VERSION ""

NS_ :

BS_:

BU_: WCM4 WCM3 WCM2 WCM VPM VLM VKM VICM VECM VDM VCU_RTOS_ETH VCU_ENTRY_ETH VCU_AGVM_ETH VCU UVM UPM TIM TEST_TOOL_1 TCP_ETH TCP TCM TCCM SRR_SRR_ETH SRR_SRR SRR_SLR_ETH SRR_SLR SRR_RR SRR_RF_ETH SRR_RF SRR_LR_CR SRR_LF_ETH SRR_LF SIB SDM SCL SBZA_R SBZA_L SBM SAM_RR SAM_RF SAM_LR SAM_LF SAM_BH SADS RadioLow_ETH RadioLow RSI_RTOS_ETH RSI RDCM PTM PLCM PFCM PDR_ETH PDR PCM PA ODS2 ODS NVM MTCM_R MTCM_L MSM_RR MSM_P MSM_LR MSM_D MSB2 MSB1 MRCM_R MRCM_L MFC LRR_RR_ETH LRR_LR_ETH LRR_CF_ETH LRR LRL_CF_ETH LIB_48V LIB1 IPC_INT IPC_GP IPC ICS_Info ICCM HVAC_FP_R HVAC_FP_F HUD_CAN HDLM FPI_RTOS_ETH FPI FOPM FCM_LC FCM EPSb EPS_1 EPSRAb EPSRAa EPS EOCM_HC_Superset EOCM_HCP2 EOCM ELM ECP_X1 ECP_S2 ECP_S ECP_MC ECP_H3 ECP_H2 ECP_H1 ECP_E ECM EBCM DMS DEFC DCM CSM_ETH CSM_AV CSM CGM_OTA_ETH CGM BSM_MH BSM_HEV BSM BCM ARS ARB APA AOS AMP ALC AHS AHL_AFL ADIMb ADIMa ACP2_MCU

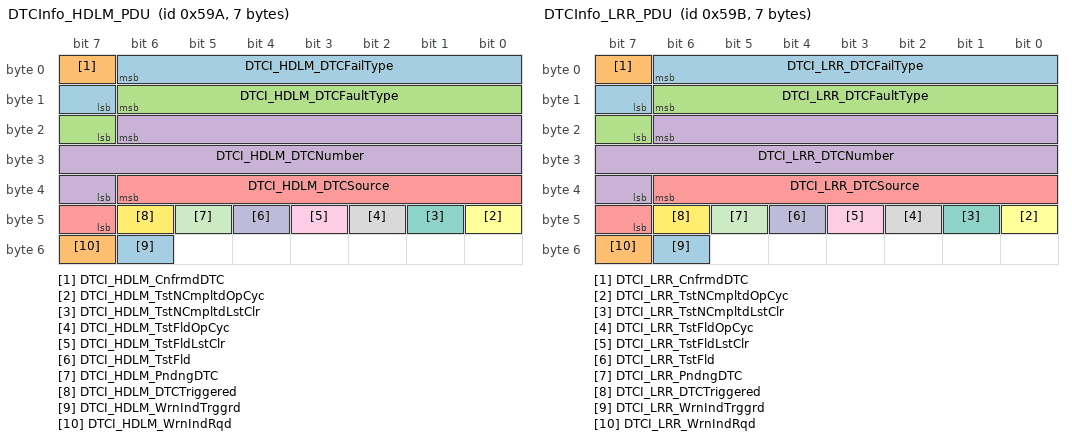
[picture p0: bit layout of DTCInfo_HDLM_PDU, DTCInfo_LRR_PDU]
BO_ 1434 DTCInfo_HDLM_PDU: 7 HDLM
 SG_ DTCI_HDLM_DTCFailType : 6|8@0+ (1,0) [0|255] "" CGM
 SG_ DTCI_HDLM_CnfrmdDTC : 7|1@0+ (1,0) [0|1] "" CGM
 SG_ DTCI_HDLM_DTCFaultType : 14|8@0+ (1,0) [0|3] "" CGM
 SG_ DTCI_HDLM_DTCNumber : 22|16@0+ (1,0) [0|65535] "" CGM
 SG_ DTCI_HDLM_DTCSource : 38|8@0+ (1,0) [0|255] "" CGM
 SG_ DTCI_HDLM_TstNCmpltdOpCyc : 40|1@0+ (1,0) [0|1] "" CGM
 SG_ DTCI_HDLM_TstNCmpltdLstClr : 41|1@0+ (1,0) [0|1] "" CGM
 SG_ DTCI_HDLM_TstFldOpCyc : 42|1@0+ (1,0) [0|1] "" CGM
 SG_ DTCI_HDLM_TstFldLstClr : 43|1@0+ (1,0) [0|1] "" CGM
 SG_ DTCI_HDLM_TstFld : 44|1@0+ (1,0) [0|1] "" CGM
 SG_ DTCI_HDLM_PndngDTC : 45|1@0+ (1,0) [0|1] "" CGM
 SG_ DTCI_HDLM_DTCTriggered : 46|1@0+ (1,0) [0|1] "" CGM
 SG_ DTCI_HDLM_WrnIndTrggrd : 54|1@0+ (1,0) [0|1] "" CGM
 SG_ DTCI_HDLM_WrnIndRqd : 55|1@0+ (1,0) [0|1] "" CGM

BO_ 1435 DTCInfo_LRR_PDU: 7 LRR
 SG_ DTCI_LRR_DTCFailType : 6|8@0+ (1,0) [0|255] "" CGM
 SG_ DTCI_LRR_CnfrmdDTC : 7|1@0+ (1,0) [0|1] "" CGM
 SG_ DTCI_LRR_DTCFaultType : 14|8@0+ (1,0) [0|3] "" CGM
 SG_ DTCI_LRR_DTCNumber : 22|16@0+ (1,0) [0|65535] "" CGM
 SG_ DTCI_LRR_DTCSource : 38|8@0+ (1,0) [0|255] "" CGM
 SG_ DTCI_LRR_TstNCmpltdOpCyc : 40|1@0+ (1,0) [0|1] "" CGM
 SG_ DTCI_LRR_TstNCmpltdLstClr : 41|1@0+ (1,0) [0|1] "" CGM
 SG_ DTCI_LRR_TstFldOpCyc : 42|1@0+ (1,0) [0|1] "" CGM
 SG_ DTCI_LRR_TstFldLstClr : 43|1@0+ (1,0) [0|1] "" CGM
 SG_ DTCI_LRR_TstFld : 44|1@0+ (1,0) [0|1] "" CGM
 SG_ DTCI_LRR_PndngDTC : 45|1@0+ (1,0) [0|1] "" CGM
 SG_ DTCI_LRR_DTCTriggered : 46|1@0+ (1,0) [0|1] "" CGM
 SG_ DTCI_LRR_WrnIndTrggrd : 54|1@0+ (1,0) [0|1] "" CGM
 SG_ DTCI_LRR_WrnIndRqd : 55|1@0+ (1,0) [0|1] "" CGM

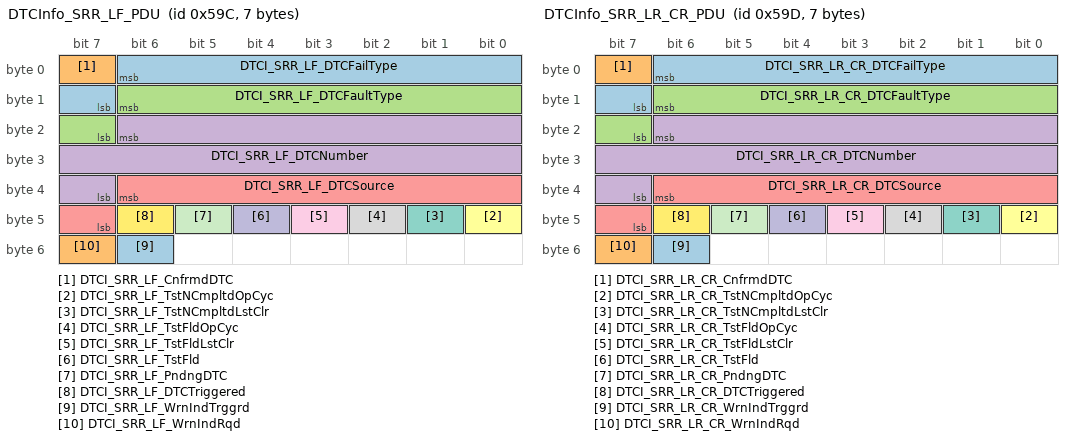
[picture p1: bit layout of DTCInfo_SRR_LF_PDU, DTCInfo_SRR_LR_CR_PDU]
BO_ 1436 DTCInfo_SRR_LF_PDU: 7 SRR_LF
 SG_ DTCI_SRR_LF_DTCFailType : 6|8@0+ (1,0) [0|255] "" CGM
 SG_ DTCI_SRR_LF_CnfrmdDTC : 7|1@0+ (1,0) [0|1] "" CGM
 SG_ DTCI_SRR_LF_DTCFaultType : 14|8@0+ (1,0) [0|3] "" CGM
 SG_ DTCI_SRR_LF_DTCNumber : 22|16@0+ (1,0) [0|65535] "" CGM
 SG_ DTCI_SRR_LF_DTCSource : 38|8@0+ (1,0) [0|255] "" CGM
 SG_ DTCI_SRR_LF_TstNCmpltdOpCyc : 40|1@0+ (1,0) [0|1] "" CGM
 SG_ DTCI_SRR_LF_TstNCmpltdLstClr : 41|1@0+ (1,0) [0|1] "" CGM
 SG_ DTCI_SRR_LF_TstFldOpCyc : 42|1@0+ (1,0) [0|1] "" CGM
 SG_ DTCI_SRR_LF_TstFldLstClr : 43|1@0+ (1,0) [0|1] "" CGM
 SG_ DTCI_SRR_LF_TstFld : 44|1@0+ (1,0) [0|1] "" CGM
 SG_ DTCI_SRR_LF_PndngDTC : 45|1@0+ (1,0) [0|1] "" CGM
 SG_ DTCI_SRR_LF_DTCTriggered : 46|1@0+ (1,0) [0|1] "" CGM
 SG_ DTCI_SRR_LF_WrnIndTrggrd : 54|1@0+ (1,0) [0|1] "" CGM
 SG_ DTCI_SRR_LF_WrnIndRqd : 55|1@0+ (1,0) [0|1] "" CGM

BO_ 1437 DTCInfo_SRR_LR_CR_PDU: 7 SRR_LR_CR
 SG_ DTCI_SRR_LR_CR_DTCFailType : 6|8@0+ (1,0) [0|255] "" CGM
 SG_ DTCI_SRR_LR_CR_CnfrmdDTC : 7|1@0+ (1,0) [0|1] "" CGM
 SG_ DTCI_SRR_LR_CR_DTCFaultType : 14|8@0+ (1,0) [0|3] "" CGM
 SG_ DTCI_SRR_LR_CR_DTCNumber : 22|16@0+ (1,0) [0|65535] "" CGM
 SG_ DTCI_SRR_LR_CR_DTCSource : 38|8@0+ (1,0) [0|255] "" CGM
 SG_ DTCI_SRR_LR_CR_TstNCmpltdOpCyc : 40|1@0+ (1,0) [0|1] "" CGM
 SG_ DTCI_SRR_LR_CR_TstNCmpltdLstClr : 41|1@0+ (1,0) [0|1] "" CGM
 SG_ DTCI_SRR_LR_CR_TstFldOpCyc : 42|1@0+ (1,0) [0|1] "" CGM
 SG_ DTCI_SRR_LR_CR_TstFldLstClr : 43|1@0+ (1,0) [0|1] "" CGM
 SG_ DTCI_SRR_LR_CR_TstFld : 44|1@0+ (1,0) [0|1] "" CGM
 SG_ DTCI_SRR_LR_CR_PndngDTC : 45|1@0+ (1,0) [0|1] "" CGM
 SG_ DTCI_SRR_LR_CR_DTCTriggered : 46|1@0+ (1,0) [0|1] "" CGM
 SG_ DTCI_SRR_LR_CR_WrnIndTrggrd : 54|1@0+ (1,0) [0|1] "" CGM
 SG_ DTCI_SRR_LR_CR_WrnIndRqd : 55|1@0+ (1,0) [0|1] "" CGM

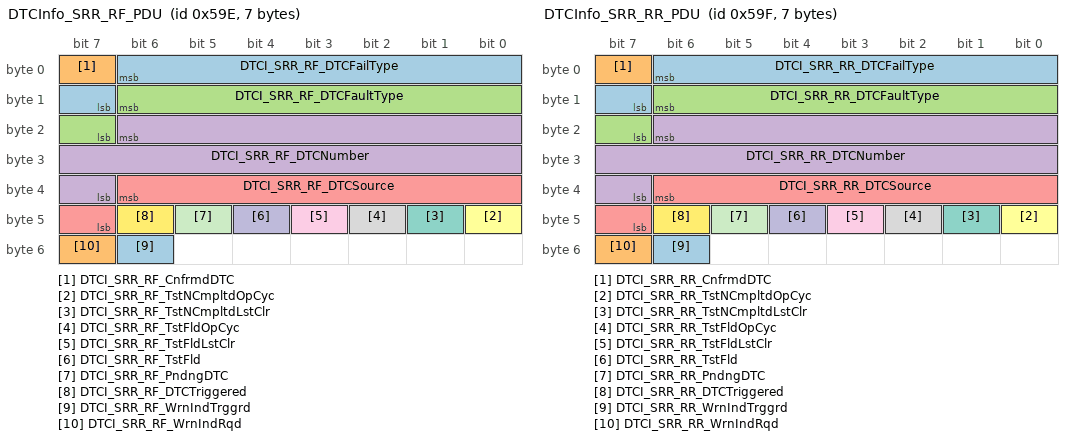
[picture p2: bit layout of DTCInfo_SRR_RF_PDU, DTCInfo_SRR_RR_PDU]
BO_ 1438 DTCInfo_SRR_RF_PDU: 7 SRR_RF
 SG_ DTCI_SRR_RF_DTCFailType : 6|8@0+ (1,0) [0|255] "" CGM
 SG_ DTCI_SRR_RF_CnfrmdDTC : 7|1@0+ (1,0) [0|1] "" CGM
 SG_ DTCI_SRR_RF_DTCFaultType : 14|8@0+ (1,0) [0|3] "" CGM
 SG_ DTCI_SRR_RF_DTCNumber : 22|16@0+ (1,0) [0|65535] "" CGM
 SG_ DTCI_SRR_RF_DTCSource : 38|8@0+ (1,0) [0|255] "" CGM
 SG_ DTCI_SRR_RF_TstNCmpltdOpCyc : 40|1@0+ (1,0) [0|1] "" CGM
 SG_ DTCI_SRR_RF_TstNCmpltdLstClr : 41|1@0+ (1,0) [0|1] "" CGM
 SG_ DTCI_SRR_RF_TstFldOpCyc : 42|1@0+ (1,0) [0|1] "" CGM
 SG_ DTCI_SRR_RF_TstFldLstClr : 43|1@0+ (1,0) [0|1] "" CGM
 SG_ DTCI_SRR_RF_TstFld : 44|1@0+ (1,0) [0|1] "" CGM
 SG_ DTCI_SRR_RF_PndngDTC : 45|1@0+ (1,0) [0|1] "" CGM
 SG_ DTCI_SRR_RF_DTCTriggered : 46|1@0+ (1,0) [0|1] "" CGM
 SG_ DTCI_SRR_RF_WrnIndTrggrd : 54|1@0+ (1,0) [0|1] "" CGM
 SG_ DTCI_SRR_RF_WrnIndRqd : 55|1@0+ (1,0) [0|1] "" CGM

BO_ 1439 DTCInfo_SRR_RR_PDU: 7 SRR_RR
 SG_ DTCI_SRR_RR_DTCFailType : 6|8@0+ (1,0) [0|255] "" CGM
 SG_ DTCI_SRR_RR_CnfrmdDTC : 7|1@0+ (1,0) [0|1] "" CGM
 SG_ DTCI_SRR_RR_DTCFaultType : 14|8@0+ (1,0) [0|3] "" CGM
 SG_ DTCI_SRR_RR_DTCNumber : 22|16@0+ (1,0) [0|65535] "" CGM
 SG_ DTCI_SRR_RR_DTCSource : 38|8@0+ (1,0) [0|255] "" CGM
 SG_ DTCI_SRR_RR_TstNCmpltdOpCyc : 40|1@0+ (1,0) [0|1] "" CGM
 SG_ DTCI_SRR_RR_TstNCmpltdLstClr : 41|1@0+ (1,0) [0|1] "" CGM
 SG_ DTCI_SRR_RR_TstFldOpCyc : 42|1@0+ (1,0) [0|1] "" CGM
 SG_ DTCI_SRR_RR_TstFldLstClr : 43|1@0+ (1,0) [0|1] "" CGM
 SG_ DTCI_SRR_RR_TstFld : 44|1@0+ (1,0) [0|1] "" CGM
 SG_ DTCI_SRR_RR_PndngDTC : 45|1@0+ (1,0) [0|1] "" CGM
 SG_ DTCI_SRR_RR_DTCTriggered : 46|1@0+ (1,0) [0|1] "" CGM
 SG_ DTCI_SRR_RR_WrnIndTrggrd : 54|1@0+ (1,0) [0|1] "" CGM
 SG_ DTCI_SRR_RR_WrnIndRqd : 55|1@0+ (1,0) [0|1] "" CGM

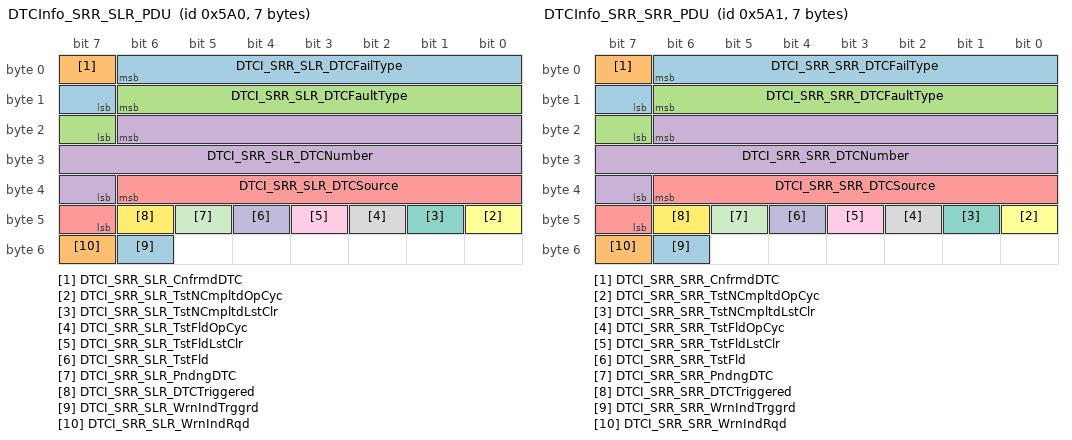
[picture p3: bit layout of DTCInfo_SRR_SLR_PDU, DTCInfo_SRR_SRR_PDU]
BO_ 1440 DTCInfo_SRR_SLR_PDU: 7 SRR_SLR
 SG_ DTCI_SRR_SLR_DTCFailType : 6|8@0+ (1,0) [0|255] "" CGM
 SG_ DTCI_SRR_SLR_CnfrmdDTC : 7|1@0+ (1,0) [0|1] "" CGM
 SG_ DTCI_SRR_SLR_DTCFaultType : 14|8@0+ (1,0) [0|3] "" CGM
 SG_ DTCI_SRR_SLR_DTCNumber : 22|16@0+ (1,0) [0|65535] "" CGM
 SG_ DTCI_SRR_SLR_DTCSource : 38|8@0+ (1,0) [0|255] "" CGM
 SG_ DTCI_SRR_SLR_TstNCmpltdOpCyc : 40|1@0+ (1,0) [0|1] "" CGM
 SG_ DTCI_SRR_SLR_TstNCmpltdLstClr : 41|1@0+ (1,0) [0|1] "" CGM
 SG_ DTCI_SRR_SLR_TstFldOpCyc : 42|1@0+ (1,0) [0|1] "" CGM
 SG_ DTCI_SRR_SLR_TstFldLstClr : 43|1@0+ (1,0) [0|1] "" CGM
 SG_ DTCI_SRR_SLR_TstFld : 44|1@0+ (1,0) [0|1] "" CGM
 SG_ DTCI_SRR_SLR_PndngDTC : 45|1@0+ (1,0) [0|1] "" CGM
 SG_ DTCI_SRR_SLR_DTCTriggered : 46|1@0+ (1,0) [0|1] "" CGM
 SG_ DTCI_SRR_SLR_WrnIndTrggrd : 54|1@0+ (1,0) [0|1] "" CGM
 SG_ DTCI_SRR_SLR_WrnIndRqd : 55|1@0+ (1,0) [0|1] "" CGM

BO_ 1441 DTCInfo_SRR_SRR_PDU: 7 SRR_SRR
 SG_ DTCI_SRR_SRR_DTCFailType : 6|8@0+ (1,0) [0|255] "" CGM
 SG_ DTCI_SRR_SRR_CnfrmdDTC : 7|1@0+ (1,0) [0|1] "" CGM
 SG_ DTCI_SRR_SRR_DTCFaultType : 14|8@0+ (1,0) [0|3] "" CGM
 SG_ DTCI_SRR_SRR_DTCNumber : 22|16@0+ (1,0) [0|65535] "" CGM
 SG_ DTCI_SRR_SRR_DTCSource : 38|8@0+ (1,0) [0|255] "" CGM
 SG_ DTCI_SRR_SRR_TstNCmpltdOpCyc : 40|1@0+ (1,0) [0|1] "" CGM
 SG_ DTCI_SRR_SRR_TstNCmpltdLstClr : 41|1@0+ (1,0) [0|1] "" CGM
 SG_ DTCI_SRR_SRR_TstFldOpCyc : 42|1@0+ (1,0) [0|1] "" CGM
 SG_ DTCI_SRR_SRR_TstFldLstClr : 43|1@0+ (1,0) [0|1] "" CGM
 SG_ DTCI_SRR_SRR_TstFld : 44|1@0+ (1,0) [0|1] "" CGM
 SG_ DTCI_SRR_SRR_PndngDTC : 45|1@0+ (1,0) [0|1] "" CGM
 SG_ DTCI_SRR_SRR_DTCTriggered : 46|1@0+ (1,0) [0|1] "" CGM
 SG_ DTCI_SRR_SRR_WrnIndTrggrd : 54|1@0+ (1,0) [0|1] "" CGM
 SG_ DTCI_SRR_SRR_WrnIndRqd : 55|1@0+ (1,0) [0|1] "" CGM

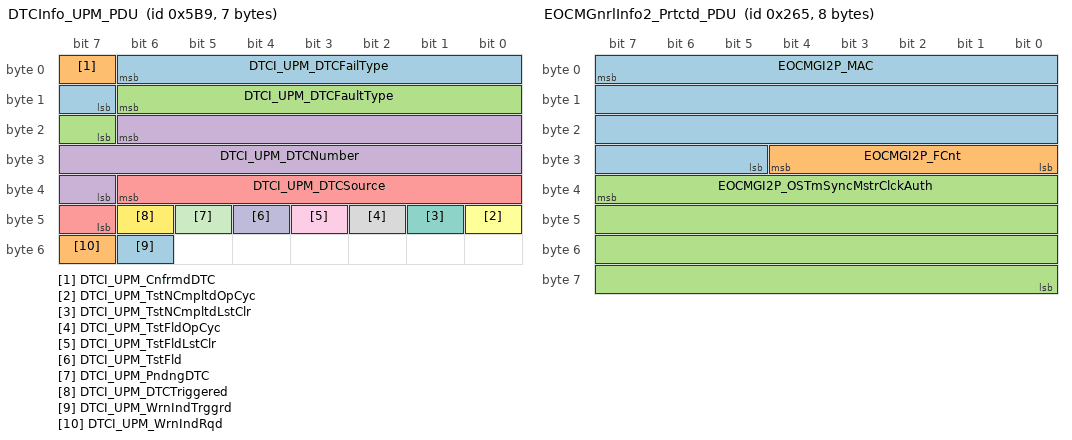
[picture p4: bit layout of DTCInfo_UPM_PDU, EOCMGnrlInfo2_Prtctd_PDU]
BO_ 1465 DTCInfo_UPM_PDU: 7 UPM
 SG_ DTCI_UPM_DTCFailType : 6|8@0+ (1,0) [0|255] "" CGM
 SG_ DTCI_UPM_CnfrmdDTC : 7|1@0+ (1,0) [0|1] "" CGM
 SG_ DTCI_UPM_DTCFaultType : 14|8@0+ (1,0) [0|3] "" CGM
 SG_ DTCI_UPM_DTCNumber : 22|16@0+ (1,0) [0|65535] "" CGM
 SG_ DTCI_UPM_DTCSource : 38|8@0+ (1,0) [0|255] "" CGM
 SG_ DTCI_UPM_TstNCmpltdOpCyc : 40|1@0+ (1,0) [0|1] "" CGM
 SG_ DTCI_UPM_TstNCmpltdLstClr : 41|1@0+ (1,0) [0|1] "" CGM
 SG_ DTCI_UPM_TstFldOpCyc : 42|1@0+ (1,0) [0|1] "" CGM
 SG_ DTCI_UPM_TstFldLstClr : 43|1@0+ (1,0) [0|1] "" CGM
 SG_ DTCI_UPM_TstFld : 44|1@0+ (1,0) [0|1] "" CGM
 SG_ DTCI_UPM_PndngDTC : 45|1@0+ (1,0) [0|1] "" CGM
 SG_ DTCI_UPM_DTCTriggered : 46|1@0+ (1,0) [0|1] "" CGM
 SG_ DTCI_UPM_WrnIndTrggrd : 54|1@0+ (1,0) [0|1] "" CGM
 SG_ DTCI_UPM_WrnIndRqd : 55|1@0+ (1,0) [0|1] "" CGM

BO_ 928 EB_PDU_8000: 1 CGM
 SG_ EASSI_StrtStpSt : 7|2@0+ (1,0) [0|3] "" HDLM

BO_ 1407 EB_PDU_8001: 1 CGM
 SG_ ACCAutoStSpStat : 7|2@0+ (1,0) [0|3] "" FCM_LC

BO_ 705 EB_PDU_8002: 1 CGM
 SG_ EPBSP_ElecPrkBrkApplStsAuth : 7|3@0+ (1,0) [0|4] "" SRR_SLR,SRR_SRR

BO_ 671 EOCMGnrlInfo1_PCSM_PDU: 8 ACP2_MCU
 SG_ EOCMGnrlInfo1_PCSM : 0|64@1+ (1,0) [0|1.84467e+019] "" Vector__XXX

BO_ 528 EOCMGnrlInfo1_Prtctd_PDU: 12 ACP2_MCU
 SG_ FIMRIMABP_MAC : 7|32@0+ (1,0) [0|4.29497e+009] "" CGM
 SG_ FIMRIMABP_FCnt : 39|5@0+ (1,0) [0|31] "" CGM
 SG_ FIMRIMABP_BrkgCtlAccelAuth : 47|12@0+ (0.01,-20.48) [-20.48|20.47] "" CGM
 SG_ FIMRIMABP_BrkgLongAccelReqAuth : 51|9@0- (0.1,0) [-25.6|25.5] "" CGM
 SG_ FIMRIMABP_FIMCISAutBrkRqTypAuth : 57|2@0+ (1,0) [0|2] "" CGM
 SG_ FIMRIMABP_BrkgReqAuth : 58|1@0+ (1,0) [0|1] "" CGM
 SG_ RIMATRP_TrqRqstAuth : 68|16@0- (2,0) [-65536|65534] "" CGM
 SG_ RIMATRP_TrqRqstActAuth : 69|1@0+ (1,0) [0|1] "" CGM
 SG_ FIMRIMABP_ReqActvAuth : 70|1@0+ (1,0) [0|1] "" CGM
 SG_ FIMRIMABP_RIMAutoBrkgReqTypAuth : 71|1@0+ (1,0) [0|1] "" CGM
 SG_ EOCMGI1P_Filler : 82|11@0+ (1,0) [0|2047] "" CGM
 SG_ FIMRIMABP_ARC : 84|2@0+ (1,0) [0|3] "" CGM

BO_ 1401 EOCMGnrlInfo2_PCSM_PDU: 8 ACP2_MCU
 SG_ EOCMGnrlInfo2_PCSM : 0|64@1+ (1,0) [0|1.84467e+019] "" Vector__XXX

BO_ 613 EOCMGnrlInfo2_Prtctd_PDU: 8 ACP2_MCU
 SG_ EOCMGI2P_MAC : 7|27@0+ (1,0) [0|1.34218e+008] "" Vector__XXX
 SG_ EOCMGI2P_FCnt : 28|5@0+ (1,0) [0|31] "" Vector__XXX
 SG_ EOCMGI2P_OSTmSyncMstrClckAuth : 39|32@0+ (1,0) [0|4.29497e+009] "ms" Vector__XXX

BO_ 2147745797 EOCM_CAN8_ClscCANHrtBtActv_PDU: 1 EOCM
 SG_ EOCM_CAN8_ClscCANHrtBtActv : 7|1@0+ (1,0) [0|1] "" CGM

BO_ 2147745798 EOCM_HCP1_CAN8_ClscCANHrtBtActv_: 1 EOCM_HC_Superset
 SG_ EOCM_HCP1_CAN8_ClscCANHrtBtActv : 7|1@0+ (1,0) [0|1] "" CGM

BO_ 2147745808 EOCM_HCP2_CAN8_ClscCANHrtBtActv_: 1 EOCM_HCP2
 SG_ EOCM_HCP2_CAN8_ClscCANHrtBtActv : 7|1@0+ (1,0) [0|1] "" CGM

BO_ 2147745809 FCM_LC_CAN8_ClscCANHrtBtActv_PDU: 1 FCM_LC
 SG_ FCM_LC_CAN8_ClscCANHrtBtActv : 7|1@0+ (1,0) [0|1] "" CGM

BO_ 658 FCODP_BrstGrp_PCSM_PDU: 8 ACP2_MCU
 SG_ FCODP_BrstGrp1_PCSM : 0|64@1+ (1,0) [0|1.84467e+019] "" EOCM,EOCM_HCP2,EOCM_HC_Superset,HDLM

BO_ 238 FCODP_BrstGrp_Prtctd_Consecutive: 64 ACP2_MCU
 SG_ FCODPB11P_FVVOTk10PoI4LgPsAuth : 5|11@0+ (0.125,0) [0|255.875] "m" EOCM,EOCM_HCP2,EOCM_HC_Superset,HDLM
 SG_ FCODPB11P_BrstID : 7|2@0+ (1,0) [0|3] "" EOCM,EOCM_HCP2,EOCM_HC_Superset,HDLM
 SG_ FCODPB11P_FVVOTk10PoI4LPsAuth : 10|10@0+ (0.125,-64) [-64|63.875] "m" EOCM,EOCM_HCP2,EOCM_HC_Superset,HDLM
 SG_ FCODPB11P_FVVOTk10PoI4PsVisAuth : 16|2@0+ (1,0) [0|2] "" EOCM,EOCM_HCP2,EOCM_HC_Superset,HDLM
 SG_ FCODPB11P_FVVOTk1PoI4LgPsAuth : 30|11@0+ (0.125,0) [0|255.875] "m" EOCM,EOCM_HCP2,EOCM_HC_Superset,HDLM
 SG_ FCODPB11P_FVVOTk1PoI4LPsAuth : 35|10@0+ (0.125,-64) [-64|63.875] "m" EOCM,EOCM_HCP2,EOCM_HC_Superset,HDLM
 SG_ FCODPB11P_FVVOTk1PoI4PsVisAuth : 41|2@0+ (1,0) [0|2] "" EOCM,EOCM_HCP2,EOCM_HC_Superset,HDLM
 SG_ FCODPB11P_FVVOTk2PoI4LgPsAuth : 55|11@0+ (0.125,0) [0|255.875] "m" EOCM,EOCM_HCP2,EOCM_HC_Superset,HDLM
 SG_ FCODPB11P_FVVOTk2PoI4LPsAuth : 60|10@0+ (0.125,-64) [-64|63.875] "m" EOCM,EOCM_HCP2,EOCM_HC_Superset,HDLM
 SG_ FCODPB11P_FVVOTk3PoI4LgPsAuth : 64|11@0+ (0.125,0) [0|255.875] "m" EOCM,EOCM_HCP2,EOCM_HC_Superset,HDLM
 SG_ FCODPB11P_FVVOTk2PoI4PsVisAuth : 66|2@0+ (1,0) [0|2] "" EOCM,EOCM_HCP2,EOCM_HC_Superset,HDLM
 SG_ FCODPB11P_FVVOTk3PoI4LPsAuth : 85|10@0+ (0.125,-64) [-64|63.875] "m" EOCM,EOCM_HCP2,EOCM_HC_Superset,HDLM
 SG_ FCODPB11P_FVVOTk4PoI4LgPsAuth : 89|11@0+ (0.125,0) [0|255.875] "m" EOCM,EOCM_HCP2,EOCM_HC_Superset,HDLM
 SG_ FCODPB11P_FVVOTk3PoI4PsVisAuth : 91|2@0+ (1,0) [0|2] "" EOCM,EOCM_HCP2,EOCM_HC_Superset,HDLM
 SG_ FCODPB11P_FVVOTk4PoI4LPsAuth : 110|10@0+ (0.125,-64) [-64|63.875] "m" EOCM,EOCM_HCP2,EOCM_HC_Superset,HDLM
 SG_ FCODPB11P_FVVOTk5PoI4LgPsAuth : 114|11@0+ (0.125,0) [0|255.875] "m" EOCM,EOCM_HCP2,EOCM_HC_Superset,HDLM
 SG_ FCODPB11P_FVVOTk4PoI4PsVisAuth : 116|2@0+ (1,0) [0|2] "" EOCM,EOCM_HCP2,EOCM_HC_Superset,HDLM
 SG_ FCODPB11P_FVVOTk5PoI4LPsAuth : 135|10@0+ (0.125,-64) [-64|63.875] "m" EOCM,EOCM_HCP2,EOCM_HC_Superset,HDLM
 SG_ FCODPB11P_FVVOTk6PoI4LgPsAuth : 139|11@0+ (0.125,0) [0|255.875] "m" EOCM,EOCM_HCP2,EOCM_HC_Superset,HDLM
 SG_ FCODPB11P_FVVOTk5PoI4PsVisAuth : 141|2@0+ (1,0) [0|2] "" EOCM,EOCM_HCP2,EOCM_HC_Superset,HDLM
 SG_ FCODPB11P_FVVOTk6PoI4LPsAuth : 144|10@0+ (0.125,-64) [-64|63.875] "m" EOCM,EOCM_HCP2,EOCM_HC_Superset,HDLM
 SG_ FCODPB11P_FVVOTk7PoI4LgPsAuth : 164|11@0+ (0.125,0) [0|255.875] "m" EOCM,EOCM_HCP2,EOCM_HC_Superset,HDLM
 SG_ FCODPB11P_FVVOTk6PoI4PsVisAuth : 166|2@0+ (1,0) [0|2] "" EOCM,EOCM_HCP2,EOCM_HC_Superset,HDLM
 SG_ FCODPB11P_FVVOTk7PoI4LPsAuth : 169|10@0+ (0.125,-64) [-64|63.875] "m" EOCM,EOCM_HCP2,EOCM_HC_Superset,HDLM
 SG_ FCODPB11P_FVVOTk8PoI4LgPsAuth : 189|11@0+ (0.125,0) [0|255.875] "m" EOCM,EOCM_HCP2,EOCM_HC_Superset,HDLM
 SG_ FCODPB11P_FVVOTk7PoI4PsVisAuth : 191|2@0+ (1,0) [0|2] "" EOCM,EOCM_HCP2,EOCM_HC_Superset,HDLM
 SG_ FCODPB11P_FVVOTk8PoI4LPsAuth : 194|10@0+ (0.125,-64) [-64|63.875] "m" EOCM,EOCM_HCP2,EOCM_HC_Superset,HDLM
 SG_ FCODPB11P_FVVOTk8PoI4PsVisAuth : 200|2@0+ (1,0) [0|2] "" EOCM,EOCM_HCP2,EOCM_HC_Superset,HDLM
 SG_ FCODPB11P_FVVOTk9PoI4LgPsAuth : 214|11@0+ (0.125,0) [0|255.875] "m" EOCM,EOCM_HCP2,EOCM_HC_Superset,HDLM
 SG_ FCODPB11P_FVVOTk9PoI4LPsAuth : 219|10@0+ (0.125,-64) [-64|63.875] "m" EOCM,EOCM_HCP2,EOCM_HC_Superset,HDLM
 SG_ FCODPB11P_FVVOTk9PoI4PsVisAuth : 225|2@0+ (1,0) [0|2] "" EOCM,EOCM_HCP2,EOCM_HC_Superset,HDLM
 SG_ FCODPB11P_LnTrPtEndLatDistAuth : 239|12@0- (0.01,0) [-20.48|20.47] "m" EOCM,EOCM_HCP2,EOCM_HC_Superset,HDLM
 SG_ FCODPB11P_LnTrPtEndLngDistAuth : 243|14@0+ (0.01,0) [0|163.83] "m" EOCM,EOCM_HCP2,EOCM_HC_Superset,HDLM
 SG_ FCODPB11P_LnTrPtStrtLatDistAuth : 259|12@0- (0.01,0) [-20.48|20.47] "m" EOCM,EOCM_HCP2,EOCM_HC_Superset,HDLM
 SG_ FCODPB11P_LnTrPtEndTypAuth : 261|2@0+ (1,0) [0|2] "" EOCM,EOCM_HCP2,EOCM_HC_Superset,HDLM
 SG_ FCODPB11P_LnTrPtStrtLngDistAuth : 279|14@0+ (0.01,0) [0|163.83] "m" EOCM,EOCM_HCP2,EOCM_HC_Superset,HDLM
 SG_ FCODPB11P_LnTrPtStrtTypAuth : 281|2@0+ (1,0) [0|2] "" EOCM,EOCM_HCP2,EOCM_HC_Superset,HDLM
 SG_ FCODPB11P_RdVertPP10LngDistAuth : 292|10@0+ (0.125,0) [0|127.875] "m" EOCM,EOCM_HCP2,EOCM_HC_Superset,HDLM
 SG_ FCODPB11P_FrwdVsnModeCmdStsAuth : 293|1@0+ (1,0) [0|1] "" EOCM,EOCM_HCP2,EOCM_HC_Superset,HDLM
 SG_ FCODPB11P_LnTrPtSyncIdxAuth : 295|2@0+ (1,0) [0|3] "" EOCM,EOCM_HCP2,EOCM_HC_Superset,HDLM
 SG_ FCODPB11P_RdVertPP11LngDistAuth : 298|10@0+ (0.125,0) [0|127.875] "m" EOCM,EOCM_HCP2,EOCM_HC_Superset,HDLM
 SG_ FCODPB11P_RdVertPP12LngDistAuth : 304|10@0+ (0.125,0) [0|127.875] "m" EOCM,EOCM_HCP2,EOCM_HC_Superset,HDLM
 SG_ FCODPB11P_RdVertPP13LngDistAuth : 326|10@0+ (0.125,0) [0|127.875] "m" EOCM,EOCM_HCP2,EOCM_HC_Superset,HDLM
 SG_ FCODPB11P_RdVertPP14LngDistAuth : 332|10@0+ (0.125,0) [0|127.875] "m" EOCM,EOCM_HCP2,EOCM_HC_Superset,HDLM
 SG_ FCODPB11P_RdVertPP15LngDistAuth : 338|10@0+ (0.125,0) [0|127.875] "m" EOCM,EOCM_HCP2,EOCM_HC_Superset,HDLM
 SG_ FCODPB11P_RdVertPP1LngDistAuth : 344|10@0+ (0.125,0) [0|127.875] "m" EOCM,EOCM_HCP2,EOCM_HC_Superset,HDLM
 SG_ FCODPB11P_RdVertPP2LngDistAuth : 366|10@0+ (0.125,0) [0|127.875] "m" EOCM,EOCM_HCP2,EOCM_HC_Superset,HDLM
 SG_ FCODPB11P_RdVertPP3LngDistAuth : 372|10@0+ (0.125,0) [0|127.875] "m" EOCM,EOCM_HCP2,EOCM_HC_Superset,HDLM
 SG_ FCODPB11P_RdVertPP4LngDistAuth : 378|10@0+ (0.125,0) [0|127.875] "m" EOCM,EOCM_HCP2,EOCM_HC_Superset,HDLM
 SG_ FCODPB11P_RdVertPP5LngDistAuth : 384|10@0+ (0.125,0) [0|127.875] "m" EOCM,EOCM_HCP2,EOCM_HC_Superset,HDLM
 SG_ FCODPB11P_RdVertPP6LngDistAuth : 406|10@0+ (0.125,0) [0|127.875] "m" EOCM,EOCM_HCP2,EOCM_HC_Superset,HDLM
 SG_ FCODPB11P_RdVertPP7LngDistAuth : 412|10@0+ (0.125,0) [0|127.875] "m" EOCM,EOCM_HCP2,EOCM_HC_Superset,HDLM
 SG_ FCODPB11P_RdVertPP8LngDistAuth : 418|10@0+ (0.125,0) [0|127.875] "m" EOCM,EOCM_HCP2,EOCM_HC_Superset,HDLM
 SG_ FCODPB11P_RdVertPP9LngDistAuth : 424|10@0+ (0.125,0) [0|127.875] "m" EOCM,EOCM_HCP2,EOCM_HC_Superset,HDLM
 SG_ FCODPB11P_Filler : 440|30@0+ (1,0) [0|1.07374e+009] "" EOCM,EOCM_HCP2,EOCM_HC_Superset,HDLM
 SG_ FrwdVsnLnBdryTk11DatIntegCkd : 442|2@0+ (1,0) [0|2] "" EOCM,EOCM_HCP2,EOCM_HC_Superset,HDLM
 SG_ FCODPB11P_ShldrDtnRtofVehAuth : 444|2@0+ (1,0) [0|3] "" EOCM,EOCM_HCP2,EOCM_HC_Superset,HDLM
 SG_ FCODPB11P_ShldrDtnLtofVehAuth : 446|2@0+ (1,0) [0|3] "" EOCM,EOCM_HCP2,EOCM_HC_Superset,HDLM
 SG_ FCODPB11P_FillerExtnd : 474|32@0+ (1,0) [0|4.29497e+009] "" EOCM,EOCM_HCP2,EOCM_HC_Superset,HDLM
 SG_ FCODPB11P_FillerExtnd1 : 506|3@0+ (1,0) [0|7] "0" EOCM,EOCM_HCP2,EOCM_HC_Superset,HDLM

BO_ 217 FCODP_BrstGrp_Prtctd_Consecuti01: 64 ACP2_MCU
 SG_ FCODPB12P_FVTS1AgeAuth : 5|8@0+ (1,0) [0|255] "Frames" EOCM,EOCM_HCP2,EOCM_HC_Superset,HDLM
 SG_ FCODPB12P_BrstID : 7|2@0+ (1,0) [0|3] "" EOCM,EOCM_HCP2,EOCM_HC_Superset,HDLM
 SG_ FCODPB12P_FVTS1PsdbyHstVehAuth : 8|1@0+ (1,0) [0|1] "" EOCM,EOCM_HCP2,EOCM_HC_Superset,HDLM
 SG_ FCODPB12P_FVTS1PhysTypAuth : 10|2@0+ (1,0) [0|2] "" EOCM,EOCM_HCP2,EOCM_HC_Superset,HDLM
 SG_ FCODPB12P_FVTS1MeasVldAuth : 11|1@0+ (1,0) [0|1] "" EOCM,EOCM_HCP2,EOCM_HC_Superset,HDLM
 SG_ FCODPB12P_FVTS1FiltTypAuth : 13|2@0+ (1,0) [0|3] "" EOCM,EOCM_HCP2,EOCM_HC_Superset,HDLM
 SG_ FCODPB12P_FVTS2AgeAuth : 22|8@0+ (1,0) [0|255] "Frames" EOCM,EOCM_HCP2,EOCM_HC_Superset,HDLM
 SG_ FCODPB12P_FVTS1ZnDtdAuth : 23|1@0+ (1,0) [0|1] "" EOCM,EOCM_HCP2,EOCM_HC_Superset,HDLM
 SG_ FCODPB12P_FVTS2ZnDtdAuth : 24|1@0+ (1,0) [0|1] "" EOCM,EOCM_HCP2,EOCM_HC_Superset,HDLM
 SG_ FCODPB12P_FVTS2PsdbyHstVehAuth : 25|1@0+ (1,0) [0|1] "" EOCM,EOCM_HCP2,EOCM_HC_Superset,HDLM
 SG_ FCODPB12P_FVTS2PhysTypAuth : 27|2@0+ (1,0) [0|2] "" EOCM,EOCM_HCP2,EOCM_HC_Superset,HDLM
 SG_ FCODPB12P_FVTS2MeasVldAuth : 28|1@0+ (1,0) [0|1] "" EOCM,EOCM_HCP2,EOCM_HC_Superset,HDLM
 SG_ FCODPB12P_FVTS2FiltTypAuth : 30|2@0+ (1,0) [0|3] "" EOCM,EOCM_HCP2,EOCM_HC_Superset,HDLM
 SG_ FCODPB12P_FVTS3AgeAuth : 39|8@0+ (1,0) [0|255] "Frames" EOCM,EOCM_HCP2,EOCM_HC_Superset,HDLM
 SG_ FCODPB12P_FVTS4AgeAuth : 40|8@0+ (1,0) [0|255] "Frames" EOCM,EOCM_HCP2,EOCM_HC_Superset,HDLM
 SG_ FCODPB12P_FVTS3ZnDtdAuth : 41|1@0+ (1,0) [0|1] "" EOCM,EOCM_HCP2,EOCM_HC_Superset,HDLM
 SG_ FCODPB12P_FVTS3PsdbyHstVehAuth : 42|1@0+ (1,0) [0|1] "" EOCM,EOCM_HCP2,EOCM_HC_Superset,HDLM
 SG_ FCODPB12P_FVTS3PhysTypAuth : 44|2@0+ (1,0) [0|2] "" EOCM,EOCM_HCP2,EOCM_HC_Superset,HDLM
 SG_ FCODPB12P_FVTS3MeasVldAuth : 45|1@0+ (1,0) [0|1] "" EOCM,EOCM_HCP2,EOCM_HC_Superset,HDLM
 SG_ FCODPB12P_FVTS3FiltTypAuth : 47|2@0+ (1,0) [0|3] "" EOCM,EOCM_HCP2,EOCM_HC_Superset,HDLM
 SG_ FCODPB12P_FVTS4FiltTypAuth : 48|2@0+ (1,0) [0|3] "" EOCM,EOCM_HCP2,EOCM_HC_Superset,HDLM
 SG_ FCODPB12P_FVTS5AgeAuth : 57|8@0+ (1,0) [0|255] "Frames" EOCM,EOCM_HCP2,EOCM_HC_Superset,HDLM
 SG_ FCODPB12P_FVTS4ZnDtdAuth : 58|1@0+ (1,0) [0|1] "" EOCM,EOCM_HCP2,EOCM_HC_Superset,HDLM
 SG_ FCODPB12P_FVTS4PsdbyHstVehAuth : 59|1@0+ (1,0) [0|1] "" EOCM,EOCM_HCP2,EOCM_HC_Superset,HDLM
 SG_ FCODPB12P_FVTS4PhysTypAuth : 61|2@0+ (1,0) [0|2] "" EOCM,EOCM_HCP2,EOCM_HC_Superset,HDLM
 SG_ FCODPB12P_FVTS4MeasVldAuth : 62|1@0+ (1,0) [0|1] "" EOCM,EOCM_HCP2,EOCM_HC_Superset,HDLM
 SG_ FCODPB12P_FVTS5FiltTypAuth : 65|2@0+ (1,0) [0|3] "" EOCM,EOCM_HCP2,EOCM_HC_Superset,HDLM
 SG_ FCODPB12P_FVTS6AgeAuth : 74|8@0+ (1,0) [0|255] "Frames" EOCM,EOCM_HCP2,EOCM_HC_Superset,HDLM
 SG_ FCODPB12P_FVTS5ZnDtdAuth : 75|1@0+ (1,0) [0|1] "" EOCM,EOCM_HCP2,EOCM_HC_Superset,HDLM
 SG_ FCODPB12P_FVTS5PsdbyHstVehAuth : 76|1@0+ (1,0) [0|1] "" EOCM,EOCM_HCP2,EOCM_HC_Superset,HDLM
 SG_ FCODPB12P_FVTS5PhysTypAuth : 78|2@0+ (1,0) [0|2] "" EOCM,EOCM_HCP2,EOCM_HC_Superset,HDLM
 SG_ FCODPB12P_FVTS5MeasVldAuth : 79|1@0+ (1,0) [0|1] "" EOCM,EOCM_HCP2,EOCM_HC_Superset,HDLM
 SG_ FCODPB12P_FVTS6MeasVldAuth : 80|1@0+ (1,0) [0|1] "" EOCM,EOCM_HCP2,EOCM_HC_Superset,HDLM
 SG_ FCODPB12P_FVTS6FiltTypAuth : 82|2@0+ (1,0) [0|3] "" EOCM,EOCM_HCP2,EOCM_HC_Superset,HDLM
 SG_ FCODPB12P_RdBnkCrv1CrvAuth : 89|16@0- (9.77e-07,0) [-0.0320143|0.0320134] "1/m" EOCM,EOCM_HCP2,EOCM_HC_Superset,HDLM
 SG_ FCODPB12P_RdBnkCrv1CnfdStsAuth : 91|2@0+ (1,0) [0|3] "" EOCM,EOCM_HCP2,EOCM_HC_Superset,HDLM
 SG_ FCODPB12P_FVTS6ZnDtdAuth : 92|1@0+ (1,0) [0|1] "" EOCM,EOCM_HCP2,EOCM_HC_Superset,HDLM
 SG_ FCODPB12P_FVTS6PsdbyHstVehAuth : 93|1@0+ (1,0) [0|1] "" EOCM,EOCM_HCP2,EOCM_HC_Superset,HDLM
 SG_ FCODPB12P_FVTS6PhysTypAuth : 95|2@0+ (1,0) [0|2] "" EOCM,EOCM_HCP2,EOCM_HC_Superset,HDLM
 SG_ FCODPB12P_RdBnkCrv1CrvDrvtAuth : 105|16@0- (3.73e-09,0) [-0.000122225|0.000122221] "1/m2" EOCM,EOCM_HCP2,EOCM_HC_Superset,HDLM
 SG_ FCODPB12P_RdBnkCrv1HdgAuth : 121|10@0- (0.000977,0) [-0.500224|0.499247] "rad" EOCM,EOCM_HCP2,EOCM_HC_Superset,HDLM
 SG_ FCODPB12P_RdBnkCrv1LatOfstAuth : 143|8@0- (0.125,0) [-16|15.875] "m" EOCM,EOCM_HCP2,EOCM_HC_Superset,HDLM
 SG_ FCODPB12P_RdBnkCrv1LngOfstAuth : 151|10@0+ (0.125,0) [0|127.875] "m" EOCM,EOCM_HCP2,EOCM_HC_Superset,HDLM
 SG_ FCODPB12P_RdBnkCrv1PsEndAuth : 157|8@0- (0.125,0) [-16|15.875] "m" EOCM,EOCM_HCP2,EOCM_HC_Superset,HDLM
 SG_ FCODPB12P_RdBnkCrv1PsStrtAuth : 165|8@0- (0.125,0) [-16|15.875] "m" EOCM,EOCM_HCP2,EOCM_HC_Superset,HDLM
 SG_ FCODPB12P_RdBnkCrv2CrvAuth : 171|16@0- (9.77e-07,0) [-0.0320143|0.0320134] "1/m" EOCM,EOCM_HCP2,EOCM_HC_Superset,HDLM
 SG_ FCODPB12P_RdBnkCrv2CnfdStsAuth : 173|2@0+ (1,0) [0|3] "" EOCM,EOCM_HCP2,EOCM_HC_Superset,HDLM
 SG_ FCODPB12P_RdBnkCrv2CrvDrvtAuth : 187|16@0- (3.73e-09,0) [-0.000122225|0.000122221] "1/m2" EOCM,EOCM_HCP2,EOCM_HC_Superset,HDLM
 SG_ FCODPB12P_RdBnkCrv2HdgAuth : 203|10@0- (0.000977,0) [-0.500224|0.499247] "rad" EOCM,EOCM_HCP2,EOCM_HC_Superset,HDLM
 SG_ FCODPB12P_RdBnkCrv2LatOfstAuth : 209|8@0- (0.125,0) [-16|15.875] "m" EOCM,EOCM_HCP2,EOCM_HC_Superset,HDLM
 SG_ FCODPB12P_RdBnkCrv2LngOfstAuth : 217|10@0+ (0.125,0) [0|127.875] "m" EOCM,EOCM_HCP2,EOCM_HC_Superset,HDLM
 SG_ FCODPB12P_RdBnkCrv2PsEndAuth : 239|8@0- (0.125,0) [-16|15.875] "m" EOCM,EOCM_HCP2,EOCM_HC_Superset,HDLM
 SG_ FCODPB12P_RdBnkCrv2PsStrtAuth : 247|8@0- (0.125,0) [-16|15.875] "m" EOCM,EOCM_HCP2,EOCM_HC_Superset,HDLM
 SG_ FCODPB12P_RdBnkCrv3CrvAuth : 253|16@0- (9.77e-07,0) [-0.0320143|0.0320134] "1/m" EOCM,EOCM_HCP2,EOCM_HC_Superset,HDLM
 SG_ FCODPB12P_RdBnkCrv3CnfdStsAuth : 255|2@0+ (1,0) [0|3] "" EOCM,EOCM_HCP2,EOCM_HC_Superset,HDLM
 SG_ FCODPB12P_RdBnkCrv3CrvDrvtAuth : 269|16@0- (3.73e-09,0) [-0.000122225|0.000122221] "1/m2" EOCM,EOCM_HCP2,EOCM_HC_Superset,HDLM
 SG_ FCODPB12P_RdBnkCrv3HdgAuth : 285|10@0- (0.000977,0) [-0.500224|0.499247] "rad" EOCM,EOCM_HCP2,EOCM_HC_Superset,HDLM
 SG_ FCODPB12P_RdBnkCrv3LatOfstAuth : 291|8@0- (0.125,0) [-16|15.875] "m" EOCM,EOCM_HCP2,EOCM_HC_Superset,HDLM
 SG_ FCODPB12P_RdBnkCrv3LngOfstAuth : 299|10@0+ (0.125,0) [0|127.875] "m" EOCM,EOCM_HCP2,EOCM_HC_Superset,HDLM
 SG_ FCODPB12P_RdBnkCrv3PsEndAuth : 305|8@0- (0.125,0) [-16|15.875] "m" EOCM,EOCM_HCP2,EOCM_HC_Superset,HDLM
 SG_ FCODPB12P_RdBnkCrv3PsStrtAuth : 313|8@0- (0.125,0) [-16|15.875] "m" EOCM,EOCM_HCP2,EOCM_HC_Superset,HDLM
 SG_ FCODPB12P_RdVertPP10ElvtnAuth : 321|10@0- (0.125,0) [-64|63.875] "m" EOCM,EOCM_HCP2,EOCM_HC_Superset,HDLM
 SG_ FCODPB12P_RdVertPP11ElvtnAuth : 343|10@0- (0.125,0) [-64|63.875] "m" EOCM,EOCM_HCP2,EOCM_HC_Superset,HDLM
 SG_ FCODPB12P_RdVertPP12ElvtnAuth : 349|10@0- (0.125,0) [-64|63.875] "m" EOCM,EOCM_HCP2,EOCM_HC_Superset,HDLM
 SG_ FCODPB12P_RdVertPP13ElvtnAuth : 355|10@0- (0.125,0) [-64|63.875] "m" EOCM,EOCM_HCP2,EOCM_HC_Superset,HDLM
 SG_ FCODPB12P_RdVertPP14ElvtnAuth : 361|10@0- (0.125,0) [-64|63.875] "m" EOCM,EOCM_HCP2,EOCM_HC_Superset,HDLM
 SG_ FCODPB12P_RdVertPP15ElvtnAuth : 383|10@0- (0.125,0) [-64|63.875] "m" EOCM,EOCM_HCP2,EOCM_HC_Superset,HDLM
 SG_ FCODPB12P_RdVertPP1ElvtnAuth : 389|10@0- (0.125,0) [-64|63.875] "m" EOCM,EOCM_HCP2,EOCM_HC_Superset,HDLM
 SG_ FCODPB12P_RdVertPP2ElvtnAuth : 395|10@0- (0.125,0) [-64|63.875] "m" EOCM,EOCM_HCP2,EOCM_HC_Superset,HDLM
 SG_ FCODPB12P_RdVertPP3ElvtnAuth : 401|10@0- (0.125,0) [-64|63.875] "m" EOCM,EOCM_HCP2,EOCM_HC_Superset,HDLM
 SG_ FCODPB12P_RdVertPP4ElvtnAuth : 423|10@0- (0.125,0) [-64|63.875] "m" EOCM,EOCM_HCP2,EOCM_HC_Superset,HDLM
 SG_ FCODPB12P_RdVertPP5ElvtnAuth : 429|10@0- (0.125,0) [-64|63.875] "m" EOCM,EOCM_HCP2,EOCM_HC_Superset,HDLM
 SG_ FCODPB12P_RdVertPP6ElvtnAuth : 435|10@0- (0.125,0) [-64|63.875] "m" EOCM,EOCM_HCP2,EOCM_HC_Superset,HDLM
 SG_ FCODPB12P_RdVertPP7ElvtnAuth : 441|10@0- (0.125,0) [-64|63.875] "m" EOCM,EOCM_HCP2,EOCM_HC_Superset,HDLM
 SG_ FCODPB12P_RdVertPP8ElvtnAuth : 463|10@0- (0.125,0) [-64|63.875] "m" EOCM,EOCM_HCP2,EOCM_HC_Superset,HDLM
 SG_ FCODPB12P_RdVertPP9ElvtnAuth : 469|10@0- (0.125,0) [-64|63.875] "m" EOCM,EOCM_HCP2,EOCM_HC_Superset,HDLM
 SG_ FCODPB12P_Filler : 475|32@0+ (1,0) [0|4.29497e+009] "" EOCM,EOCM_HCP2,EOCM_HC_Superset,HDLM
 SG_ FCODPB12P_FillerExtnd : 507|4@0+ (1,0) [0|15] "" EOCM,EOCM_HCP2,EOCM_HC_Superset,HDLM

BO_ 239 FCODP_BrstGrp_Prtctd_Consecuti02: 64 ACP2_MCU
 SG_ FCODPB13P_FVTS10AgeAuth : 5|8@0+ (1,0) [0|255] "Frames" EOCM,EOCM_HCP2,EOCM_HC_Superset,HDLM
 SG_ FCODPB13P_BrstID : 7|2@0+ (1,0) [0|3] "" EOCM,EOCM_HCP2,EOCM_HC_Superset,HDLM
 SG_ FCODPB13P_FVTS10PsdbyHstVehAuth : 8|1@0+ (1,0) [0|1] "" EOCM,EOCM_HCP2,EOCM_HC_Superset,HDLM
 SG_ FCODPB13P_FVTS10PhysTypAuth : 10|2@0+ (1,0) [0|2] "" EOCM,EOCM_HCP2,EOCM_HC_Superset,HDLM
 SG_ FCODPB13P_FVTS10MeasVldAuth : 11|1@0+ (1,0) [0|1] "" EOCM,EOCM_HCP2,EOCM_HC_Superset,HDLM
 SG_ FCODPB13P_FVTS10FiltTypAuth : 13|2@0+ (1,0) [0|3] "" EOCM,EOCM_HCP2,EOCM_HC_Superset,HDLM
 SG_ FCODPB13P_FVTS7AgeAuth : 22|8@0+ (1,0) [0|255] "Frames" EOCM,EOCM_HCP2,EOCM_HC_Superset,HDLM
 SG_ FCODPB13P_FVTS10ZnDtdAuth : 23|1@0+ (1,0) [0|1] "" EOCM,EOCM_HCP2,EOCM_HC_Superset,HDLM
 SG_ FCODPB13P_FVTS7ZnDtdAuth : 24|1@0+ (1,0) [0|1] "" EOCM,EOCM_HCP2,EOCM_HC_Superset,HDLM
 SG_ FCODPB13P_FVTS7PsdbyHstVehAuth : 25|1@0+ (1,0) [0|1] "" EOCM,EOCM_HCP2,EOCM_HC_Superset,HDLM
 SG_ FCODPB13P_FVTS7PhysTypAuth : 27|2@0+ (1,0) [0|2] "" EOCM,EOCM_HCP2,EOCM_HC_Superset,HDLM
 SG_ FCODPB13P_FVTS7MeasVldAuth : 28|1@0+ (1,0) [0|1] "" EOCM,EOCM_HCP2,EOCM_HC_Superset,HDLM
 SG_ FCODPB13P_FVTS7FiltTypAuth : 30|2@0+ (1,0) [0|3] "" EOCM,EOCM_HCP2,EOCM_HC_Superset,HDLM
 SG_ FCODPB13P_FVTS8AgeAuth : 39|8@0+ (1,0) [0|255] "Frames" EOCM,EOCM_HCP2,EOCM_HC_Superset,HDLM
 SG_ FCODPB13P_FVTS9AgeAuth : 40|8@0+ (1,0) [0|255] "Frames" EOCM,EOCM_HCP2,EOCM_HC_Superset,HDLM
 SG_ FCODPB13P_FVTS8ZnDtdAuth : 41|1@0+ (1,0) [0|1] "" EOCM,EOCM_HCP2,EOCM_HC_Superset,HDLM
 SG_ FCODPB13P_FVTS8PsdbyHstVehAuth : 42|1@0+ (1,0) [0|1] "" EOCM,EOCM_HCP2,EOCM_HC_Superset,HDLM
 SG_ FCODPB13P_FVTS8PhysTypAuth : 44|2@0+ (1,0) [0|2] "" EOCM,EOCM_HCP2,EOCM_HC_Superset,HDLM
 SG_ FCODPB13P_FVTS8MeasVldAuth : 45|1@0+ (1,0) [0|1] "" EOCM,EOCM_HCP2,EOCM_HC_Superset,HDLM
 SG_ FCODPB13P_FVTS8FiltTypAuth : 47|2@0+ (1,0) [0|3] "" EOCM,EOCM_HCP2,EOCM_HC_Superset,HDLM
 SG_ FCODPB13P_FVTS9FiltTypAuth : 48|2@0+ (1,0) [0|3] "" EOCM,EOCM_HCP2,EOCM_HC_Superset,HDLM
 SG_ FCODPB13P_FVTSTk10CnfdStsAuth : 57|2@0+ (1,0) [0|3] "" EOCM,EOCM_HCP2,EOCM_HC_Superset,HDLM
 SG_ FCODPB13P_FVTS9ZnDtdAuth : 58|1@0+ (1,0) [0|1] "" EOCM,EOCM_HCP2,EOCM_HC_Superset,HDLM
 SG_ FCODPB13P_FVTS9PsdbyHstVehAuth : 59|1@0+ (1,0) [0|1] "" EOCM,EOCM_HCP2,EOCM_HC_Superset,HDLM
 SG_ FCODPB13P_FVTS9PhysTypAuth : 61|2@0+ (1,0) [0|2] "" EOCM,EOCM_HCP2,EOCM_HC_Superset,HDLM
 SG_ FCODPB13P_FVTS9MeasVldAuth : 62|1@0+ (1,0) [0|1] "" EOCM,EOCM_HCP2,EOCM_HC_Superset,HDLM
 SG_ FCODPB13P_FVTSTk10LatPsAuth : 65|9@0- (0.125,0) [-32|31.875] "m" EOCM,EOCM_HCP2,EOCM_HC_Superset,HDLM
 SG_ FCODPB13P_FVTSTk10IDAuth : 71|6@0+ (1,0) [0|63] "" EOCM,EOCM_HCP2,EOCM_HC_Superset,HDLM
 SG_ FCODPB13P_FVTSTk10LngPsAuth : 72|11@0- (0.125,0) [-128|127.875] "m" EOCM,EOCM_HCP2,EOCM_HC_Superset,HDLM
 SG_ FCODPB13P_FVTSTk10SupTypAuth : 91|6@0+ (1,0) [0|39] "" EOCM,EOCM_HCP2,EOCM_HC_Superset,HDLM
 SG_ FCODPB13P_FVTSTk10MeasStsAuth : 93|2@0+ (1,0) [0|3] "" EOCM,EOCM_HCP2,EOCM_HC_Superset,HDLM
 SG_ FCODPB13P_FVTSTk10TypAuth : 101|7@0+ (1,0) [0|75] "" EOCM,EOCM_HCP2,EOCM_HC_Superset,HDLM
 SG_ FCODPB13P_FVTSTk10VertPsAuth : 108|8@0+ (0.125,0) [0|31.875] "m" EOCM,EOCM_HCP2,EOCM_HC_Superset,HDLM
 SG_ FCODPB13P_FVTSTk10TypCnfdAuth : 110|2@0+ (1,0) [0|3] "" EOCM,EOCM_HCP2,EOCM_HC_Superset,HDLM
 SG_ FCODPB13P_FVTSTk1IDAuth : 114|6@0+ (1,0) [0|63] "" EOCM,EOCM_HCP2,EOCM_HC_Superset,HDLM
 SG_ FCODPB13P_FVTSTk1CnfdStsAuth : 116|2@0+ (1,0) [0|3] "" EOCM,EOCM_HCP2,EOCM_HC_Superset,HDLM
 SG_ FCODPB13P_FVTSTk1LatPsAuth : 124|9@0- (0.125,0) [-32|31.875] "m" EOCM,EOCM_HCP2,EOCM_HC_Superset,HDLM
 SG_ FCODPB13P_FVTSTk1LngPsAuth : 131|11@0- (0.125,0) [-128|127.875] "m" EOCM,EOCM_HCP2,EOCM_HC_Superset,HDLM
 SG_ FCODPB13P_FVTSTk1MeasStsAuth : 136|2@0+ (1,0) [0|3] "" EOCM,EOCM_HCP2,EOCM_HC_Superset,HDLM
 SG_ FCODPB13P_FVTSTk1TypAuth : 144|7@0+ (1,0) [0|75] "" EOCM,EOCM_HCP2,EOCM_HC_Superset,HDLM
 SG_ FCODPB13P_FVTSTk1SupTypAuth : 150|6@0+ (1,0) [0|39] "" EOCM,EOCM_HCP2,EOCM_HC_Superset,HDLM
 SG_ FCODPB13P_FVTSTk1TypCnfdAuth : 153|2@0+ (1,0) [0|3] "" EOCM,EOCM_HCP2,EOCM_HC_Superset,HDLM
 SG_ FCODPB13P_FVTSTk1VertPsAuth : 167|8@0+ (0.125,0) [0|31.875] "m" EOCM,EOCM_HCP2,EOCM_HC_Superset,HDLM
 SG_ FCODPB13P_FVTSTk2IDAuth : 173|6@0+ (1,0) [0|63] "" EOCM,EOCM_HCP2,EOCM_HC_Superset,HDLM
 SG_ FCODPB13P_FVTSTk2CnfdStsAuth : 175|2@0+ (1,0) [0|3] "" EOCM,EOCM_HCP2,EOCM_HC_Superset,HDLM
 SG_ FCODPB13P_FVTSTk2LatPsAuth : 183|9@0- (0.125,0) [-32|31.875] "m" EOCM,EOCM_HCP2,EOCM_HC_Superset,HDLM
 SG_ FCODPB13P_FVTSTk2LngPsAuth : 190|11@0- (0.125,0) [-128|127.875] "m" EOCM,EOCM_HCP2,EOCM_HC_Superset,HDLM
 SG_ FCODPB13P_FVTSTk2SupTypAuth : 193|6@0+ (1,0) [0|39] "" EOCM,EOCM_HCP2,EOCM_HC_Superset,HDLM
 SG_ FCODPB13P_FVTSTk2MeasStsAuth : 195|2@0+ (1,0) [0|3] "" EOCM,EOCM_HCP2,EOCM_HC_Superset,HDLM
 SG_ FCODPB13P_FVTSTk2TypAuth : 203|7@0+ (1,0) [0|75] "" EOCM,EOCM_HCP2,EOCM_HC_Superset,HDLM
 SG_ FCODPB13P_FVTSTk2VertPsAuth : 210|8@0+ (0.125,0) [0|31.875] "m" EOCM,EOCM_HCP2,EOCM_HC_Superset,HDLM
 SG_ FCODPB13P_FVTSTk2TypCnfdAuth : 212|2@0+ (1,0) [0|3] "" EOCM,EOCM_HCP2,EOCM_HC_Superset,HDLM
 SG_ FCODPB13P_FVTSTk3IDAuth : 216|6@0+ (1,0) [0|63] "" EOCM,EOCM_HCP2,EOCM_HC_Superset,HDLM
 SG_ FCODPB13P_FVTSTk3CnfdStsAuth : 218|2@0+ (1,0) [0|3] "" EOCM,EOCM_HCP2,EOCM_HC_Superset,HDLM
 SG_ FCODPB13P_FVTSTk3LatPsAuth : 226|9@0- (0.125,0) [-32|31.875] "m" EOCM,EOCM_HCP2,EOCM_HC_Superset,HDLM
 SG_ FCODPB13P_FVTSTk3LngPsAuth : 233|11@0- (0.125,0) [-128|127.875] "m" EOCM,EOCM_HCP2,EOCM_HC_Superset,HDLM
 SG_ FCODPB13P_FVTSTk3SupTypAuth : 252|6@0+ (1,0) [0|39] "" EOCM,EOCM_HCP2,EOCM_HC_Superset,HDLM
 SG_ FCODPB13P_FVTSTk3MeasStsAuth : 254|2@0+ (1,0) [0|3] "" EOCM,EOCM_HCP2,EOCM_HC_Superset,HDLM
 SG_ FCODPB13P_FVTSTk3TypAuth : 262|7@0+ (1,0) [0|75] "" EOCM,EOCM_HCP2,EOCM_HC_Superset,HDLM
 SG_ FCODPB13P_FVTSTk3VertPsAuth : 269|8@0+ (0.125,0) [0|31.875] "m" EOCM,EOCM_HCP2,EOCM_HC_Superset,HDLM
 SG_ FCODPB13P_FVTSTk3TypCnfdAuth : 271|2@0+ (1,0) [0|3] "" EOCM,EOCM_HCP2,EOCM_HC_Superset,HDLM
 SG_ FCODPB13P_FVTSTk4IDAuth : 275|6@0+ (1,0) [0|63] "" EOCM,EOCM_HCP2,EOCM_HC_Superset,HDLM
 SG_ FCODPB13P_FVTSTk4CnfdStsAuth : 277|2@0+ (1,0) [0|3] "" EOCM,EOCM_HCP2,EOCM_HC_Superset,HDLM
 SG_ FCODPB13P_FVTSTk4LatPsAuth : 285|9@0- (0.125,0) [-32|31.875] "m" EOCM,EOCM_HCP2,EOCM_HC_Superset,HDLM
 SG_ FCODPB13P_FVTSTk4LngPsAuth : 292|11@0- (0.125,0) [-128|127.875] "m" EOCM,EOCM_HCP2,EOCM_HC_Superset,HDLM
 SG_ FCODPB13P_FVTSTk4MeasStsAuth : 297|2@0+ (1,0) [0|3] "" EOCM,EOCM_HCP2,EOCM_HC_Superset,HDLM
 SG_ FCODPB13P_FVTSTk4TypAuth : 305|7@0+ (1,0) [0|75] "" EOCM,EOCM_HCP2,EOCM_HC_Superset,HDLM
 SG_ FCODPB13P_FVTSTk4SupTypAuth : 311|6@0+ (1,0) [0|39] "" EOCM,EOCM_HCP2,EOCM_HC_Superset,HDLM
 SG_ FCODPB13P_FVTSTk4VertPsAuth : 312|8@0+ (0.125,0) [0|31.875] "m" EOCM,EOCM_HCP2,EOCM_HC_Superset,HDLM
 SG_ FCODPB13P_FVTSTk4TypCnfdAuth : 314|2@0+ (1,0) [0|3] "" EOCM,EOCM_HCP2,EOCM_HC_Superset,HDLM
 SG_ FCODPB13P_FVTSTk5CnfdStsAuth : 320|2@0+ (1,0) [0|3] "" EOCM,EOCM_HCP2,EOCM_HC_Superset,HDLM
 SG_ FCODPB13P_FVTSTk5LatPsAuth : 328|9@0- (0.125,0) [-32|31.875] "m" EOCM,EOCM_HCP2,EOCM_HC_Superset,HDLM
 SG_ FCODPB13P_FVTSTk5IDAuth : 334|6@0+ (1,0) [0|63] "" EOCM,EOCM_HCP2,EOCM_HC_Superset,HDLM
 SG_ FCODPB13P_FVTSTk5LngPsAuth : 351|11@0- (0.125,0) [-128|127.875] "m" EOCM,EOCM_HCP2,EOCM_HC_Superset,HDLM
 SG_ FCODPB13P_FVTSTk5SupTypAuth : 354|6@0+ (1,0) [0|39] "" EOCM,EOCM_HCP2,EOCM_HC_Superset,HDLM
 SG_ FCODPB13P_FVTSTk5MeasStsAuth : 356|2@0+ (1,0) [0|3] "" EOCM,EOCM_HCP2,EOCM_HC_Superset,HDLM
 SG_ FCODPB13P_FVTSTk5TypAuth : 364|7@0+ (1,0) [0|75] "" EOCM,EOCM_HCP2,EOCM_HC_Superset,HDLM
 SG_ FCODPB13P_FVTSTk5VertPsAuth : 371|8@0+ (0.125,0) [0|31.875] "m" EOCM,EOCM_HCP2,EOCM_HC_Superset,HDLM
 SG_ FCODPB13P_FVTSTk5TypCnfdAuth : 373|2@0+ (1,0) [0|3] "" EOCM,EOCM_HCP2,EOCM_HC_Superset,HDLM
 SG_ FCODPB13P_FVTSTk6IDAuth : 377|6@0+ (1,0) [0|63] "" EOCM,EOCM_HCP2,EOCM_HC_Superset,HDLM
 SG_ FCODPB13P_FVTSTk6CnfdStsAuth : 379|2@0+ (1,0) [0|3] "" EOCM,EOCM_HCP2,EOCM_HC_Superset,HDLM
 SG_ FCODPB13P_FVTSTk6LatPsAuth : 387|9@0- (0.125,0) [-32|31.875] "m" EOCM,EOCM_HCP2,EOCM_HC_Superset,HDLM
 SG_ FCODPB13P_FVTSTk6LngPsAuth : 394|11@0- (0.125,0) [-128|127.875] "m" EOCM,EOCM_HCP2,EOCM_HC_Superset,HDLM
 SG_ FCODPB13P_FVTSTk6SupTypAuth : 413|6@0+ (1,0) [0|39] "" EOCM,EOCM_HCP2,EOCM_HC_Superset,HDLM
 SG_ FCODPB13P_FVTSTk6MeasStsAuth : 415|2@0+ (1,0) [0|3] "" EOCM,EOCM_HCP2,EOCM_HC_Superset,HDLM
 SG_ FCODPB13P_FVTSTk6TypCnfdAuth : 416|2@0+ (1,0) [0|3] "" EOCM,EOCM_HCP2,EOCM_HC_Superset,HDLM
 SG_ FCODPB13P_FVTSTk6TypAuth : 423|7@0+ (1,0) [0|75] "" EOCM,EOCM_HCP2,EOCM_HC_Superset,HDLM
 SG_ FCODPB13P_FVTSTk6VertPsAuth : 430|8@0+ (0.125,0) [0|31.875] "m" EOCM,EOCM_HCP2,EOCM_HC_Superset,HDLM
 SG_ FCODPB13P_FVTSTk7IDAuth : 436|6@0+ (1,0) [0|63] "" EOCM,EOCM_HCP2,EOCM_HC_Superset,HDLM
 SG_ FCODPB13P_FVTSTk7CnfdStsAuth : 438|2@0+ (1,0) [0|3] "" EOCM,EOCM_HCP2,EOCM_HC_Superset,HDLM
 SG_ FCODPB13P_FVTSTk7LatPsAuth : 446|9@0- (0.125,0) [-32|31.875] "m" EOCM,EOCM_HCP2,EOCM_HC_Superset,HDLM
 SG_ FCODPB13P_FVTSTk7LngPsAuth : 453|11@0- (0.125,0) [-128|127.875] "m" EOCM,EOCM_HCP2,EOCM_HC_Superset,HDLM
 SG_ FCODPB13P_FVTSTk7SupTypAuth : 456|6@0+ (1,0) [0|39] "" EOCM,EOCM_HCP2,EOCM_HC_Superset,HDLM
 SG_ FCODPB13P_FVTSTk7MeasStsAuth : 458|2@0+ (1,0) [0|3] "" EOCM,EOCM_HCP2,EOCM_HC_Superset,HDLM
 SG_ FCODPB13P_FVTSTk7TypAuth : 466|7@0+ (1,0) [0|75] "" EOCM,EOCM_HCP2,EOCM_HC_Superset,HDLM
 SG_ FCODPB13P_FVTSTk7VertPsAuth : 473|8@0+ (0.125,0) [0|31.875] "m" EOCM,EOCM_HCP2,EOCM_HC_Superset,HDLM
 SG_ FCODPB13P_FVTSTk7TypCnfdAuth : 475|2@0+ (1,0) [0|3] "" EOCM,EOCM_HCP2,EOCM_HC_Superset,HDLM
 SG_ FCODPB13P_Filler : 481|26@0+ (1,0) [0|6.71089e+007] "" EOCM,EOCM_HCP2,EOCM_HC_Superset,HDLM

BO_ 216 FCODP_BrstGrp_Prtctd_Consecuti03: 48 ACP2_MCU
 SG_ FCODPB14P_CnstrObj10IDAuth : 3|5@0+ (1,0) [0|31] "" EOCM,EOCM_HCP2,EOCM_HC_Superset,HDLM
 SG_ FCODPB14P_CnstrObj10CnfdStsAuth : 5|2@0+ (1,0) [0|3] "" EOCM,EOCM_HCP2,EOCM_HC_Superset,HDLM
 SG_ FCODPB14P_BrstID : 7|2@0+ (1,0) [0|3] "" EOCM,EOCM_HCP2,EOCM_HC_Superset,HDLM
 SG_ FCODPB14P_CnstrObj10LatDistAuth : 14|9@0- (0.125,0) [-32|31.875] "m" EOCM,EOCM_HCP2,EOCM_HC_Superset,HDLM
 SG_ FCODPB14P_CnstrObj11IDAuth : 17|5@0+ (1,0) [0|31] "" EOCM,EOCM_HCP2,EOCM_HC_Superset,HDLM
 SG_ FCODPB14P_CnstrObj11CnfdStsAuth : 19|2@0+ (1,0) [0|3] "" EOCM,EOCM_HCP2,EOCM_HC_Superset,HDLM
 SG_ FCODPB14P_CnstrObj10TypAuth : 21|2@0+ (1,0) [0|3] "" EOCM,EOCM_HCP2,EOCM_HC_Superset,HDLM
 SG_ FCODPB14P_CnstrObj11LatDistAuth : 28|9@0- (0.125,0) [-32|31.875] "m" EOCM,EOCM_HCP2,EOCM_HC_Superset,HDLM
 SG_ FCODPB14P_CnstrObj12CnfdStsAuth : 33|2@0+ (1,0) [0|3] "" EOCM,EOCM_HCP2,EOCM_HC_Superset,HDLM
 SG_ FCODPB14P_CnstrObj11TypAuth : 35|2@0+ (1,0) [0|3] "" EOCM,EOCM_HCP2,EOCM_HC_Superset,HDLM
 SG_ FCODPB14P_CnstrObj12LatDistAuth : 42|9@0- (0.125,0) [-32|31.875] "m" EOCM,EOCM_HCP2,EOCM_HC_Superset,HDLM
 SG_ FCODPB14P_CnstrObj12IDAuth : 47|5@0+ (1,0) [0|31] "" EOCM,EOCM_HCP2,EOCM_HC_Superset,HDLM
 SG_ FCODPB14P_CnstrObj12TypAuth : 49|2@0+ (1,0) [0|3] "" EOCM,EOCM_HCP2,EOCM_HC_Superset,HDLM
 SG_ FCODPB14P_CnstrObj13LatDistAuth : 56|9@0- (0.125,0) [-32|31.875] "m" EOCM,EOCM_HCP2,EOCM_HC_Superset,HDLM
 SG_ FCODPB14P_CnstrObj13IDAuth : 61|5@0+ (1,0) [0|31] "" EOCM,EOCM_HCP2,EOCM_HC_Superset,HDLM
 SG_ FCODPB14P_CnstrObj13CnfdStsAuth : 63|2@0+ (1,0) [0|3] "" EOCM,EOCM_HCP2,EOCM_HC_Superset,HDLM
 SG_ FCODPB14P_CnstrObj14IDAuth : 75|5@0+ (1,0) [0|31] "" EOCM,EOCM_HCP2,EOCM_HC_Superset,HDLM
 SG_ FCODPB14P_CnstrObj14CnfdStsAuth : 77|2@0+ (1,0) [0|3] "" EOCM,EOCM_HCP2,EOCM_HC_Superset,HDLM
 SG_ FCODPB14P_CnstrObj13TypAuth : 79|2@0+ (1,0) [0|3] "" EOCM,EOCM_HCP2,EOCM_HC_Superset,HDLM
 SG_ FCODPB14P_CnstrObj14LatDistAuth : 86|9@0- (0.125,0) [-32|31.875] "m" EOCM,EOCM_HCP2,EOCM_HC_Superset,HDLM
 SG_ FCODPB14P_CnstrObj15IDAuth : 89|5@0+ (1,0) [0|31] "" EOCM,EOCM_HCP2,EOCM_HC_Superset,HDLM
 SG_ FCODPB14P_CnstrObj15CnfdStsAuth : 91|2@0+ (1,0) [0|3] "" EOCM,EOCM_HCP2,EOCM_HC_Superset,HDLM
 SG_ FCODPB14P_CnstrObj14TypAuth : 93|2@0+ (1,0) [0|3] "" EOCM,EOCM_HCP2,EOCM_HC_Superset,HDLM
 SG_ FCODPB14P_CnstrObj15LatDistAuth : 100|9@0- (0.125,0) [-32|31.875] "m" EOCM,EOCM_HCP2,EOCM_HC_Superset,HDLM
 SG_ FCODPB14P_CnstrObj1CnfdStsAuth : 105|2@0+ (1,0) [0|3] "" EOCM,EOCM_HCP2,EOCM_HC_Superset,HDLM
 SG_ FCODPB14P_CnstrObj15TypAuth : 107|2@0+ (1,0) [0|3] "" EOCM,EOCM_HCP2,EOCM_HC_Superset,HDLM
 SG_ FCODPB14P_CnstrObj1LatDistAuth : 114|9@0- (0.125,0) [-32|31.875] "m" EOCM,EOCM_HCP2,EOCM_HC_Superset,HDLM
 SG_ FCODPB14P_CnstrObj1IDAuth : 119|5@0+ (1,0) [0|31] "" EOCM,EOCM_HCP2,EOCM_HC_Superset,HDLM
 SG_ FCODPB14P_CnstrObj1TypAuth : 121|2@0+ (1,0) [0|3] "" EOCM,EOCM_HCP2,EOCM_HC_Superset,HDLM
 SG_ FCODPB14P_CnstrObj2LatDistAuth : 128|9@0- (0.125,0) [-32|31.875] "m" EOCM,EOCM_HCP2,EOCM_HC_Superset,HDLM
 SG_ FCODPB14P_CnstrObj2IDAuth : 133|5@0+ (1,0) [0|31] "" EOCM,EOCM_HCP2,EOCM_HC_Superset,HDLM
 SG_ FCODPB14P_CnstrObj2CnfdStsAuth : 135|2@0+ (1,0) [0|3] "" EOCM,EOCM_HCP2,EOCM_HC_Superset,HDLM
 SG_ FCODPB14P_CnstrObj3IDAuth : 147|5@0+ (1,0) [0|31] "" EOCM,EOCM_HCP2,EOCM_HC_Superset,HDLM
 SG_ FCODPB14P_CnstrObj3CnfdStsAuth : 149|2@0+ (1,0) [0|3] "" EOCM,EOCM_HCP2,EOCM_HC_Superset,HDLM
 SG_ FCODPB14P_CnstrObj2TypAuth : 151|2@0+ (1,0) [0|3] "" EOCM,EOCM_HCP2,EOCM_HC_Superset,HDLM
 SG_ FCODPB14P_CnstrObj3LatDistAuth : 158|9@0- (0.125,0) [-32|31.875] "m" EOCM,EOCM_HCP2,EOCM_HC_Superset,HDLM
 SG_ FCODPB14P_CnstrObj4IDAuth : 161|5@0+ (1,0) [0|31] "" EOCM,EOCM_HCP2,EOCM_HC_Superset,HDLM
 SG_ FCODPB14P_CnstrObj4CnfdStsAuth : 163|2@0+ (1,0) [0|3] "" EOCM,EOCM_HCP2,EOCM_HC_Superset,HDLM
 SG_ FCODPB14P_CnstrObj3TypAuth : 165|2@0+ (1,0) [0|3] "" EOCM,EOCM_HCP2,EOCM_HC_Superset,HDLM
 SG_ FCODPB14P_CnstrObj4LatDistAuth : 172|9@0- (0.125,0) [-32|31.875] "m" EOCM,EOCM_HCP2,EOCM_HC_Superset,HDLM
 SG_ FCODPB14P_CnstrObj5CnfdStsAuth : 177|2@0+ (1,0) [0|3] "" EOCM,EOCM_HCP2,EOCM_HC_Superset,HDLM
 SG_ FCODPB14P_CnstrObj4TypAuth : 179|2@0+ (1,0) [0|3] "" EOCM,EOCM_HCP2,EOCM_HC_Superset,HDLM
 SG_ FCODPB14P_CnstrObj5LatDistAuth : 186|9@0- (0.125,0) [-32|31.875] "m" EOCM,EOCM_HCP2,EOCM_HC_Superset,HDLM
 SG_ FCODPB14P_CnstrObj5IDAuth : 191|5@0+ (1,0) [0|31] "" EOCM,EOCM_HCP2,EOCM_HC_Superset,HDLM
 SG_ FCODPB14P_CnstrObj5TypAuth : 193|2@0+ (1,0) [0|3] "" EOCM,EOCM_HCP2,EOCM_HC_Superset,HDLM
 SG_ FCODPB14P_CnstrObj6LatDistAuth : 200|9@0- (0.125,0) [-32|31.875] "m" EOCM,EOCM_HCP2,EOCM_HC_Superset,HDLM
 SG_ FCODPB14P_CnstrObj6IDAuth : 205|5@0+ (1,0) [0|31] "" EOCM,EOCM_HCP2,EOCM_HC_Superset,HDLM
 SG_ FCODPB14P_CnstrObj6CnfdStsAuth : 207|2@0+ (1,0) [0|3] "" EOCM,EOCM_HCP2,EOCM_HC_Superset,HDLM
 SG_ FCODPB14P_CnstrObj7IDAuth : 219|5@0+ (1,0) [0|31] "" EOCM,EOCM_HCP2,EOCM_HC_Superset,HDLM
 SG_ FCODPB14P_CnstrObj7CnfdStsAuth : 221|2@0+ (1,0) [0|3] "" EOCM,EOCM_HCP2,EOCM_HC_Superset,HDLM
 SG_ FCODPB14P_CnstrObj6TypAuth : 223|2@0+ (1,0) [0|3] "" EOCM,EOCM_HCP2,EOCM_HC_Superset,HDLM
 SG_ FCODPB14P_CnstrObj7LatDistAuth : 230|9@0- (0.125,0) [-32|31.875] "m" EOCM,EOCM_HCP2,EOCM_HC_Superset,HDLM
 SG_ FCODPB14P_CnstrObj8IDAuth : 233|5@0+ (1,0) [0|31] "" EOCM,EOCM_HCP2,EOCM_HC_Superset,HDLM
 SG_ FCODPB14P_CnstrObj8CnfdStsAuth : 235|2@0+ (1,0) [0|3] "" EOCM,EOCM_HCP2,EOCM_HC_Superset,HDLM
 SG_ FCODPB14P_CnstrObj7TypAuth : 237|2@0+ (1,0) [0|3] "" EOCM,EOCM_HCP2,EOCM_HC_Superset,HDLM
 SG_ FCODPB14P_CnstrObj8LatDistAuth : 244|9@0- (0.125,0) [-32|31.875] "m" EOCM,EOCM_HCP2,EOCM_HC_Superset,HDLM
 SG_ FCODPB14P_CnstrObj9CnfdStsAuth : 249|2@0+ (1,0) [0|3] "" EOCM,EOCM_HCP2,EOCM_HC_Superset,HDLM
 SG_ FCODPB14P_CnstrObj8TypAuth : 251|2@0+ (1,0) [0|3] "" EOCM,EOCM_HCP2,EOCM_HC_Superset,HDLM
 SG_ FCODPB14P_CnstrObj9LatDistAuth : 258|9@0- (0.125,0) [-32|31.875] "m" EOCM,EOCM_HCP2,EOCM_HC_Superset,HDLM
 SG_ FCODPB14P_CnstrObj9IDAuth : 263|5@0+ (1,0) [0|31] "" EOCM,EOCM_HCP2,EOCM_HC_Superset,HDLM
 SG_ FCODPB14P_CnstrObj9TypAuth : 265|2@0+ (1,0) [0|3] "" EOCM,EOCM_HCP2,EOCM_HC_Superset,HDLM
 SG_ FCODPB14P_FVTSTk8IDAuth : 277|6@0+ (1,0) [0|63] "" EOCM,EOCM_HCP2,EOCM_HC_Superset,HDLM
 SG_ FCODPB14P_FVTSTk8CnfdStsAuth : 279|2@0+ (1,0) [0|3] "" EOCM,EOCM_HCP2,EOCM_HC_Superset,HDLM
 SG_ FCODPB14P_FVTSTk8LatPsAuth : 287|9@0- (0.125,0) [-32|31.875] "m" EOCM,EOCM_HCP2,EOCM_HC_Superset,HDLM
 SG_ FCODPB14P_FVTSTk8LngPsAuth : 294|11@0- (0.125,0) [-128|127.875] "m" EOCM,EOCM_HCP2,EOCM_HC_Superset,HDLM
 SG_ FCODPB14P_FVTSTk8SupTypAuth : 297|6@0+ (1,0) [0|39] "" EOCM,EOCM_HCP2,EOCM_HC_Superset,HDLM
 SG_ FCODPB14P_FVTSTk8MeasStsAuth : 299|2@0+ (1,0) [0|3] "" EOCM,EOCM_HCP2,EOCM_HC_Superset,HDLM
 SG_ FCODPB14P_FVTSTk8TypAuth : 307|7@0+ (1,0) [0|75] "" EOCM,EOCM_HCP2,EOCM_HC_Superset,HDLM
 SG_ FCODPB14P_FVTSTk8VertPsAuth : 314|8@0+ (0.125,0) [0|31.875] "m" EOCM,EOCM_HCP2,EOCM_HC_Superset,HDLM
 SG_ FCODPB14P_FVTSTk8TypCnfdAuth : 316|2@0+ (1,0) [0|3] "" EOCM,EOCM_HCP2,EOCM_HC_Superset,HDLM
 SG_ FCODPB14P_FVTSTk9IDAuth : 320|6@0+ (1,0) [0|63] "" EOCM,EOCM_HCP2,EOCM_HC_Superset,HDLM
 SG_ FCODPB14P_FVTSTk9CnfdStsAuth : 322|2@0+ (1,0) [0|3] "" EOCM,EOCM_HCP2,EOCM_HC_Superset,HDLM
 SG_ FCODPB14P_FVTSTk9LatPsAuth : 330|9@0- (0.125,0) [-32|31.875] "m" EOCM,EOCM_HCP2,EOCM_HC_Superset,HDLM
 SG_ FCODPB14P_FVTSTk9LngPsAuth : 337|11@0- (0.125,0) [-128|127.875] "m" EOCM,EOCM_HCP2,EOCM_HC_Superset,HDLM
 SG_ FCODPB14P_FVTSTk9SupTypAuth : 356|6@0+ (1,0) [0|39] "" EOCM,EOCM_HCP2,EOCM_HC_Superset,HDLM
 SG_ FCODPB14P_FVTSTk9MeasStsAuth : 358|2@0+ (1,0) [0|3] "" EOCM,EOCM_HCP2,EOCM_HC_Superset,HDLM
 SG_ FCODPB14P_FVTSTk9TypAuth : 366|7@0+ (1,0) [0|75] "" EOCM,EOCM_HCP2,EOCM_HC_Superset,HDLM
 SG_ FCODPB14P_FVTSTk9VertPsAuth : 373|8@0+ (0.125,0) [0|31.875] "m" EOCM,EOCM_HCP2,EOCM_HC_Superset,HDLM
 SG_ FCODPB14P_FVTSTk9TypCnfdAuth : 375|2@0+ (1,0) [0|3] "" EOCM,EOCM_HCP2,EOCM_HC_Superset,HDLM
 SG_ FCODPB14P_Filler : 381|6@0+ (1,0) [0|63] "" EOCM,EOCM_HCP2,EOCM_HC_Superset,HDLM

BA_DEF_ SG_  "SignalType" STRING ;
BA_DEF_ SG_  "SignalLongName" STRING ;
BA_DEF_ BO_  "GenMsgCycleTime" INT 0 10000;
BA_DEF_ BO_  "GenMsgSendType" ENUM "cyclicX","spontanX","cyclicIfActiveX","spontanWithDelay","cyclicAndSpontanX","cyclicAndSpontanWithDelay","spontanWithRepetition","cyclicIfActiveAndSpontanWD";
BA_DEF_ BO_  "VFrameFormat" ENUM  "StandardCAN","ExtendedCAN","reserved","reserved","reserved","reserved","reserved","reserved","reserved","reserved","reserved","reserved","reserved","reserved","StandardCAN_FD","ExtendedCAN_FD";
BA_DEF_DEF_  "SignalType" "";
BA_DEF_DEF_  "SignalLongName" "";
BA_DEF_DEF_  "GenMsgCycleTime" 0;
BA_DEF_DEF_  "GenMsgSendType" "cyclicX";
BA_DEF_DEF_  "VFrameFormat" "StandardCAN";
BA_ "GenMsgCycleTime" BO_ 1434 1000;
BA_ "VFrameFormat" BO_ 1434 14;
BA_ "GenMsgCycleTime" BO_ 1435 1000;
BA_ "VFrameFormat" BO_ 1435 14;
BA_ "GenMsgCycleTime" BO_ 1436 1000;
BA_ "VFrameFormat" BO_ 1436 14;
BA_ "GenMsgCycleTime" BO_ 1437 1000;
BA_ "VFrameFormat" BO_ 1437 14;
BA_ "GenMsgCycleTime" BO_ 1438 1000;
BA_ "VFrameFormat" BO_ 1438 14;
BA_ "GenMsgCycleTime" BO_ 1439 1000;
BA_ "VFrameFormat" BO_ 1439 14;
BA_ "GenMsgCycleTime" BO_ 1440 1000;
BA_ "VFrameFormat" BO_ 1440 14;
BA_ "GenMsgCycleTime" BO_ 1441 1000;
BA_ "VFrameFormat" BO_ 1441 14;
BA_ "GenMsgCycleTime" BO_ 1465 1000;
BA_ "VFrameFormat" BO_ 1465 14;
BA_ "VFrameFormat" BO_ 928 14;
BA_ "VFrameFormat" BO_ 1407 14;
BA_ "VFrameFormat" BO_ 705 14;
BA_ "VFrameFormat" BO_ 671 14;
BA_ "GenMsgCycleTime" BO_ 528 50;
BA_ "VFrameFormat" BO_ 528 14;
BA_ "VFrameFormat" BO_ 1401 14;
BA_ "GenMsgCycleTime" BO_ 613 100;
BA_ "VFrameFormat" BO_ 613 14;
BA_ "GenMsgCycleTime" BO_ 2147745797 1000;
BA_ "GenMsgCycleTime" BO_ 2147745798 1000;
BA_ "GenMsgCycleTime" BO_ 2147745808 1000;
BA_ "GenMsgCycleTime" BO_ 2147745809 1000;
BA_ "VFrameFormat" BO_ 658 14;
BA_ "VFrameFormat" BO_ 238 14;
BA_ "VFrameFormat" BO_ 217 14;
BA_ "VFrameFormat" BO_ 239 14;
BA_ "VFrameFormat" BO_ 216 14;
BA_ "SignalLongName" SG_ 1434 DTCI_HDLM_DTCFailType "Diagnostic Trouble Code Information Extended - HDLM : Diagnostic Trouble Code Failure Type";
BA_ "SignalType" SG_ 1434 DTCI_HDLM_CnfrmdDTC "ENM";
BA_ "SignalLongName" SG_ 1434 DTCI_HDLM_CnfrmdDTC "Diagnostic Trouble Code Information Extended - HDLM : Confirmed DTC";
BA_ "SignalType" SG_ 1434 DTCI_HDLM_DTCFaultType "ENM";
BA_ "SignalLongName" SG_ 1434 DTCI_HDLM_DTCFaultType "Diagnostic Trouble Code Information Extended - HDLM : Diagnostic Trouble Code Fault Type";
BA_ "SignalLongName" SG_ 1434 DTCI_HDLM_DTCNumber "Diagnostic Trouble Code Information Extended - HDLM : Diagnostic Trouble Code Number";
BA_ "SignalLongName" SG_ 1434 DTCI_HDLM_DTCSource "Diagnostic Trouble Code Information Extended - HDLM : Diagnostic Trouble Code Source";
BA_ "SignalType" SG_ 1434 DTCI_HDLM_TstNCmpltdOpCyc "ENM";
BA_ "SignalLongName" SG_ 1434 DTCI_HDLM_TstNCmpltdOpCyc "Diagnostic Trouble Code Information Extended - HDLM : Test Not Completed This Operation Cycle";
BA_ "SignalType" SG_ 1434 DTCI_HDLM_TstNCmpltdLstClr "ENM";
BA_ "SignalLongName" SG_ 1434 DTCI_HDLM_TstNCmpltdLstClr "Diagnostic Trouble Code Information Extended - HDLM : Test Not Completed Since Last Clear";
BA_ "SignalType" SG_ 1434 DTCI_HDLM_TstFldOpCyc "ENM";
BA_ "SignalLongName" SG_ 1434 DTCI_HDLM_TstFldOpCyc "Diagnostic Trouble Code Information Extended - HDLM : Test Failed This Operation Cycle";
BA_ "SignalType" SG_ 1434 DTCI_HDLM_TstFldLstClr "ENM";
BA_ "SignalLongName" SG_ 1434 DTCI_HDLM_TstFldLstClr "Diagnostic Trouble Code Information Extended - HDLM : Test Failed Since Last Clear";
BA_ "SignalType" SG_ 1434 DTCI_HDLM_TstFld "ENM";
BA_ "SignalLongName" SG_ 1434 DTCI_HDLM_TstFld "Diagnostic Trouble Code Information Extended - HDLM : Test Failed";
BA_ "SignalType" SG_ 1434 DTCI_HDLM_PndngDTC "ENM";
BA_ "SignalLongName" SG_ 1434 DTCI_HDLM_PndngDTC "Diagnostic Trouble Code Information Extended - HDLM : Pending DTC";
BA_ "SignalType" SG_ 1434 DTCI_HDLM_DTCTriggered "ENM";
BA_ "SignalLongName" SG_ 1434 DTCI_HDLM_DTCTriggered "Diagnostic Trouble Code Information Extended - HDLM : Diagnostic Trouble Code Triggered";
BA_ "SignalType" SG_ 1434 DTCI_HDLM_WrnIndTrggrd "ENM";
BA_ "SignalLongName" SG_ 1434 DTCI_HDLM_WrnIndTrggrd "Diagnostic Trouble Code Information Extended - HDLM : Warning Indicator Triggered";
BA_ "SignalType" SG_ 1434 DTCI_HDLM_WrnIndRqd "ENM";
BA_ "SignalLongName" SG_ 1434 DTCI_HDLM_WrnIndRqd "Diagnostic Trouble Code Information Extended - HDLM : Warning Indicator Requested";
BA_ "SignalLongName" SG_ 1435 DTCI_LRR_DTCFailType "Diagnostic Trouble Code Information Extended - LRR : Diagnostic Trouble Code Failure Type";
BA_ "SignalType" SG_ 1435 DTCI_LRR_CnfrmdDTC "ENM";
BA_ "SignalLongName" SG_ 1435 DTCI_LRR_CnfrmdDTC "Diagnostic Trouble Code Information Extended - LRR : Confirmed DTC";
BA_ "SignalType" SG_ 1435 DTCI_LRR_DTCFaultType "ENM";
BA_ "SignalLongName" SG_ 1435 DTCI_LRR_DTCFaultType "Diagnostic Trouble Code Information Extended - LRR : Diagnostic Trouble Code Fault Type";
BA_ "SignalLongName" SG_ 1435 DTCI_LRR_DTCNumber "Diagnostic Trouble Code Information Extended - LRR : Diagnostic Trouble Code Number";
BA_ "SignalLongName" SG_ 1435 DTCI_LRR_DTCSource "Diagnostic Trouble Code Information Extended - LRR : Diagnostic Trouble Code Source";
BA_ "SignalType" SG_ 1435 DTCI_LRR_TstNCmpltdOpCyc "ENM";
BA_ "SignalLongName" SG_ 1435 DTCI_LRR_TstNCmpltdOpCyc "Diagnostic Trouble Code Information Extended - LRR : Test Not Completed This Operation Cycle";
BA_ "SignalType" SG_ 1435 DTCI_LRR_TstNCmpltdLstClr "ENM";
BA_ "SignalLongName" SG_ 1435 DTCI_LRR_TstNCmpltdLstClr "Diagnostic Trouble Code Information Extended - LRR : Test Not Completed Since Last Clear";
BA_ "SignalType" SG_ 1435 DTCI_LRR_TstFldOpCyc "ENM";
BA_ "SignalLongName" SG_ 1435 DTCI_LRR_TstFldOpCyc "Diagnostic Trouble Code Information Extended - LRR : Test Failed This Operation Cycle";
BA_ "SignalType" SG_ 1435 DTCI_LRR_TstFldLstClr "ENM";
BA_ "SignalLongName" SG_ 1435 DTCI_LRR_TstFldLstClr "Diagnostic Trouble Code Information Extended - LRR : Test Failed Since Last Clear";
BA_ "SignalType" SG_ 1435 DTCI_LRR_TstFld "ENM";
BA_ "SignalLongName" SG_ 1435 DTCI_LRR_TstFld "Diagnostic Trouble Code Information Extended - LRR : Test Failed";
BA_ "SignalType" SG_ 1435 DTCI_LRR_PndngDTC "ENM";
BA_ "SignalLongName" SG_ 1435 DTCI_LRR_PndngDTC "Diagnostic Trouble Code Information Extended - LRR : Pending DTC";
BA_ "SignalType" SG_ 1435 DTCI_LRR_DTCTriggered "ENM";
BA_ "SignalLongName" SG_ 1435 DTCI_LRR_DTCTriggered "Diagnostic Trouble Code Information Extended - LRR : Diagnostic Trouble Code Triggered";
BA_ "SignalType" SG_ 1435 DTCI_LRR_WrnIndTrggrd "ENM";
BA_ "SignalLongName" SG_ 1435 DTCI_LRR_WrnIndTrggrd "Diagnostic Trouble Code Information Extended - LRR : Warning Indicator Triggered";
BA_ "SignalType" SG_ 1435 DTCI_LRR_WrnIndRqd "ENM";
BA_ "SignalLongName" SG_ 1435 DTCI_LRR_WrnIndRqd "Diagnostic Trouble Code Information Extended - LRR : Warning Indicator Requested";
BA_ "SignalLongName" SG_ 1436 DTCI_SRR_LF_DTCFailType "Diagnostic Trouble Code Information Extended - SRR_LF : Diagnostic Trouble Code Failure Type";
BA_ "SignalType" SG_ 1436 DTCI_SRR_LF_CnfrmdDTC "ENM";
BA_ "SignalLongName" SG_ 1436 DTCI_SRR_LF_CnfrmdDTC "Diagnostic Trouble Code Information Extended - SRR_LF : Confirmed DTC";
BA_ "SignalType" SG_ 1436 DTCI_SRR_LF_DTCFaultType "ENM";
BA_ "SignalLongName" SG_ 1436 DTCI_SRR_LF_DTCFaultType "Diagnostic Trouble Code Information Extended - SRR_LF : Diagnostic Trouble Code Fault Type";
BA_ "SignalLongName" SG_ 1436 DTCI_SRR_LF_DTCNumber "Diagnostic Trouble Code Information Extended - SRR_LF : Diagnostic Trouble Code Number";
BA_ "SignalLongName" SG_ 1436 DTCI_SRR_LF_DTCSource "Diagnostic Trouble Code Information Extended - SRR_LF : Diagnostic Trouble Code Source";
BA_ "SignalType" SG_ 1436 DTCI_SRR_LF_TstNCmpltdOpCyc "ENM";
BA_ "SignalLongName" SG_ 1436 DTCI_SRR_LF_TstNCmpltdOpCyc "Diagnostic Trouble Code Information Extended - SRR_LF : Test Not Completed This Operation Cycle";
BA_ "SignalType" SG_ 1436 DTCI_SRR_LF_TstNCmpltdLstClr "ENM";
BA_ "SignalLongName" SG_ 1436 DTCI_SRR_LF_TstNCmpltdLstClr "Diagnostic Trouble Code Information Extended - SRR_LF : Test Not Completed Since Last Clear";
BA_ "SignalType" SG_ 1436 DTCI_SRR_LF_TstFldOpCyc "ENM";
BA_ "SignalLongName" SG_ 1436 DTCI_SRR_LF_TstFldOpCyc "Diagnostic Trouble Code Information Extended - SRR_LF : Test Failed This Operation Cycle";
BA_ "SignalType" SG_ 1436 DTCI_SRR_LF_TstFldLstClr "ENM";
BA_ "SignalLongName" SG_ 1436 DTCI_SRR_LF_TstFldLstClr "Diagnostic Trouble Code Information Extended - SRR_LF : Test Failed Since Last Clear";
BA_ "SignalType" SG_ 1436 DTCI_SRR_LF_TstFld "ENM";
BA_ "SignalLongName" SG_ 1436 DTCI_SRR_LF_TstFld "Diagnostic Trouble Code Information Extended - SRR_LF : Test Failed";
BA_ "SignalType" SG_ 1436 DTCI_SRR_LF_PndngDTC "ENM";
BA_ "SignalLongName" SG_ 1436 DTCI_SRR_LF_PndngDTC "Diagnostic Trouble Code Information Extended - SRR_LF : Pending DTC";
BA_ "SignalType" SG_ 1436 DTCI_SRR_LF_DTCTriggered "ENM";
BA_ "SignalLongName" SG_ 1436 DTCI_SRR_LF_DTCTriggered "Diagnostic Trouble Code Information Extended - SRR_LF : Diagnostic Trouble Code Triggered";
BA_ "SignalType" SG_ 1436 DTCI_SRR_LF_WrnIndTrggrd "ENM";
BA_ "SignalLongName" SG_ 1436 DTCI_SRR_LF_WrnIndTrggrd "Diagnostic Trouble Code Information Extended - SRR_LF : Warning Indicator Triggered";
BA_ "SignalType" SG_ 1436 DTCI_SRR_LF_WrnIndRqd "ENM";
BA_ "SignalLongName" SG_ 1436 DTCI_SRR_LF_WrnIndRqd "Diagnostic Trouble Code Information Extended - SRR_LF : Warning Indicator Requested";
BA_ "SignalLongName" SG_ 1437 DTCI_SRR_LR_CR_DTCFailType "Diagnostic Trouble Code Information Extended - SRR_LR_CR : Diagnostic Trouble Code Failure Type";
BA_ "SignalType" SG_ 1437 DTCI_SRR_LR_CR_CnfrmdDTC "ENM";
BA_ "SignalLongName" SG_ 1437 DTCI_SRR_LR_CR_CnfrmdDTC "Diagnostic Trouble Code Information Extended - SRR_LR_CR : Confirmed DTC";
BA_ "SignalType" SG_ 1437 DTCI_SRR_LR_CR_DTCFaultType "ENM";
BA_ "SignalLongName" SG_ 1437 DTCI_SRR_LR_CR_DTCFaultType "Diagnostic Trouble Code Information Extended - SRR_LR_CR : Diagnostic Trouble Code Fault Type";
BA_ "SignalLongName" SG_ 1437 DTCI_SRR_LR_CR_DTCNumber "Diagnostic Trouble Code Information Extended - SRR_LR_CR : Diagnostic Trouble Code Number";
BA_ "SignalLongName" SG_ 1437 DTCI_SRR_LR_CR_DTCSource "Diagnostic Trouble Code Information Extended - SRR_LR_CR : Diagnostic Trouble Code Source";
BA_ "SignalType" SG_ 1437 DTCI_SRR_LR_CR_TstNCmpltdOpCyc "ENM";
BA_ "SignalLongName" SG_ 1437 DTCI_SRR_LR_CR_TstNCmpltdOpCyc "Diagnostic Trouble Code Information Extended - SRR_LR_CR : Test Not Completed This Operation Cycle";
BA_ "SignalType" SG_ 1437 DTCI_SRR_LR_CR_TstNCmpltdLstClr "ENM";
BA_ "SignalLongName" SG_ 1437 DTCI_SRR_LR_CR_TstNCmpltdLstClr "Diagnostic Trouble Code Information Extended - SRR_LR_CR : Test Not Completed Since Last Clear";
BA_ "SignalType" SG_ 1437 DTCI_SRR_LR_CR_TstFldOpCyc "ENM";
BA_ "SignalLongName" SG_ 1437 DTCI_SRR_LR_CR_TstFldOpCyc "Diagnostic Trouble Code Information Extended - SRR_LR_CR : Test Failed This Operation Cycle";
BA_ "SignalType" SG_ 1437 DTCI_SRR_LR_CR_TstFldLstClr "ENM";
BA_ "SignalLongName" SG_ 1437 DTCI_SRR_LR_CR_TstFldLstClr "Diagnostic Trouble Code Information Extended - SRR_LR_CR : Test Failed Since Last Clear";
BA_ "SignalType" SG_ 1437 DTCI_SRR_LR_CR_TstFld "ENM";
BA_ "SignalLongName" SG_ 1437 DTCI_SRR_LR_CR_TstFld "Diagnostic Trouble Code Information Extended - SRR_LR_CR : Test Failed";
BA_ "SignalType" SG_ 1437 DTCI_SRR_LR_CR_PndngDTC "ENM";
BA_ "SignalLongName" SG_ 1437 DTCI_SRR_LR_CR_PndngDTC "Diagnostic Trouble Code Information Extended - SRR_LR_CR : Pending DTC";
BA_ "SignalType" SG_ 1437 DTCI_SRR_LR_CR_DTCTriggered "ENM";
BA_ "SignalLongName" SG_ 1437 DTCI_SRR_LR_CR_DTCTriggered "Diagnostic Trouble Code Information Extended - SRR_LR_CR : Diagnostic Trouble Code Triggered";
BA_ "SignalType" SG_ 1437 DTCI_SRR_LR_CR_WrnIndTrggrd "ENM";
BA_ "SignalLongName" SG_ 1437 DTCI_SRR_LR_CR_WrnIndTrggrd "Diagnostic Trouble Code Information Extended - SRR_LR_CR : Warning Indicator Triggered";
BA_ "SignalType" SG_ 1437 DTCI_SRR_LR_CR_WrnIndRqd "ENM";
BA_ "SignalLongName" SG_ 1437 DTCI_SRR_LR_CR_WrnIndRqd "Diagnostic Trouble Code Information Extended - SRR_LR_CR : Warning Indicator Requested";
BA_ "SignalLongName" SG_ 1438 DTCI_SRR_RF_DTCFailType "Diagnostic Trouble Code Information Extended - SRR_RF : Diagnostic Trouble Code Failure Type";
BA_ "SignalType" SG_ 1438 DTCI_SRR_RF_CnfrmdDTC "ENM";
BA_ "SignalLongName" SG_ 1438 DTCI_SRR_RF_CnfrmdDTC "Diagnostic Trouble Code Information Extended - SRR_RF : Confirmed DTC";
BA_ "SignalType" SG_ 1438 DTCI_SRR_RF_DTCFaultType "ENM";
BA_ "SignalLongName" SG_ 1438 DTCI_SRR_RF_DTCFaultType "Diagnostic Trouble Code Information Extended - SRR_RF : Diagnostic Trouble Code Fault Type";
BA_ "SignalLongName" SG_ 1438 DTCI_SRR_RF_DTCNumber "Diagnostic Trouble Code Information Extended - SRR_RF : Diagnostic Trouble Code Number";
BA_ "SignalLongName" SG_ 1438 DTCI_SRR_RF_DTCSource "Diagnostic Trouble Code Information Extended - SRR_RF : Diagnostic Trouble Code Source";
BA_ "SignalType" SG_ 1438 DTCI_SRR_RF_TstNCmpltdOpCyc "ENM";
BA_ "SignalLongName" SG_ 1438 DTCI_SRR_RF_TstNCmpltdOpCyc "Diagnostic Trouble Code Information Extended - SRR_RF : Test Not Completed This Operation Cycle";
BA_ "SignalType" SG_ 1438 DTCI_SRR_RF_TstNCmpltdLstClr "ENM";
BA_ "SignalLongName" SG_ 1438 DTCI_SRR_RF_TstNCmpltdLstClr "Diagnostic Trouble Code Information Extended - SRR_RF : Test Not Completed Since Last Clear";
BA_ "SignalType" SG_ 1438 DTCI_SRR_RF_TstFldOpCyc "ENM";
BA_ "SignalLongName" SG_ 1438 DTCI_SRR_RF_TstFldOpCyc "Diagnostic Trouble Code Information Extended - SRR_RF : Test Failed This Operation Cycle";
BA_ "SignalType" SG_ 1438 DTCI_SRR_RF_TstFldLstClr "ENM";
BA_ "SignalLongName" SG_ 1438 DTCI_SRR_RF_TstFldLstClr "Diagnostic Trouble Code Information Extended - SRR_RF : Test Failed Since Last Clear";
BA_ "SignalType" SG_ 1438 DTCI_SRR_RF_TstFld "ENM";
BA_ "SignalLongName" SG_ 1438 DTCI_SRR_RF_TstFld "Diagnostic Trouble Code Information Extended - SRR_RF : Test Failed";
BA_ "SignalType" SG_ 1438 DTCI_SRR_RF_PndngDTC "ENM";
BA_ "SignalLongName" SG_ 1438 DTCI_SRR_RF_PndngDTC "Diagnostic Trouble Code Information Extended - SRR_RF : Pending DTC";
BA_ "SignalType" SG_ 1438 DTCI_SRR_RF_DTCTriggered "ENM";
BA_ "SignalLongName" SG_ 1438 DTCI_SRR_RF_DTCTriggered "Diagnostic Trouble Code Information Extended - SRR_RF : Diagnostic Trouble Code Triggered";
BA_ "SignalType" SG_ 1438 DTCI_SRR_RF_WrnIndTrggrd "ENM";
BA_ "SignalLongName" SG_ 1438 DTCI_SRR_RF_WrnIndTrggrd "Diagnostic Trouble Code Information Extended - SRR_RF : Warning Indicator Triggered";
BA_ "SignalType" SG_ 1438 DTCI_SRR_RF_WrnIndRqd "ENM";
BA_ "SignalLongName" SG_ 1438 DTCI_SRR_RF_WrnIndRqd "Diagnostic Trouble Code Information Extended - SRR_RF : Warning Indicator Requested";
BA_ "SignalLongName" SG_ 1439 DTCI_SRR_RR_DTCFailType "Diagnostic Trouble Code Information Extended - SRR_RR : Diagnostic Trouble Code Failure Type";
BA_ "SignalType" SG_ 1439 DTCI_SRR_RR_CnfrmdDTC "ENM";
BA_ "SignalLongName" SG_ 1439 DTCI_SRR_RR_CnfrmdDTC "Diagnostic Trouble Code Information Extended - SRR_RR : Confirmed DTC";
BA_ "SignalType" SG_ 1439 DTCI_SRR_RR_DTCFaultType "ENM";
BA_ "SignalLongName" SG_ 1439 DTCI_SRR_RR_DTCFaultType "Diagnostic Trouble Code Information Extended - SRR_RR : Diagnostic Trouble Code Fault Type";
BA_ "SignalLongName" SG_ 1439 DTCI_SRR_RR_DTCNumber "Diagnostic Trouble Code Information Extended - SRR_RR : Diagnostic Trouble Code Number";
BA_ "SignalLongName" SG_ 1439 DTCI_SRR_RR_DTCSource "Diagnostic Trouble Code Information Extended - SRR_RR : Diagnostic Trouble Code Source";
BA_ "SignalType" SG_ 1439 DTCI_SRR_RR_TstNCmpltdOpCyc "ENM";
BA_ "SignalLongName" SG_ 1439 DTCI_SRR_RR_TstNCmpltdOpCyc "Diagnostic Trouble Code Information Extended - SRR_RR : Test Not Completed This Operation Cycle";
BA_ "SignalType" SG_ 1439 DTCI_SRR_RR_TstNCmpltdLstClr "ENM";
BA_ "SignalLongName" SG_ 1439 DTCI_SRR_RR_TstNCmpltdLstClr "Diagnostic Trouble Code Information Extended - SRR_RR : Test Not Completed Since Last Clear";
BA_ "SignalType" SG_ 1439 DTCI_SRR_RR_TstFldOpCyc "ENM";
BA_ "SignalLongName" SG_ 1439 DTCI_SRR_RR_TstFldOpCyc "Diagnostic Trouble Code Information Extended - SRR_RR : Test Failed This Operation Cycle";
BA_ "SignalType" SG_ 1439 DTCI_SRR_RR_TstFldLstClr "ENM";
BA_ "SignalLongName" SG_ 1439 DTCI_SRR_RR_TstFldLstClr "Diagnostic Trouble Code Information Extended - SRR_RR : Test Failed Since Last Clear";
BA_ "SignalType" SG_ 1439 DTCI_SRR_RR_TstFld "ENM";
BA_ "SignalLongName" SG_ 1439 DTCI_SRR_RR_TstFld "Diagnostic Trouble Code Information Extended - SRR_RR : Test Failed";
BA_ "SignalType" SG_ 1439 DTCI_SRR_RR_PndngDTC "ENM";
BA_ "SignalLongName" SG_ 1439 DTCI_SRR_RR_PndngDTC "Diagnostic Trouble Code Information Extended - SRR_RR : Pending DTC";
BA_ "SignalType" SG_ 1439 DTCI_SRR_RR_DTCTriggered "ENM";
BA_ "SignalLongName" SG_ 1439 DTCI_SRR_RR_DTCTriggered "Diagnostic Trouble Code Information Extended - SRR_RR : Diagnostic Trouble Code Triggered";
BA_ "SignalType" SG_ 1439 DTCI_SRR_RR_WrnIndTrggrd "ENM";
BA_ "SignalLongName" SG_ 1439 DTCI_SRR_RR_WrnIndTrggrd "Diagnostic Trouble Code Information Extended - SRR_RR : Warning Indicator Triggered";
BA_ "SignalType" SG_ 1439 DTCI_SRR_RR_WrnIndRqd "ENM";
BA_ "SignalLongName" SG_ 1439 DTCI_SRR_RR_WrnIndRqd "Diagnostic Trouble Code Information Extended - SRR_RR : Warning Indicator Requested";
BA_ "SignalLongName" SG_ 1440 DTCI_SRR_SLR_DTCFailType "Diagnostic Trouble Code Information Extended - SRR_SLR : Diagnostic Trouble Code Failure Type";
BA_ "SignalType" SG_ 1440 DTCI_SRR_SLR_CnfrmdDTC "ENM";
BA_ "SignalLongName" SG_ 1440 DTCI_SRR_SLR_CnfrmdDTC "Diagnostic Trouble Code Information Extended - SRR_SLR : Confirmed DTC";
BA_ "SignalType" SG_ 1440 DTCI_SRR_SLR_DTCFaultType "ENM";
BA_ "SignalLongName" SG_ 1440 DTCI_SRR_SLR_DTCFaultType "Diagnostic Trouble Code Information Extended - SRR_SLR : Diagnostic Trouble Code Fault Type";
BA_ "SignalLongName" SG_ 1440 DTCI_SRR_SLR_DTCNumber "Diagnostic Trouble Code Information Extended - SRR_SLR : Diagnostic Trouble Code Number";
BA_ "SignalLongName" SG_ 1440 DTCI_SRR_SLR_DTCSource "Diagnostic Trouble Code Information Extended - SRR_SLR : Diagnostic Trouble Code Source";
BA_ "SignalType" SG_ 1440 DTCI_SRR_SLR_TstNCmpltdOpCyc "ENM";
BA_ "SignalLongName" SG_ 1440 DTCI_SRR_SLR_TstNCmpltdOpCyc "Diagnostic Trouble Code Information Extended - SRR_SLR : Test Not Completed This Operation Cycle";
BA_ "SignalType" SG_ 1440 DTCI_SRR_SLR_TstNCmpltdLstClr "ENM";
BA_ "SignalLongName" SG_ 1440 DTCI_SRR_SLR_TstNCmpltdLstClr "Diagnostic Trouble Code Information Extended - SRR_SLR : Test Not Completed Since Last Clear";
BA_ "SignalType" SG_ 1440 DTCI_SRR_SLR_TstFldOpCyc "ENM";
BA_ "SignalLongName" SG_ 1440 DTCI_SRR_SLR_TstFldOpCyc "Diagnostic Trouble Code Information Extended - SRR_SLR : Test Failed This Operation Cycle";
BA_ "SignalType" SG_ 1440 DTCI_SRR_SLR_TstFldLstClr "ENM";
BA_ "SignalLongName" SG_ 1440 DTCI_SRR_SLR_TstFldLstClr "Diagnostic Trouble Code Information Extended - SRR_SLR : Test Failed Since Last Clear";
BA_ "SignalType" SG_ 1440 DTCI_SRR_SLR_TstFld "ENM";
BA_ "SignalLongName" SG_ 1440 DTCI_SRR_SLR_TstFld "Diagnostic Trouble Code Information Extended - SRR_SLR : Test Failed";
BA_ "SignalType" SG_ 1440 DTCI_SRR_SLR_PndngDTC "ENM";
BA_ "SignalLongName" SG_ 1440 DTCI_SRR_SLR_PndngDTC "Diagnostic Trouble Code Information Extended - SRR_SLR : Pending DTC";
BA_ "SignalType" SG_ 1440 DTCI_SRR_SLR_DTCTriggered "ENM";
BA_ "SignalLongName" SG_ 1440 DTCI_SRR_SLR_DTCTriggered "Diagnostic Trouble Code Information Extended - SRR_SLR : Diagnostic Trouble Code Triggered";
BA_ "SignalType" SG_ 1440 DTCI_SRR_SLR_WrnIndTrggrd "ENM";
BA_ "SignalLongName" SG_ 1440 DTCI_SRR_SLR_WrnIndTrggrd "Diagnostic Trouble Code Information Extended - SRR_SLR : Warning Indicator Triggered";
BA_ "SignalType" SG_ 1440 DTCI_SRR_SLR_WrnIndRqd "ENM";
BA_ "SignalLongName" SG_ 1440 DTCI_SRR_SLR_WrnIndRqd "Diagnostic Trouble Code Information Extended - SRR_SLR : Warning Indicator Requested";
BA_ "SignalLongName" SG_ 1441 DTCI_SRR_SRR_DTCFailType "Diagnostic Trouble Code Information Extended - SRR_SRR : Diagnostic Trouble Code Failure Type";
BA_ "SignalType" SG_ 1441 DTCI_SRR_SRR_CnfrmdDTC "ENM";
BA_ "SignalLongName" SG_ 1441 DTCI_SRR_SRR_CnfrmdDTC "Diagnostic Trouble Code Information Extended - SRR_SRR : Confirmed DTC";
BA_ "SignalType" SG_ 1441 DTCI_SRR_SRR_DTCFaultType "ENM";
BA_ "SignalLongName" SG_ 1441 DTCI_SRR_SRR_DTCFaultType "Diagnostic Trouble Code Information Extended - SRR_SRR : Diagnostic Trouble Code Fault Type";
BA_ "SignalLongName" SG_ 1441 DTCI_SRR_SRR_DTCNumber "Diagnostic Trouble Code Information Extended - SRR_SRR : Diagnostic Trouble Code Number";
BA_ "SignalLongName" SG_ 1441 DTCI_SRR_SRR_DTCSource "Diagnostic Trouble Code Information Extended - SRR_SRR : Diagnostic Trouble Code Source";
BA_ "SignalType" SG_ 1441 DTCI_SRR_SRR_TstNCmpltdOpCyc "ENM";
BA_ "SignalLongName" SG_ 1441 DTCI_SRR_SRR_TstNCmpltdOpCyc "Diagnostic Trouble Code Information Extended - SRR_SRR : Test Not Completed This Operation Cycle";
BA_ "SignalType" SG_ 1441 DTCI_SRR_SRR_TstNCmpltdLstClr "ENM";
BA_ "SignalLongName" SG_ 1441 DTCI_SRR_SRR_TstNCmpltdLstClr "Diagnostic Trouble Code Information Extended - SRR_SRR : Test Not Completed Since Last Clear";
BA_ "SignalType" SG_ 1441 DTCI_SRR_SRR_TstFldOpCyc "ENM";
BA_ "SignalLongName" SG_ 1441 DTCI_SRR_SRR_TstFldOpCyc "Diagnostic Trouble Code Information Extended - SRR_SRR : Test Failed This Operation Cycle";
BA_ "SignalType" SG_ 1441 DTCI_SRR_SRR_TstFldLstClr "ENM";
BA_ "SignalLongName" SG_ 1441 DTCI_SRR_SRR_TstFldLstClr "Diagnostic Trouble Code Information Extended - SRR_SRR : Test Failed Since Last Clear";
BA_ "SignalType" SG_ 1441 DTCI_SRR_SRR_TstFld "ENM";
BA_ "SignalLongName" SG_ 1441 DTCI_SRR_SRR_TstFld "Diagnostic Trouble Code Information Extended - SRR_SRR : Test Failed";
BA_ "SignalType" SG_ 1441 DTCI_SRR_SRR_PndngDTC "ENM";
BA_ "SignalLongName" SG_ 1441 DTCI_SRR_SRR_PndngDTC "Diagnostic Trouble Code Information Extended - SRR_SRR : Pending DTC";
BA_ "SignalType" SG_ 1441 DTCI_SRR_SRR_DTCTriggered "ENM";
BA_ "SignalLongName" SG_ 1441 DTCI_SRR_SRR_DTCTriggered "Diagnostic Trouble Code Information Extended - SRR_SRR : Diagnostic Trouble Code Triggered";
BA_ "SignalType" SG_ 1441 DTCI_SRR_SRR_WrnIndTrggrd "ENM";
BA_ "SignalLongName" SG_ 1441 DTCI_SRR_SRR_WrnIndTrggrd "Diagnostic Trouble Code Information Extended - SRR_SRR : Warning Indicator Triggered";
BA_ "SignalType" SG_ 1441 DTCI_SRR_SRR_WrnIndRqd "ENM";
BA_ "SignalLongName" SG_ 1441 DTCI_SRR_SRR_WrnIndRqd "Diagnostic Trouble Code Information Extended - SRR_SRR : Warning Indicator Requested";
BA_ "SignalLongName" SG_ 1465 DTCI_UPM_DTCFailType "Diagnostic Trouble Code Information Extended - UPM : Diagnostic Trouble Code Failure Type";
BA_ "SignalType" SG_ 1465 DTCI_UPM_CnfrmdDTC "ENM";
BA_ "SignalLongName" SG_ 1465 DTCI_UPM_CnfrmdDTC "Diagnostic Trouble Code Information Extended - UPM : Confirmed DTC";
BA_ "SignalType" SG_ 1465 DTCI_UPM_DTCFaultType "ENM";
BA_ "SignalLongName" SG_ 1465 DTCI_UPM_DTCFaultType "Diagnostic Trouble Code Information Extended - UPM : Diagnostic Trouble Code Fault Type";
BA_ "SignalLongName" SG_ 1465 DTCI_UPM_DTCNumber "Diagnostic Trouble Code Information Extended - UPM : Diagnostic Trouble Code Number";
BA_ "SignalLongName" SG_ 1465 DTCI_UPM_DTCSource "Diagnostic Trouble Code Information Extended - UPM : Diagnostic Trouble Code Source";
BA_ "SignalType" SG_ 1465 DTCI_UPM_TstNCmpltdOpCyc "ENM";
BA_ "SignalLongName" SG_ 1465 DTCI_UPM_TstNCmpltdOpCyc "Diagnostic Trouble Code Information Extended - UPM : Test Not Completed This Operation Cycle";
BA_ "SignalType" SG_ 1465 DTCI_UPM_TstNCmpltdLstClr "ENM";
BA_ "SignalLongName" SG_ 1465 DTCI_UPM_TstNCmpltdLstClr "Diagnostic Trouble Code Information Extended - UPM : Test Not Completed Since Last Clear";
BA_ "SignalType" SG_ 1465 DTCI_UPM_TstFldOpCyc "ENM";
BA_ "SignalLongName" SG_ 1465 DTCI_UPM_TstFldOpCyc "Diagnostic Trouble Code Information Extended - UPM : Test Failed This Operation Cycle";
BA_ "SignalType" SG_ 1465 DTCI_UPM_TstFldLstClr "ENM";
BA_ "SignalLongName" SG_ 1465 DTCI_UPM_TstFldLstClr "Diagnostic Trouble Code Information Extended - UPM : Test Failed Since Last Clear";
BA_ "SignalType" SG_ 1465 DTCI_UPM_TstFld "ENM";
BA_ "SignalLongName" SG_ 1465 DTCI_UPM_TstFld "Diagnostic Trouble Code Information Extended - UPM : Test Failed";
BA_ "SignalType" SG_ 1465 DTCI_UPM_PndngDTC "ENM";
BA_ "SignalLongName" SG_ 1465 DTCI_UPM_PndngDTC "Diagnostic Trouble Code Information Extended - UPM : Pending DTC";
BA_ "SignalType" SG_ 1465 DTCI_UPM_DTCTriggered "ENM";
BA_ "SignalLongName" SG_ 1465 DTCI_UPM_DTCTriggered "Diagnostic Trouble Code Information Extended - UPM : Diagnostic Trouble Code Triggered";
BA_ "SignalType" SG_ 1465 DTCI_UPM_WrnIndTrggrd "ENM";
BA_ "SignalLongName" SG_ 1465 DTCI_UPM_WrnIndTrggrd "Diagnostic Trouble Code Information Extended - UPM : Warning Indicator Triggered";
BA_ "SignalType" SG_ 1465 DTCI_UPM_WrnIndRqd "ENM";
BA_ "SignalLongName" SG_ 1465 DTCI_UPM_WrnIndRqd "Diagnostic Trouble Code Information Extended - UPM : Warning Indicator Requested";
BA_ "SignalType" SG_ 928 EASSI_StrtStpSt "ENM";
BA_ "SignalLongName" SG_ 928 EASSI_StrtStpSt "Engine Auto Start Stop Information : Start Stop State";
BA_ "SignalType" SG_ 1407 ACCAutoStSpStat "ENM";
BA_ "SignalLongName" SG_ 1407 ACCAutoStSpStat "Adaptive Cruise Control Information 1 : Adaptive Cruise Control Auto Set Speed Status";
BA_ "SignalType" SG_ 705 EPBSP_ElecPrkBrkApplStsAuth "ENM";
BA_ "SignalLongName" SG_ 705 EPBSP_ElecPrkBrkApplStsAuth "Serial Data 15 Protected : Electric Park Brake Application Status Authenticated";
BA_ "SignalLongName" SG_ 671 EOCMGnrlInfo1_PCSM "EOCM General Information 1 Protected Counter Sync Message";
BA_ "SignalLongName" SG_ 528 FIMRIMABP_MAC "EOCM General Information 1 Protected : MAC";
BA_ "SignalLongName" SG_ 528 FIMRIMABP_FCnt "EOCM General Information 1 Protected : Freshness Counter";
BA_ "SignalLongName" SG_ 528 FIMRIMABP_BrkgCtlAccelAuth "EOCM General Information 1 Protected : Rear Impact Mitigation Autonomous Braking Control Acceleration Authenticated";
BA_ "SignalLongName" SG_ 528 FIMRIMABP_BrkgLongAccelReqAuth "EOCM General Information 1 Protected : Front Impact Mitigation Collision Imminent Steering Autonomous Braking Longitudinal Acceleration Request Authenticated";
BA_ "SignalType" SG_ 528 FIMRIMABP_FIMCISAutBrkRqTypAuth "ENM";
BA_ "SignalLongName" SG_ 528 FIMRIMABP_FIMCISAutBrkRqTypAuth "EOCM General Information 1 Protected : Front Impact Mitigation Collision Imminent Steering Autonomous Brake Request Type Authenticated";
BA_ "SignalType" SG_ 528 FIMRIMABP_BrkgReqAuth "ENM";
BA_ "SignalLongName" SG_ 528 FIMRIMABP_BrkgReqAuth "EOCM General Information 1 Protected : Rear Impact Mitigation Autonomous Brake Braking Request Authenticated";
BA_ "SignalLongName" SG_ 528 RIMATRP_TrqRqstAuth "EOCM General Information 1 Protected : RIM Axle Torque Request Authenticated";
BA_ "SignalType" SG_ 528 RIMATRP_TrqRqstActAuth "ENM";
BA_ "SignalLongName" SG_ 528 RIMATRP_TrqRqstActAuth "EOCM General Information 1 Protected : RIM Axle Torque Request Active Authenticated";
BA_ "SignalType" SG_ 528 FIMRIMABP_ReqActvAuth "ENM";
BA_ "SignalLongName" SG_ 528 FIMRIMABP_ReqActvAuth "EOCM General Information 1 Protected : Front Impact Mitigation Collision Imminent Steering Autonomous Brake Request Active Authenticated";
BA_ "SignalType" SG_ 528 FIMRIMABP_RIMAutoBrkgReqTypAuth "ENM";
BA_ "SignalLongName" SG_ 528 FIMRIMABP_RIMAutoBrkgReqTypAuth "EOCM General Information 1 Protected : Rear Impact Mitigation Autonomous Brake Request Type Authenticated";
BA_ "SignalLongName" SG_ 528 EOCMGI1P_Filler "EOCM General Information 1 Protected : Filler";
BA_ "SignalLongName" SG_ 528 FIMRIMABP_ARC "EOCM General Information 1 Protected : Alive Rolling Count";
BA_ "SignalLongName" SG_ 1401 EOCMGnrlInfo2_PCSM "EOCM General Information 2 Protected Counter Sync Message";
BA_ "SignalLongName" SG_ 613 EOCMGI2P_MAC "EOCM General Information 2 Protected : MAC";
BA_ "SignalLongName" SG_ 613 EOCMGI2P_FCnt "EOCM General Information 2 Protected : Freshness Counter";
BA_ "SignalLongName" SG_ 613 EOCMGI2P_OSTmSyncMstrClckAuth "EOCM General Information 2 Protected : Object Sensor Time Sync Master Clock Authenticated";
BA_ "SignalType" SG_ 2147745797 EOCM_CAN8_ClscCANHrtBtActv "ENM";
BA_ "SignalLongName" SG_ 2147745797 EOCM_CAN8_ClscCANHrtBtActv "EOCM CAN 8 Classic CAN Heart Beat Active";
BA_ "SignalType" SG_ 2147745798 EOCM_HCP1_CAN8_ClscCANHrtBtActv "ENM";
BA_ "SignalLongName" SG_ 2147745798 EOCM_HCP1_CAN8_ClscCANHrtBtActv "EOCM_HCP1 CAN 8 Classic CAN Heart Beat Active";
BA_ "SignalType" SG_ 2147745808 EOCM_HCP2_CAN8_ClscCANHrtBtActv "ENM";
BA_ "SignalLongName" SG_ 2147745808 EOCM_HCP2_CAN8_ClscCANHrtBtActv "EOCM_HCP2 CAN 8 Classic CAN Heart Beat Active";
BA_ "SignalType" SG_ 2147745809 FCM_LC_CAN8_ClscCANHrtBtActv "ENM";
BA_ "SignalLongName" SG_ 2147745809 FCM_LC_CAN8_ClscCANHrtBtActv "FCM_LC CAN 8 Classic CAN Heart Beat Active";
BA_ "SignalLongName" SG_ 658 FCODP_BrstGrp1_PCSM "Front Camera Object Detection and Processing Burst 1 Protected Counter Sync Message";
BA_ "SignalLongName" SG_ 238 FCODPB11P_FVVOTk10PoI4LgPsAuth "Front Camera Object Detection and Processing Burst 11 Protected : Forward Vision Vehicle Object Track 10 Point of Interest 4th Longitudinal Position Authenticated";
BA_ "SignalLongName" SG_ 238 FCODPB11P_BrstID "Front Camera Object Detection and Processing Burst 11 Protected : Burst ID";
BA_ "SignalLongName" SG_ 238 FCODPB11P_FVVOTk10PoI4LPsAuth "Front Camera Object Detection and Processing Burst 11 Protected : Forward Vision Vehicle Object Track 10 Point of Interest 4th Lateral Position Authenticated";
BA_ "SignalType" SG_ 238 FCODPB11P_FVVOTk10PoI4PsVisAuth "ENM";
BA_ "SignalLongName" SG_ 238 FCODPB11P_FVVOTk10PoI4PsVisAuth "Front Camera Object Detection and Processing Burst 11 Protected : Forward Vision Vehicle Object Track 10 Point of Interest 4th Position Visibility Authenticated";
BA_ "SignalLongName" SG_ 238 FCODPB11P_FVVOTk1PoI4LgPsAuth "Front Camera Object Detection and Processing Burst 11 Protected : Forward Vision Vehicle Object Track 1 Point of Interest 4th Longitudinal Position Authenticated";
BA_ "SignalLongName" SG_ 238 FCODPB11P_FVVOTk1PoI4LPsAuth "Front Camera Object Detection and Processing Burst 11 Protected : Forward Vision Vehicle Object Track 1 Point of Interest 4th Lateral Position Authenticated";
BA_ "SignalType" SG_ 238 FCODPB11P_FVVOTk1PoI4PsVisAuth "ENM";
BA_ "SignalLongName" SG_ 238 FCODPB11P_FVVOTk1PoI4PsVisAuth "Front Camera Object Detection and Processing Burst 11 Protected : Forward Vision Vehicle Object Track 1 Point of Interest 4th Position Visibility Authenticated";
BA_ "SignalLongName" SG_ 238 FCODPB11P_FVVOTk2PoI4LgPsAuth "Front Camera Object Detection and Processing Burst 11 Protected : Forward Vision Vehicle Object Track 2 Point of Interest 4th Longitudinal Position Authenticated";
BA_ "SignalLongName" SG_ 238 FCODPB11P_FVVOTk2PoI4LPsAuth "Front Camera Object Detection and Processing Burst 11 Protected : Forward Vision Vehicle Object Track 2 Point of Interest 4th Lateral Position Authenticated";
BA_ "SignalLongName" SG_ 238 FCODPB11P_FVVOTk3PoI4LgPsAuth "Front Camera Object Detection and Processing Burst 11 Protected : Forward Vision Vehicle Object Track 3 Point of Interest 4th Longitudinal Position Authenticated";
BA_ "SignalType" SG_ 238 FCODPB11P_FVVOTk2PoI4PsVisAuth "ENM";
BA_ "SignalLongName" SG_ 238 FCODPB11P_FVVOTk2PoI4PsVisAuth "Front Camera Object Detection and Processing Burst 11 Protected : Forward Vision Vehicle Object Track 2 Point of Interest 4th Position Visibility Authenticated";
BA_ "SignalLongName" SG_ 238 FCODPB11P_FVVOTk3PoI4LPsAuth "Front Camera Object Detection and Processing Burst 11 Protected : Forward Vision Vehicle Object Track 3 Point of Interest 4th Lateral Position Authenticated";
BA_ "SignalLongName" SG_ 238 FCODPB11P_FVVOTk4PoI4LgPsAuth "Front Camera Object Detection and Processing Burst 11 Protected : Forward Vision Vehicle Object Track 4 Point of Interest 4th Longitudinal Position Authenticated";
BA_ "SignalType" SG_ 238 FCODPB11P_FVVOTk3PoI4PsVisAuth "ENM";
BA_ "SignalLongName" SG_ 238 FCODPB11P_FVVOTk3PoI4PsVisAuth "Front Camera Object Detection and Processing Burst 11 Protected : Forward Vision Vehicle Object Track 3 Point of Interest 4th Position Visibility Authenticated";
BA_ "SignalLongName" SG_ 238 FCODPB11P_FVVOTk4PoI4LPsAuth "Front Camera Object Detection and Processing Burst 11 Protected : Forward Vision Vehicle Object Track 4 Point of Interest 4th Lateral Position Authenticated";
BA_ "SignalLongName" SG_ 238 FCODPB11P_FVVOTk5PoI4LgPsAuth "Front Camera Object Detection and Processing Burst 11 Protected : Forward Vision Vehicle Object Track 5 Point of Interest 4th Longitudinal Position Authenticated";
BA_ "SignalType" SG_ 238 FCODPB11P_FVVOTk4PoI4PsVisAuth "ENM";
BA_ "SignalLongName" SG_ 238 FCODPB11P_FVVOTk4PoI4PsVisAuth "Front Camera Object Detection and Processing Burst 11 Protected : Forward Vision Vehicle Object Track 4 Point of Interest 4th Position Visibility Authenticated";
BA_ "SignalLongName" SG_ 238 FCODPB11P_FVVOTk5PoI4LPsAuth "Front Camera Object Detection and Processing Burst 11 Protected : Forward Vision Vehicle Object Track 5 Point of Interest 4th Lateral Position Authenticated";
BA_ "SignalLongName" SG_ 238 FCODPB11P_FVVOTk6PoI4LgPsAuth "Front Camera Object Detection and Processing Burst 11 Protected : Forward Vision Vehicle Object Track 6 Point of Interest 4th Longitudinal Position Authenticated";
BA_ "SignalType" SG_ 238 FCODPB11P_FVVOTk5PoI4PsVisAuth "ENM";
BA_ "SignalLongName" SG_ 238 FCODPB11P_FVVOTk5PoI4PsVisAuth "Front Camera Object Detection and Processing Burst 11 Protected : Forward Vision Vehicle Object Track 5 Point of Interest 4th Position Visibility Authenticated";
BA_ "SignalLongName" SG_ 238 FCODPB11P_FVVOTk6PoI4LPsAuth "Front Camera Object Detection and Processing Burst 11 Protected : Forward Vision Vehicle Object Track 6 Point of Interest 4th Lateral Position Authenticated";
BA_ "SignalLongName" SG_ 238 FCODPB11P_FVVOTk7PoI4LgPsAuth "Front Camera Object Detection and Processing Burst 11 Protected : Forward Vision Vehicle Object Track 7 Point of Interest 4th Longitudinal Position Authenticated";
BA_ "SignalType" SG_ 238 FCODPB11P_FVVOTk6PoI4PsVisAuth "ENM";
BA_ "SignalLongName" SG_ 238 FCODPB11P_FVVOTk6PoI4PsVisAuth "Front Camera Object Detection and Processing Burst 11 Protected : Forward Vision Vehicle Object Track 6 Point of Interest 4th Position Visibility Authenticated";
BA_ "SignalLongName" SG_ 238 FCODPB11P_FVVOTk7PoI4LPsAuth "Front Camera Object Detection and Processing Burst 11 Protected : Forward Vision Vehicle Object Track 7 Point of Interest 4th Lateral Position Authenticated";
BA_ "SignalLongName" SG_ 238 FCODPB11P_FVVOTk8PoI4LgPsAuth "Front Camera Object Detection and Processing Burst 11 Protected : Forward Vision Vehicle Object Track 8 Point of Interest 4th Longitudinal Position Authenticated";
BA_ "SignalType" SG_ 238 FCODPB11P_FVVOTk7PoI4PsVisAuth "ENM";
BA_ "SignalLongName" SG_ 238 FCODPB11P_FVVOTk7PoI4PsVisAuth "Front Camera Object Detection and Processing Burst 11 Protected : Forward Vision Vehicle Object Track 7 Point of Interest 4th Position Visibility Authenticated";
BA_ "SignalLongName" SG_ 238 FCODPB11P_FVVOTk8PoI4LPsAuth "Front Camera Object Detection and Processing Burst 11 Protected : Forward Vision Vehicle Object Track 8 Point of Interest 4th Lateral Position Authenticated";
BA_ "SignalType" SG_ 238 FCODPB11P_FVVOTk8PoI4PsVisAuth "ENM";
BA_ "SignalLongName" SG_ 238 FCODPB11P_FVVOTk8PoI4PsVisAuth "Front Camera Object Detection and Processing Burst 11 Protected : Forward Vision Vehicle Object Track 8 Point of Interest 4th Position Visibility Authenticated";
BA_ "SignalLongName" SG_ 238 FCODPB11P_FVVOTk9PoI4LgPsAuth "Front Camera Object Detection and Processing Burst 11 Protected : Forward Vision Vehicle Object Track 9 Point of Interest 4th Longitudinal Position Authenticated";
BA_ "SignalLongName" SG_ 238 FCODPB11P_FVVOTk9PoI4LPsAuth "Front Camera Object Detection and Processing Burst 11 Protected : Forward Vision Vehicle Object Track 9 Point of Interest 4th Lateral Position Authenticated";
BA_ "SignalType" SG_ 238 FCODPB11P_FVVOTk9PoI4PsVisAuth "ENM";
BA_ "SignalLongName" SG_ 238 FCODPB11P_FVVOTk9PoI4PsVisAuth "Front Camera Object Detection and Processing Burst 11 Protected : Forward Vision Vehicle Object Track 9 Point of Interest 4th Position Visibility Authenticated";
BA_ "SignalLongName" SG_ 238 FCODPB11P_LnTrPtEndLatDistAuth "Front Camera Object Detection and Processing Burst 11 Protected : Lane Transition Point End Lateral Distance Authenticated";
BA_ "SignalLongName" SG_ 238 FCODPB11P_LnTrPtEndLngDistAuth "Front Camera Object Detection and Processing Burst 11 Protected : Lane Transition Point End Longitudinal Distance Authenticated";
BA_ "SignalLongName" SG_ 238 FCODPB11P_LnTrPtStrtLatDistAuth "Front Camera Object Detection and Processing Burst 11 Protected : Lane Transition Point Start Lateral Distance Authenticated";
BA_ "SignalType" SG_ 238 FCODPB11P_LnTrPtEndTypAuth "ENM";
BA_ "SignalLongName" SG_ 238 FCODPB11P_LnTrPtEndTypAuth "Front Camera Object Detection and Processing Burst 11 Protected : Lane Transition Point End Type Authenticated";
BA_ "SignalLongName" SG_ 238 FCODPB11P_LnTrPtStrtLngDistAuth "Front Camera Object Detection and Processing Burst 11 Protected : Lane Transition Point Start Longitudinal Distance Authenticated";
BA_ "SignalType" SG_ 238 FCODPB11P_LnTrPtStrtTypAuth "ENM";
BA_ "SignalLongName" SG_ 238 FCODPB11P_LnTrPtStrtTypAuth "Front Camera Object Detection and Processing Burst 11 Protected : Lane Transition Point Start Type Authenticated";
BA_ "SignalLongName" SG_ 238 FCODPB11P_RdVertPP10LngDistAuth "Front Camera Object Detection and Processing Burst 11 Protected : Road Vertical Profile Point 10 Longitudinal Distance Authenticated";
BA_ "SignalType" SG_ 238 FCODPB11P_FrwdVsnModeCmdStsAuth "ENM";
BA_ "SignalLongName" SG_ 238 FCODPB11P_FrwdVsnModeCmdStsAuth "Front Camera Object Detection and Processing Burst 11 Protected : Forward Vision Mode Command Status Authenticated";
BA_ "SignalLongName" SG_ 238 FCODPB11P_LnTrPtSyncIdxAuth "Front Camera Object Detection and Processing Burst 11 Protected : Lane Transition Point Sync Index Authenticated";
BA_ "SignalLongName" SG_ 238 FCODPB11P_RdVertPP11LngDistAuth "Front Camera Object Detection and Processing Burst 11 Protected : Road Vertical Profile Point 11 Longitudinal Distance Authenticated";
BA_ "SignalLongName" SG_ 238 FCODPB11P_RdVertPP12LngDistAuth "Front Camera Object Detection and Processing Burst 11 Protected : Road Vertical Profile Point 12 Longitudinal Distance Authenticated";
BA_ "SignalLongName" SG_ 238 FCODPB11P_RdVertPP13LngDistAuth "Front Camera Object Detection and Processing Burst 11 Protected : Road Vertical Profile Point 13 Longitudinal Distance Authenticated";
BA_ "SignalLongName" SG_ 238 FCODPB11P_RdVertPP14LngDistAuth "Front Camera Object Detection and Processing Burst 11 Protected : Road Vertical Profile Point 14 Longitudinal Distance Authenticated";
BA_ "SignalLongName" SG_ 238 FCODPB11P_RdVertPP15LngDistAuth "Front Camera Object Detection and Processing Burst 11 Protected : Road Vertical Profile Point 15 Longitudinal Distance Authenticated";
BA_ "SignalLongName" SG_ 238 FCODPB11P_RdVertPP1LngDistAuth "Front Camera Object Detection and Processing Burst 11 Protected : Road Vertical Profile Point 1 Longitudinal Distance Authenticated";
BA_ "SignalLongName" SG_ 238 FCODPB11P_RdVertPP2LngDistAuth "Front Camera Object Detection and Processing Burst 11 Protected : Road Vertical Profile Point 2 Longitudinal Distance Authenticated";
BA_ "SignalLongName" SG_ 238 FCODPB11P_RdVertPP3LngDistAuth "Front Camera Object Detection and Processing Burst 11 Protected : Road Vertical Profile Point 3 Longitudinal Distance Authenticated";
BA_ "SignalLongName" SG_ 238 FCODPB11P_RdVertPP4LngDistAuth "Front Camera Object Detection and Processing Burst 11 Protected : Road Vertical Profile Point 4 Longitudinal Distance Authenticated";
BA_ "SignalLongName" SG_ 238 FCODPB11P_RdVertPP5LngDistAuth "Front Camera Object Detection and Processing Burst 11 Protected : Road Vertical Profile Point 5 Longitudinal Distance Authenticated";
BA_ "SignalLongName" SG_ 238 FCODPB11P_RdVertPP6LngDistAuth "Front Camera Object Detection and Processing Burst 11 Protected : Road Vertical Profile Point 6 Longitudinal Distance Authenticated";
BA_ "SignalLongName" SG_ 238 FCODPB11P_RdVertPP7LngDistAuth "Front Camera Object Detection and Processing Burst 11 Protected : Road Vertical Profile Point 7 Longitudinal Distance Authenticated";
BA_ "SignalLongName" SG_ 238 FCODPB11P_RdVertPP8LngDistAuth "Front Camera Object Detection and Processing Burst 11 Protected : Road Vertical Profile Point 8 Longitudinal Distance Authenticated";
BA_ "SignalLongName" SG_ 238 FCODPB11P_RdVertPP9LngDistAuth "Front Camera Object Detection and Processing Burst 11 Protected : Road Vertical Profile Point 9 Longitudinal Distance Authenticated";
BA_ "SignalLongName" SG_ 238 FCODPB11P_Filler "Front Camera Object Detection and Processing Burst 11 Protected : Filler";
BA_ "SignalType" SG_ 238 FrwdVsnLnBdryTk11DatIntegCkd "ENM";
BA_ "SignalLongName" SG_ 238 FrwdVsnLnBdryTk11DatIntegCkd "Front Camera Object Detection and Processing Burst 11 Protected : Forward Vision Lane Boundary Track 11 Data Integrity Checked";
BA_ "SignalType" SG_ 238 FCODPB11P_ShldrDtnRtofVehAuth "ENM";
BA_ "SignalLongName" SG_ 238 FCODPB11P_ShldrDtnRtofVehAuth "Front Camera Object Detection and Processing Burst 11 Protected : Shoulder Detection Right of Vehicle Authenticated";
BA_ "SignalType" SG_ 238 FCODPB11P_ShldrDtnLtofVehAuth "ENM";
BA_ "SignalLongName" SG_ 238 FCODPB11P_ShldrDtnLtofVehAuth "Front Camera Object Detection and Processing Burst 11 Protected : Shoulder Detection Left of Vehicle Authenticated";
BA_ "SignalLongName" SG_ 238 FCODPB11P_FillerExtnd "Front Camera Object Detection and Processing Burst 11 Protected : Filler Extended";
BA_ "SignalLongName" SG_ 238 FCODPB11P_FillerExtnd1 "Front Camera Object Detection and Processing Burst 11 Protected : Filler Extended 1";
BA_ "SignalLongName" SG_ 217 FCODPB12P_FVTS1AgeAuth "Front Camera Object Detection and Processing Burst 12 Protected : Forward Vision Traffic Sign 1 Age Authenticated";
BA_ "SignalLongName" SG_ 217 FCODPB12P_BrstID "Front Camera Object Detection and Processing Burst 12 Protected : Burst ID";
BA_ "SignalType" SG_ 217 FCODPB12P_FVTS1PsdbyHstVehAuth "ENM";
BA_ "SignalLongName" SG_ 217 FCODPB12P_FVTS1PsdbyHstVehAuth "Front Camera Object Detection and Processing Burst 12 Protected : Forward Vision Traffic Sign 1 Passed by Host Vehicle Authenticated";
BA_ "SignalType" SG_ 217 FCODPB12P_FVTS1PhysTypAuth "ENM";
BA_ "SignalLongName" SG_ 217 FCODPB12P_FVTS1PhysTypAuth "Front Camera Object Detection and Processing Burst 12 Protected : Forward Vision Traffic Sign 1 Physical Type Authenticated";
BA_ "SignalType" SG_ 217 FCODPB12P_FVTS1MeasVldAuth "ENM";
BA_ "SignalLongName" SG_ 217 FCODPB12P_FVTS1MeasVldAuth "Front Camera Object Detection and Processing Burst 12 Protected : Forward Vision Traffic Sign 1 Measurement Valid Authenticated";
BA_ "SignalType" SG_ 217 FCODPB12P_FVTS1FiltTypAuth "ENM";
BA_ "SignalLongName" SG_ 217 FCODPB12P_FVTS1FiltTypAuth "Front Camera Object Detection and Processing Burst 12 Protected : Forward Vision Traffic Sign 1 Filter Type Authenticated";
BA_ "SignalLongName" SG_ 217 FCODPB12P_FVTS2AgeAuth "Front Camera Object Detection and Processing Burst 12 Protected : Forward Vision Traffic Sign 2 Age Authenticated";
BA_ "SignalType" SG_ 217 FCODPB12P_FVTS1ZnDtdAuth "ENM";
BA_ "SignalLongName" SG_ 217 FCODPB12P_FVTS1ZnDtdAuth "Front Camera Object Detection and Processing Burst 12 Protected : Forward Vision Traffic Sign 1 Zone Detected Authenticated";
BA_ "SignalType" SG_ 217 FCODPB12P_FVTS2ZnDtdAuth "ENM";
BA_ "SignalLongName" SG_ 217 FCODPB12P_FVTS2ZnDtdAuth "Front Camera Object Detection and Processing Burst 12 Protected : Forward Vision Traffic Sign 2 Zone Detected Authenticated";
BA_ "SignalType" SG_ 217 FCODPB12P_FVTS2PsdbyHstVehAuth "ENM";
BA_ "SignalLongName" SG_ 217 FCODPB12P_FVTS2PsdbyHstVehAuth "Front Camera Object Detection and Processing Burst 12 Protected : Forward Vision Traffic Sign 2 Passed by Host Vehicle Authenticated";
BA_ "SignalType" SG_ 217 FCODPB12P_FVTS2PhysTypAuth "ENM";
BA_ "SignalLongName" SG_ 217 FCODPB12P_FVTS2PhysTypAuth "Front Camera Object Detection and Processing Burst 12 Protected : Forward Vision Traffic Sign 2 Physical Type Authenticated";
BA_ "SignalType" SG_ 217 FCODPB12P_FVTS2MeasVldAuth "ENM";
BA_ "SignalLongName" SG_ 217 FCODPB12P_FVTS2MeasVldAuth "Front Camera Object Detection and Processing Burst 12 Protected : Forward Vision Traffic Sign 2 Measurement Valid Authenticated";
BA_ "SignalType" SG_ 217 FCODPB12P_FVTS2FiltTypAuth "ENM";
BA_ "SignalLongName" SG_ 217 FCODPB12P_FVTS2FiltTypAuth "Front Camera Object Detection and Processing Burst 12 Protected : Forward Vision Traffic Sign 2 Filter Type Authenticated";
BA_ "SignalLongName" SG_ 217 FCODPB12P_FVTS3AgeAuth "Front Camera Object Detection and Processing Burst 12 Protected : Forward Vision Traffic Sign 3 Age Authenticated";
BA_ "SignalLongName" SG_ 217 FCODPB12P_FVTS4AgeAuth "Front Camera Object Detection and Processing Burst 12 Protected : Forward Vision Traffic Sign 4 Age Authenticated";
BA_ "SignalType" SG_ 217 FCODPB12P_FVTS3ZnDtdAuth "ENM";
BA_ "SignalLongName" SG_ 217 FCODPB12P_FVTS3ZnDtdAuth "Front Camera Object Detection and Processing Burst 12 Protected : Forward Vision Traffic Sign 3 Zone Detected Authenticated";
BA_ "SignalType" SG_ 217 FCODPB12P_FVTS3PsdbyHstVehAuth "ENM";
BA_ "SignalLongName" SG_ 217 FCODPB12P_FVTS3PsdbyHstVehAuth "Front Camera Object Detection and Processing Burst 12 Protected : Forward Vision Traffic Sign 3 Passed by Host Vehicle Authenticated";
BA_ "SignalType" SG_ 217 FCODPB12P_FVTS3PhysTypAuth "ENM";
BA_ "SignalLongName" SG_ 217 FCODPB12P_FVTS3PhysTypAuth "Front Camera Object Detection and Processing Burst 12 Protected : Forward Vision Traffic Sign 3 Physical Type Authenticated";
BA_ "SignalType" SG_ 217 FCODPB12P_FVTS3MeasVldAuth "ENM";
BA_ "SignalLongName" SG_ 217 FCODPB12P_FVTS3MeasVldAuth "Front Camera Object Detection and Processing Burst 12 Protected : Forward Vision Traffic Sign 3 Measurement Valid Authenticated";
BA_ "SignalType" SG_ 217 FCODPB12P_FVTS3FiltTypAuth "ENM";
BA_ "SignalLongName" SG_ 217 FCODPB12P_FVTS3FiltTypAuth "Front Camera Object Detection and Processing Burst 12 Protected : Forward Vision Traffic Sign 3 Filter Type Authenticated";
BA_ "SignalType" SG_ 217 FCODPB12P_FVTS4FiltTypAuth "ENM";
BA_ "SignalLongName" SG_ 217 FCODPB12P_FVTS4FiltTypAuth "Front Camera Object Detection and Processing Burst 12 Protected : Forward Vision Traffic Sign 4 Filter Type Authenticated";
BA_ "SignalLongName" SG_ 217 FCODPB12P_FVTS5AgeAuth "Front Camera Object Detection and Processing Burst 12 Protected : Forward Vision Traffic Sign 5 Age Authenticated";
BA_ "SignalType" SG_ 217 FCODPB12P_FVTS4ZnDtdAuth "ENM";
BA_ "SignalLongName" SG_ 217 FCODPB12P_FVTS4ZnDtdAuth "Front Camera Object Detection and Processing Burst 12 Protected : Forward Vision Traffic Sign 4 Zone Detected Authenticated";
BA_ "SignalType" SG_ 217 FCODPB12P_FVTS4PsdbyHstVehAuth "ENM";
BA_ "SignalLongName" SG_ 217 FCODPB12P_FVTS4PsdbyHstVehAuth "Front Camera Object Detection and Processing Burst 12 Protected : Forward Vision Traffic Sign 4 Passed by Host Vehicle Authenticated";
BA_ "SignalType" SG_ 217 FCODPB12P_FVTS4PhysTypAuth "ENM";
BA_ "SignalLongName" SG_ 217 FCODPB12P_FVTS4PhysTypAuth "Front Camera Object Detection and Processing Burst 12 Protected : Forward Vision Traffic Sign 4 Physical Type Authenticated";
BA_ "SignalType" SG_ 217 FCODPB12P_FVTS4MeasVldAuth "ENM";
BA_ "SignalLongName" SG_ 217 FCODPB12P_FVTS4MeasVldAuth "Front Camera Object Detection and Processing Burst 12 Protected : Forward Vision Traffic Sign 4 Measurement Valid Authenticated";
BA_ "SignalType" SG_ 217 FCODPB12P_FVTS5FiltTypAuth "ENM";
BA_ "SignalLongName" SG_ 217 FCODPB12P_FVTS5FiltTypAuth "Front Camera Object Detection and Processing Burst 12 Protected : Forward Vision Traffic Sign 5 Filter Type Authenticated";
BA_ "SignalLongName" SG_ 217 FCODPB12P_FVTS6AgeAuth "Front Camera Object Detection and Processing Burst 12 Protected : Forward Vision Traffic Sign 6 Age Authenticated";
BA_ "SignalType" SG_ 217 FCODPB12P_FVTS5ZnDtdAuth "ENM";
BA_ "SignalLongName" SG_ 217 FCODPB12P_FVTS5ZnDtdAuth "Front Camera Object Detection and Processing Burst 12 Protected : Forward Vision Traffic Sign 5 Zone Detected Authenticated";
BA_ "SignalType" SG_ 217 FCODPB12P_FVTS5PsdbyHstVehAuth "ENM";
BA_ "SignalLongName" SG_ 217 FCODPB12P_FVTS5PsdbyHstVehAuth "Front Camera Object Detection and Processing Burst 12 Protected : Forward Vision Traffic Sign 5 Passed by Host Vehicle Authenticated";
BA_ "SignalType" SG_ 217 FCODPB12P_FVTS5PhysTypAuth "ENM";
BA_ "SignalLongName" SG_ 217 FCODPB12P_FVTS5PhysTypAuth "Front Camera Object Detection and Processing Burst 12 Protected : Forward Vision Traffic Sign 5 Physical Type Authenticated";
BA_ "SignalType" SG_ 217 FCODPB12P_FVTS5MeasVldAuth "ENM";
BA_ "SignalLongName" SG_ 217 FCODPB12P_FVTS5MeasVldAuth "Front Camera Object Detection and Processing Burst 12 Protected : Forward Vision Traffic Sign 5 Measurement Valid Authenticated";
BA_ "SignalType" SG_ 217 FCODPB12P_FVTS6MeasVldAuth "ENM";
BA_ "SignalLongName" SG_ 217 FCODPB12P_FVTS6MeasVldAuth "Front Camera Object Detection and Processing Burst 12 Protected : Forward Vision Traffic Sign 6 Measurement Valid Authenticated";
BA_ "SignalType" SG_ 217 FCODPB12P_FVTS6FiltTypAuth "ENM";
BA_ "SignalLongName" SG_ 217 FCODPB12P_FVTS6FiltTypAuth "Front Camera Object Detection and Processing Burst 12 Protected : Forward Vision Traffic Sign 6 Filter Type Authenticated";
BA_ "SignalLongName" SG_ 217 FCODPB12P_RdBnkCrv1CrvAuth "Front Camera Object Detection and Processing Burst 12 Protected : Road Bank Curvature 1 Curvature Authenticated";
BA_ "SignalType" SG_ 217 FCODPB12P_RdBnkCrv1CnfdStsAuth "ENM";
BA_ "SignalLongName" SG_ 217 FCODPB12P_RdBnkCrv1CnfdStsAuth "Front Camera Object Detection and Processing Burst 12 Protected : Road Bank Curvature 1 Confidence Status Authenticated";
BA_ "SignalType" SG_ 217 FCODPB12P_FVTS6ZnDtdAuth "ENM";
BA_ "SignalLongName" SG_ 217 FCODPB12P_FVTS6ZnDtdAuth "Front Camera Object Detection and Processing Burst 12 Protected : Forward Vision Traffic Sign 6 Zone Detected Authenticated";
BA_ "SignalType" SG_ 217 FCODPB12P_FVTS6PsdbyHstVehAuth "ENM";
BA_ "SignalLongName" SG_ 217 FCODPB12P_FVTS6PsdbyHstVehAuth "Front Camera Object Detection and Processing Burst 12 Protected : Forward Vision Traffic Sign 6 Passed by Host Vehicle Authenticated";
BA_ "SignalType" SG_ 217 FCODPB12P_FVTS6PhysTypAuth "ENM";
BA_ "SignalLongName" SG_ 217 FCODPB12P_FVTS6PhysTypAuth "Front Camera Object Detection and Processing Burst 12 Protected : Forward Vision Traffic Sign 6 Physical Type Authenticated";
BA_ "SignalLongName" SG_ 217 FCODPB12P_RdBnkCrv1CrvDrvtAuth "Front Camera Object Detection and Processing Burst 12 Protected : Road Bank Curvature 1 Curvature Derivative Authenticated";
BA_ "SignalLongName" SG_ 217 FCODPB12P_RdBnkCrv1HdgAuth "Front Camera Object Detection and Processing Burst 12 Protected : Road Bank Curvature 1 Heading Authenticated";
BA_ "SignalLongName" SG_ 217 FCODPB12P_RdBnkCrv1LatOfstAuth "Front Camera Object Detection and Processing Burst 12 Protected : Road Bank Curvature 1 Lateral Offset Authenticated";
BA_ "SignalLongName" SG_ 217 FCODPB12P_RdBnkCrv1LngOfstAuth "Front Camera Object Detection and Processing Burst 12 Protected : Road Bank Curvature 1 Longitudinal Offset Authenticated";
BA_ "SignalLongName" SG_ 217 FCODPB12P_RdBnkCrv1PsEndAuth "Front Camera Object Detection and Processing Burst 12 Protected : Road Bank Curvature 1 Position End Authenticated";
BA_ "SignalLongName" SG_ 217 FCODPB12P_RdBnkCrv1PsStrtAuth "Front Camera Object Detection and Processing Burst 12 Protected : Road Bank Curvature 1 Position Start Authenticated";
BA_ "SignalLongName" SG_ 217 FCODPB12P_RdBnkCrv2CrvAuth "Front Camera Object Detection and Processing Burst 12 Protected : Road Bank Curvature 2 Curvature Authenticated";
BA_ "SignalType" SG_ 217 FCODPB12P_RdBnkCrv2CnfdStsAuth "ENM";
BA_ "SignalLongName" SG_ 217 FCODPB12P_RdBnkCrv2CnfdStsAuth "Front Camera Object Detection and Processing Burst 12 Protected : Road Bank Curvature 2 Confidence Status Authenticated";
BA_ "SignalLongName" SG_ 217 FCODPB12P_RdBnkCrv2CrvDrvtAuth "Front Camera Object Detection and Processing Burst 12 Protected : Road Bank Curvature 2 Curvature Derivative Authenticated";
BA_ "SignalLongName" SG_ 217 FCODPB12P_RdBnkCrv2HdgAuth "Front Camera Object Detection and Processing Burst 12 Protected : Road Bank Curvature 2 Heading Authenticated";
BA_ "SignalLongName" SG_ 217 FCODPB12P_RdBnkCrv2LatOfstAuth "Front Camera Object Detection and Processing Burst 12 Protected : Road Bank Curvature 2 Lateral Offset Authenticated";
BA_ "SignalLongName" SG_ 217 FCODPB12P_RdBnkCrv2LngOfstAuth "Front Camera Object Detection and Processing Burst 12 Protected : Road Bank Curvature 2 Longitudinal Offset Authenticated";
BA_ "SignalLongName" SG_ 217 FCODPB12P_RdBnkCrv2PsEndAuth "Front Camera Object Detection and Processing Burst 12 Protected : Road Bank Curvature 2 Position End Authenticated";
BA_ "SignalLongName" SG_ 217 FCODPB12P_RdBnkCrv2PsStrtAuth "Front Camera Object Detection and Processing Burst 12 Protected : Road Bank Curvature 2 Position Start Authenticated";
BA_ "SignalLongName" SG_ 217 FCODPB12P_RdBnkCrv3CrvAuth "Front Camera Object Detection and Processing Burst 12 Protected : Road Bank Curvature 3 Curvature Authenticated";
BA_ "SignalType" SG_ 217 FCODPB12P_RdBnkCrv3CnfdStsAuth "ENM";
BA_ "SignalLongName" SG_ 217 FCODPB12P_RdBnkCrv3CnfdStsAuth "Front Camera Object Detection and Processing Burst 12 Protected : Road Bank Curvature 3 Confidence Status Authenticated";
BA_ "SignalLongName" SG_ 217 FCODPB12P_RdBnkCrv3CrvDrvtAuth "Front Camera Object Detection and Processing Burst 12 Protected : Road Bank Curvature 3 Curvature Derivative Authenticated";
BA_ "SignalLongName" SG_ 217 FCODPB12P_RdBnkCrv3HdgAuth "Front Camera Object Detection and Processing Burst 12 Protected : Road Bank Curvature 3 Heading Authenticated";
BA_ "SignalLongName" SG_ 217 FCODPB12P_RdBnkCrv3LatOfstAuth "Front Camera Object Detection and Processing Burst 12 Protected : Road Bank Curvature 3 Lateral Offset Authenticated";
BA_ "SignalLongName" SG_ 217 FCODPB12P_RdBnkCrv3LngOfstAuth "Front Camera Object Detection and Processing Burst 12 Protected : Road Bank Curvature 3 Longitudinal Offset Authenticated";
BA_ "SignalLongName" SG_ 217 FCODPB12P_RdBnkCrv3PsEndAuth "Front Camera Object Detection and Processing Burst 12 Protected : Road Bank Curvature 3 Position End Authenticated";
BA_ "SignalLongName" SG_ 217 FCODPB12P_RdBnkCrv3PsStrtAuth "Front Camera Object Detection and Processing Burst 12 Protected : Road Bank Curvature 3 Position Start Authenticated";
BA_ "SignalLongName" SG_ 217 FCODPB12P_RdVertPP10ElvtnAuth "Front Camera Object Detection and Processing Burst 12 Protected : Road Vertical Profile Point 10 Elevation Authenticated";
BA_ "SignalLongName" SG_ 217 FCODPB12P_RdVertPP11ElvtnAuth "Front Camera Object Detection and Processing Burst 12 Protected : Road Vertical Profile Point 11 Elevation Authenticated";
BA_ "SignalLongName" SG_ 217 FCODPB12P_RdVertPP12ElvtnAuth "Front Camera Object Detection and Processing Burst 12 Protected : Road Vertical Profile Point 12 Elevation Authenticated";
BA_ "SignalLongName" SG_ 217 FCODPB12P_RdVertPP13ElvtnAuth "Front Camera Object Detection and Processing Burst 12 Protected : Road Vertical Profile Point 13 Elevation Authenticated";
BA_ "SignalLongName" SG_ 217 FCODPB12P_RdVertPP14ElvtnAuth "Front Camera Object Detection and Processing Burst 12 Protected : Road Vertical Profile Point 14 Elevation Authenticated";
BA_ "SignalLongName" SG_ 217 FCODPB12P_RdVertPP15ElvtnAuth "Front Camera Object Detection and Processing Burst 12 Protected : Road Vertical Profile Point 15 Elevation Authenticated";
BA_ "SignalLongName" SG_ 217 FCODPB12P_RdVertPP1ElvtnAuth "Front Camera Object Detection and Processing Burst 12 Protected : Road Vertical Profile Point 1 Elevation Authenticated";
BA_ "SignalLongName" SG_ 217 FCODPB12P_RdVertPP2ElvtnAuth "Front Camera Object Detection and Processing Burst 12 Protected : Road Vertical Profile Point 2 Elevation Authenticated";
BA_ "SignalLongName" SG_ 217 FCODPB12P_RdVertPP3ElvtnAuth "Front Camera Object Detection and Processing Burst 12 Protected : Road Vertical Profile Point 3 Elevation Authenticated";
BA_ "SignalLongName" SG_ 217 FCODPB12P_RdVertPP4ElvtnAuth "Front Camera Object Detection and Processing Burst 12 Protected : Road Vertical Profile Point 4 Elevation Authenticated";
BA_ "SignalLongName" SG_ 217 FCODPB12P_RdVertPP5ElvtnAuth "Front Camera Object Detection and Processing Burst 12 Protected : Road Vertical Profile Point 5 Elevation Authenticated";
BA_ "SignalLongName" SG_ 217 FCODPB12P_RdVertPP6ElvtnAuth "Front Camera Object Detection and Processing Burst 12 Protected : Road Vertical Profile Point 6 Elevation Authenticated";
BA_ "SignalLongName" SG_ 217 FCODPB12P_RdVertPP7ElvtnAuth "Front Camera Object Detection and Processing Burst 12 Protected : Road Vertical Profile Point 7 Elevation Authenticated";
BA_ "SignalLongName" SG_ 217 FCODPB12P_RdVertPP8ElvtnAuth "Front Camera Object Detection and Processing Burst 12 Protected : Road Vertical Profile Point 8 Elevation Authenticated";
BA_ "SignalLongName" SG_ 217 FCODPB12P_RdVertPP9ElvtnAuth "Front Camera Object Detection and Processing Burst 12 Protected : Road Vertical Profile Point 9 Elevation Authenticated";
BA_ "SignalLongName" SG_ 217 FCODPB12P_Filler "Front Camera Object Detection and Processing Burst 12 Protected : Filler";
BA_ "SignalLongName" SG_ 217 FCODPB12P_FillerExtnd "Front Camera Object Detection and Processing Burst 12 Protected : Filler Extended";
BA_ "SignalLongName" SG_ 239 FCODPB13P_FVTS10AgeAuth "Front Camera Object Detection and Processing Burst 13 Protected : Forward Vision Traffic Sign 10 Age Authenticated";
BA_ "SignalLongName" SG_ 239 FCODPB13P_BrstID "Front Camera Object Detection and Processing Burst 13 Protected : Burst ID";
BA_ "SignalType" SG_ 239 FCODPB13P_FVTS10PsdbyHstVehAuth "ENM";
BA_ "SignalLongName" SG_ 239 FCODPB13P_FVTS10PsdbyHstVehAuth "Front Camera Object Detection and Processing Burst 13 Protected : Forward Vision Traffic Sign 10 Passed by Host Vehicle Authenticated";
BA_ "SignalType" SG_ 239 FCODPB13P_FVTS10PhysTypAuth "ENM";
BA_ "SignalLongName" SG_ 239 FCODPB13P_FVTS10PhysTypAuth "Front Camera Object Detection and Processing Burst 13 Protected : Forward Vision Traffic Sign 10 Physical Type Authenticated";
BA_ "SignalType" SG_ 239 FCODPB13P_FVTS10MeasVldAuth "ENM";
BA_ "SignalLongName" SG_ 239 FCODPB13P_FVTS10MeasVldAuth "Front Camera Object Detection and Processing Burst 13 Protected : Forward Vision Traffic Sign 10 Measurement Valid Authenticated";
BA_ "SignalType" SG_ 239 FCODPB13P_FVTS10FiltTypAuth "ENM";
BA_ "SignalLongName" SG_ 239 FCODPB13P_FVTS10FiltTypAuth "Front Camera Object Detection and Processing Burst 13 Protected : Forward Vision Traffic Sign 10 Filter Type Authenticated";
BA_ "SignalLongName" SG_ 239 FCODPB13P_FVTS7AgeAuth "Front Camera Object Detection and Processing Burst 13 Protected : Forward Vision Traffic Sign 7 Age Authenticated";
BA_ "SignalType" SG_ 239 FCODPB13P_FVTS10ZnDtdAuth "ENM";
BA_ "SignalLongName" SG_ 239 FCODPB13P_FVTS10ZnDtdAuth "Front Camera Object Detection and Processing Burst 13 Protected : Forward Vision Traffic Sign 10 Zone Detected Authenticated";
BA_ "SignalType" SG_ 239 FCODPB13P_FVTS7ZnDtdAuth "ENM";
BA_ "SignalLongName" SG_ 239 FCODPB13P_FVTS7ZnDtdAuth "Front Camera Object Detection and Processing Burst 13 Protected : Forward Vision Traffic Sign 7 Zone Detected Authenticated";
BA_ "SignalType" SG_ 239 FCODPB13P_FVTS7PsdbyHstVehAuth "ENM";
BA_ "SignalLongName" SG_ 239 FCODPB13P_FVTS7PsdbyHstVehAuth "Front Camera Object Detection and Processing Burst 13 Protected : Forward Vision Traffic Sign 7 Passed by Host Vehicle Authenticated";
BA_ "SignalType" SG_ 239 FCODPB13P_FVTS7PhysTypAuth "ENM";
BA_ "SignalLongName" SG_ 239 FCODPB13P_FVTS7PhysTypAuth "Front Camera Object Detection and Processing Burst 13 Protected : Forward Vision Traffic Sign 7 Physical Type Authenticated";
BA_ "SignalType" SG_ 239 FCODPB13P_FVTS7MeasVldAuth "ENM";
BA_ "SignalLongName" SG_ 239 FCODPB13P_FVTS7MeasVldAuth "Front Camera Object Detection and Processing Burst 13 Protected : Forward Vision Traffic Sign 7 Measurement Valid Authenticated";
BA_ "SignalType" SG_ 239 FCODPB13P_FVTS7FiltTypAuth "ENM";
BA_ "SignalLongName" SG_ 239 FCODPB13P_FVTS7FiltTypAuth "Front Camera Object Detection and Processing Burst 13 Protected : Forward Vision Traffic Sign 7 Filter Type Authenticated";
BA_ "SignalLongName" SG_ 239 FCODPB13P_FVTS8AgeAuth "Front Camera Object Detection and Processing Burst 13 Protected : Forward Vision Traffic Sign 8 Age Authenticated";
BA_ "SignalLongName" SG_ 239 FCODPB13P_FVTS9AgeAuth "Front Camera Object Detection and Processing Burst 13 Protected : Forward Vision Traffic Sign 9 Age Authenticated";
BA_ "SignalType" SG_ 239 FCODPB13P_FVTS8ZnDtdAuth "ENM";
BA_ "SignalLongName" SG_ 239 FCODPB13P_FVTS8ZnDtdAuth "Front Camera Object Detection and Processing Burst 13 Protected : Forward Vision Traffic Sign 8 Zone Detected Authenticated";
BA_ "SignalType" SG_ 239 FCODPB13P_FVTS8PsdbyHstVehAuth "ENM";
BA_ "SignalLongName" SG_ 239 FCODPB13P_FVTS8PsdbyHstVehAuth "Front Camera Object Detection and Processing Burst 13 Protected : Forward Vision Traffic Sign 8 Passed by Host Vehicle Authenticated";
BA_ "SignalType" SG_ 239 FCODPB13P_FVTS8PhysTypAuth "ENM";
BA_ "SignalLongName" SG_ 239 FCODPB13P_FVTS8PhysTypAuth "Front Camera Object Detection and Processing Burst 13 Protected : Forward Vision Traffic Sign 8 Physical Type Authenticated";
BA_ "SignalType" SG_ 239 FCODPB13P_FVTS8MeasVldAuth "ENM";
BA_ "SignalLongName" SG_ 239 FCODPB13P_FVTS8MeasVldAuth "Front Camera Object Detection and Processing Burst 13 Protected : Forward Vision Traffic Sign 8 Measurement Valid Authenticated";
BA_ "SignalType" SG_ 239 FCODPB13P_FVTS8FiltTypAuth "ENM";
BA_ "SignalLongName" SG_ 239 FCODPB13P_FVTS8FiltTypAuth "Front Camera Object Detection and Processing Burst 13 Protected : Forward Vision Traffic Sign 8 Filter Type Authenticated";
BA_ "SignalType" SG_ 239 FCODPB13P_FVTS9FiltTypAuth "ENM";
BA_ "SignalLongName" SG_ 239 FCODPB13P_FVTS9FiltTypAuth "Front Camera Object Detection and Processing Burst 13 Protected : Forward Vision Traffic Sign 9 Filter Type Authenticated";
BA_ "SignalType" SG_ 239 FCODPB13P_FVTSTk10CnfdStsAuth "ENM";
BA_ "SignalLongName" SG_ 239 FCODPB13P_FVTSTk10CnfdStsAuth "Front Camera Object Detection and Processing Burst 13 Protected : Forward Vision Traffic Sign Track 10 Confidence Status Authenticated";
BA_ "SignalType" SG_ 239 FCODPB13P_FVTS9ZnDtdAuth "ENM";
BA_ "SignalLongName" SG_ 239 FCODPB13P_FVTS9ZnDtdAuth "Front Camera Object Detection and Processing Burst 13 Protected : Forward Vision Traffic Sign 9 Zone Detected Authenticated";
BA_ "SignalType" SG_ 239 FCODPB13P_FVTS9PsdbyHstVehAuth "ENM";
BA_ "SignalLongName" SG_ 239 FCODPB13P_FVTS9PsdbyHstVehAuth "Front Camera Object Detection and Processing Burst 13 Protected : Forward Vision Traffic Sign 9 Passed by Host Vehicle Authenticated";
BA_ "SignalType" SG_ 239 FCODPB13P_FVTS9PhysTypAuth "ENM";
BA_ "SignalLongName" SG_ 239 FCODPB13P_FVTS9PhysTypAuth "Front Camera Object Detection and Processing Burst 13 Protected : Forward Vision Traffic Sign 9 Physical Type Authenticated";
BA_ "SignalType" SG_ 239 FCODPB13P_FVTS9MeasVldAuth "ENM";
BA_ "SignalLongName" SG_ 239 FCODPB13P_FVTS9MeasVldAuth "Front Camera Object Detection and Processing Burst 13 Protected : Forward Vision Traffic Sign 9 Measurement Valid Authenticated";
BA_ "SignalLongName" SG_ 239 FCODPB13P_FVTSTk10LatPsAuth "Front Camera Object Detection and Processing Burst 13 Protected : Forward Vision Traffic Sign Track 10 Lateral Position Authenticated";
BA_ "SignalLongName" SG_ 239 FCODPB13P_FVTSTk10IDAuth "Front Camera Object Detection and Processing Burst 13 Protected : Forward Vision Traffic Sign Track 10 ID Authenticated";
BA_ "SignalLongName" SG_ 239 FCODPB13P_FVTSTk10LngPsAuth "Front Camera Object Detection and Processing Burst 13 Protected : Forward Vision Traffic Sign Track 10 Longitudinal Position Authenticated";
BA_ "SignalType" SG_ 239 FCODPB13P_FVTSTk10SupTypAuth "ENM";
BA_ "SignalLongName" SG_ 239 FCODPB13P_FVTSTk10SupTypAuth "Front Camera Object Detection and Processing Burst 13 Protected : Forward Vision Traffic Sign Track 10 Supplemental Type Authenticated";
BA_ "SignalType" SG_ 239 FCODPB13P_FVTSTk10MeasStsAuth "ENM";
BA_ "SignalLongName" SG_ 239 FCODPB13P_FVTSTk10MeasStsAuth "Front Camera Object Detection and Processing Burst 13 Protected : Forward Vision Traffic Sign Track 10 Measurement Status Authenticated";
BA_ "SignalType" SG_ 239 FCODPB13P_FVTSTk10TypAuth "ENM";
BA_ "SignalLongName" SG_ 239 FCODPB13P_FVTSTk10TypAuth "Front Camera Object Detection and Processing Burst 13 Protected : Forward Vision Traffic Sign Track 10 Type Authenticated";
BA_ "SignalLongName" SG_ 239 FCODPB13P_FVTSTk10VertPsAuth "Front Camera Object Detection and Processing Burst 13 Protected : Forward Vision Traffic Sign Track 10 Vertical Position Authenticated";
BA_ "SignalType" SG_ 239 FCODPB13P_FVTSTk10TypCnfdAuth "ENM";
BA_ "SignalLongName" SG_ 239 FCODPB13P_FVTSTk10TypCnfdAuth "Front Camera Object Detection and Processing Burst 13 Protected : Forward Vision Traffic Sign Track 10 Type Confidence Authenticated";
BA_ "SignalLongName" SG_ 239 FCODPB13P_FVTSTk1IDAuth "Front Camera Object Detection and Processing Burst 13 Protected : Forward Vision Traffic Sign Track 1 ID Authenticated";
BA_ "SignalType" SG_ 239 FCODPB13P_FVTSTk1CnfdStsAuth "ENM";
BA_ "SignalLongName" SG_ 239 FCODPB13P_FVTSTk1CnfdStsAuth "Front Camera Object Detection and Processing Burst 13 Protected : Forward Vision Traffic Sign Track 1 Confidence Status Authenticated";
BA_ "SignalLongName" SG_ 239 FCODPB13P_FVTSTk1LatPsAuth "Front Camera Object Detection and Processing Burst 13 Protected : Forward Vision Traffic Sign Track 1 Lateral Position Authenticated";
BA_ "SignalLongName" SG_ 239 FCODPB13P_FVTSTk1LngPsAuth "Front Camera Object Detection and Processing Burst 13 Protected : Forward Vision Traffic Sign Track 1 Longitudinal Position Authenticated";
BA_ "SignalType" SG_ 239 FCODPB13P_FVTSTk1MeasStsAuth "ENM";
BA_ "SignalLongName" SG_ 239 FCODPB13P_FVTSTk1MeasStsAuth "Front Camera Object Detection and Processing Burst 13 Protected : Forward Vision Traffic Sign Track 1 Measurement Status Authenticated";
BA_ "SignalType" SG_ 239 FCODPB13P_FVTSTk1TypAuth "ENM";
BA_ "SignalLongName" SG_ 239 FCODPB13P_FVTSTk1TypAuth "Front Camera Object Detection and Processing Burst 13 Protected : Forward Vision Traffic Sign Track 1 Type Authenticated";
BA_ "SignalType" SG_ 239 FCODPB13P_FVTSTk1SupTypAuth "ENM";
BA_ "SignalLongName" SG_ 239 FCODPB13P_FVTSTk1SupTypAuth "Front Camera Object Detection and Processing Burst 13 Protected : Forward Vision Traffic Sign Track 1 Supplemental Type Authenticated";
BA_ "SignalType" SG_ 239 FCODPB13P_FVTSTk1TypCnfdAuth "ENM";
BA_ "SignalLongName" SG_ 239 FCODPB13P_FVTSTk1TypCnfdAuth "Front Camera Object Detection and Processing Burst 13 Protected : Forward Vision Traffic Sign Track 1 Type Confidence Authenticated";
BA_ "SignalLongName" SG_ 239 FCODPB13P_FVTSTk1VertPsAuth "Front Camera Object Detection and Processing Burst 13 Protected : Forward Vision Traffic Sign Track 1 Vertical Position Authenticated";
BA_ "SignalLongName" SG_ 239 FCODPB13P_FVTSTk2IDAuth "Front Camera Object Detection and Processing Burst 13 Protected : Forward Vision Traffic Sign Track 2 ID Authenticated";
BA_ "SignalType" SG_ 239 FCODPB13P_FVTSTk2CnfdStsAuth "ENM";
BA_ "SignalLongName" SG_ 239 FCODPB13P_FVTSTk2CnfdStsAuth "Front Camera Object Detection and Processing Burst 13 Protected : Forward Vision Traffic Sign Track 2 Confidence Status Authenticated";
BA_ "SignalLongName" SG_ 239 FCODPB13P_FVTSTk2LatPsAuth "Front Camera Object Detection and Processing Burst 13 Protected : Forward Vision Traffic Sign Track 2 Lateral Position Authenticated";
BA_ "SignalLongName" SG_ 239 FCODPB13P_FVTSTk2LngPsAuth "Front Camera Object Detection and Processing Burst 13 Protected : Forward Vision Traffic Sign Track 2 Longitudinal Position Authenticated";
BA_ "SignalType" SG_ 239 FCODPB13P_FVTSTk2SupTypAuth "ENM";
BA_ "SignalLongName" SG_ 239 FCODPB13P_FVTSTk2SupTypAuth "Front Camera Object Detection and Processing Burst 13 Protected : Forward Vision Traffic Sign Track 2 Supplemental Type Authenticated";
BA_ "SignalType" SG_ 239 FCODPB13P_FVTSTk2MeasStsAuth "ENM";
BA_ "SignalLongName" SG_ 239 FCODPB13P_FVTSTk2MeasStsAuth "Front Camera Object Detection and Processing Burst 13 Protected : Forward Vision Traffic Sign Track 2 Measurement Status Authenticated";
BA_ "SignalType" SG_ 239 FCODPB13P_FVTSTk2TypAuth "ENM";
BA_ "SignalLongName" SG_ 239 FCODPB13P_FVTSTk2TypAuth "Front Camera Object Detection and Processing Burst 13 Protected : Forward Vision Traffic Sign Track 2 Type Authenticated";
BA_ "SignalLongName" SG_ 239 FCODPB13P_FVTSTk2VertPsAuth "Front Camera Object Detection and Processing Burst 13 Protected : Forward Vision Traffic Sign Track 2 Vertical Position Authenticated";
BA_ "SignalType" SG_ 239 FCODPB13P_FVTSTk2TypCnfdAuth "ENM";
BA_ "SignalLongName" SG_ 239 FCODPB13P_FVTSTk2TypCnfdAuth "Front Camera Object Detection and Processing Burst 13 Protected : Forward Vision Traffic Sign Track 2 Type Confidence Authenticated";
BA_ "SignalLongName" SG_ 239 FCODPB13P_FVTSTk3IDAuth "Front Camera Object Detection and Processing Burst 13 Protected : Forward Vision Traffic Sign Track 3 ID Authenticated";
BA_ "SignalType" SG_ 239 FCODPB13P_FVTSTk3CnfdStsAuth "ENM";
BA_ "SignalLongName" SG_ 239 FCODPB13P_FVTSTk3CnfdStsAuth "Front Camera Object Detection and Processing Burst 13 Protected : Forward Vision Traffic Sign Track 3 Confidence Status Authenticated";
BA_ "SignalLongName" SG_ 239 FCODPB13P_FVTSTk3LatPsAuth "Front Camera Object Detection and Processing Burst 13 Protected : Forward Vision Traffic Sign Track 3 Lateral Position Authenticated";
BA_ "SignalLongName" SG_ 239 FCODPB13P_FVTSTk3LngPsAuth "Front Camera Object Detection and Processing Burst 13 Protected : Forward Vision Traffic Sign Track 3 Longitudinal Position Authenticated";
BA_ "SignalType" SG_ 239 FCODPB13P_FVTSTk3SupTypAuth "ENM";
BA_ "SignalLongName" SG_ 239 FCODPB13P_FVTSTk3SupTypAuth "Front Camera Object Detection and Processing Burst 13 Protected : Forward Vision Traffic Sign Track 3 Supplemental Type Authenticated";
BA_ "SignalType" SG_ 239 FCODPB13P_FVTSTk3MeasStsAuth "ENM";
BA_ "SignalLongName" SG_ 239 FCODPB13P_FVTSTk3MeasStsAuth "Front Camera Object Detection and Processing Burst 13 Protected : Forward Vision Traffic Sign Track 3 Measurement Status Authenticated";
BA_ "SignalType" SG_ 239 FCODPB13P_FVTSTk3TypAuth "ENM";
BA_ "SignalLongName" SG_ 239 FCODPB13P_FVTSTk3TypAuth "Front Camera Object Detection and Processing Burst 13 Protected : Forward Vision Traffic Sign Track 3 Type Authenticated";
BA_ "SignalLongName" SG_ 239 FCODPB13P_FVTSTk3VertPsAuth "Front Camera Object Detection and Processing Burst 13 Protected : Forward Vision Traffic Sign Track 3 Vertical Position Authenticated";
BA_ "SignalType" SG_ 239 FCODPB13P_FVTSTk3TypCnfdAuth "ENM";
BA_ "SignalLongName" SG_ 239 FCODPB13P_FVTSTk3TypCnfdAuth "Front Camera Object Detection and Processing Burst 13 Protected : Forward Vision Traffic Sign Track 3 Type Confidence Authenticated";
BA_ "SignalLongName" SG_ 239 FCODPB13P_FVTSTk4IDAuth "Front Camera Object Detection and Processing Burst 13 Protected : Forward Vision Traffic Sign Track 4 ID Authenticated";
BA_ "SignalType" SG_ 239 FCODPB13P_FVTSTk4CnfdStsAuth "ENM";
BA_ "SignalLongName" SG_ 239 FCODPB13P_FVTSTk4CnfdStsAuth "Front Camera Object Detection and Processing Burst 13 Protected : Forward Vision Traffic Sign Track 4 Confidence Status Authenticated";
BA_ "SignalLongName" SG_ 239 FCODPB13P_FVTSTk4LatPsAuth "Front Camera Object Detection and Processing Burst 13 Protected : Forward Vision Traffic Sign Track 4 Lateral Position Authenticated";
BA_ "SignalLongName" SG_ 239 FCODPB13P_FVTSTk4LngPsAuth "Front Camera Object Detection and Processing Burst 13 Protected : Forward Vision Traffic Sign Track 4 Longitudinal Position Authenticated";
BA_ "SignalType" SG_ 239 FCODPB13P_FVTSTk4MeasStsAuth "ENM";
BA_ "SignalLongName" SG_ 239 FCODPB13P_FVTSTk4MeasStsAuth "Front Camera Object Detection and Processing Burst 13 Protected : Forward Vision Traffic Sign Track 4 Measurement Status Authenticated";
BA_ "SignalType" SG_ 239 FCODPB13P_FVTSTk4TypAuth "ENM";
BA_ "SignalLongName" SG_ 239 FCODPB13P_FVTSTk4TypAuth "Front Camera Object Detection and Processing Burst 13 Protected : Forward Vision Traffic Sign Track 4 Type Authenticated";
BA_ "SignalType" SG_ 239 FCODPB13P_FVTSTk4SupTypAuth "ENM";
BA_ "SignalLongName" SG_ 239 FCODPB13P_FVTSTk4SupTypAuth "Front Camera Object Detection and Processing Burst 13 Protected : Forward Vision Traffic Sign Track 4 Supplemental Type Authenticated";
BA_ "SignalLongName" SG_ 239 FCODPB13P_FVTSTk4VertPsAuth "Front Camera Object Detection and Processing Burst 13 Protected : Forward Vision Traffic Sign Track 4 Vertical Position Authenticated";
BA_ "SignalType" SG_ 239 FCODPB13P_FVTSTk4TypCnfdAuth "ENM";
BA_ "SignalLongName" SG_ 239 FCODPB13P_FVTSTk4TypCnfdAuth "Front Camera Object Detection and Processing Burst 13 Protected : Forward Vision Traffic Sign Track 4 Type Confidence Authenticated";
BA_ "SignalType" SG_ 239 FCODPB13P_FVTSTk5CnfdStsAuth "ENM";
BA_ "SignalLongName" SG_ 239 FCODPB13P_FVTSTk5CnfdStsAuth "Front Camera Object Detection and Processing Burst 13 Protected : Forward Vision Traffic Sign Track 5 Confidence Status Authenticated";
BA_ "SignalLongName" SG_ 239 FCODPB13P_FVTSTk5LatPsAuth "Front Camera Object Detection and Processing Burst 13 Protected : Forward Vision Traffic Sign Track 5 Lateral Position Authenticated";
BA_ "SignalLongName" SG_ 239 FCODPB13P_FVTSTk5IDAuth "Front Camera Object Detection and Processing Burst 13 Protected : Forward Vision Traffic Sign Track 5 ID Authenticated";
BA_ "SignalLongName" SG_ 239 FCODPB13P_FVTSTk5LngPsAuth "Front Camera Object Detection and Processing Burst 13 Protected : Forward Vision Traffic Sign Track 5 Longitudinal Position Authenticated";
BA_ "SignalType" SG_ 239 FCODPB13P_FVTSTk5SupTypAuth "ENM";
BA_ "SignalLongName" SG_ 239 FCODPB13P_FVTSTk5SupTypAuth "Front Camera Object Detection and Processing Burst 13 Protected : Forward Vision Traffic Sign Track 5 Supplemental Type Authenticated";
BA_ "SignalType" SG_ 239 FCODPB13P_FVTSTk5MeasStsAuth "ENM";
BA_ "SignalLongName" SG_ 239 FCODPB13P_FVTSTk5MeasStsAuth "Front Camera Object Detection and Processing Burst 13 Protected : Forward Vision Traffic Sign Track 5 Measurement Status Authenticated";
BA_ "SignalType" SG_ 239 FCODPB13P_FVTSTk5TypAuth "ENM";
BA_ "SignalLongName" SG_ 239 FCODPB13P_FVTSTk5TypAuth "Front Camera Object Detection and Processing Burst 13 Protected : Forward Vision Traffic Sign Track 5 Type Authenticated";
BA_ "SignalLongName" SG_ 239 FCODPB13P_FVTSTk5VertPsAuth "Front Camera Object Detection and Processing Burst 13 Protected : Forward Vision Traffic Sign Track 5 Vertical Position Authenticated";
BA_ "SignalType" SG_ 239 FCODPB13P_FVTSTk5TypCnfdAuth "ENM";
BA_ "SignalLongName" SG_ 239 FCODPB13P_FVTSTk5TypCnfdAuth "Front Camera Object Detection and Processing Burst 13 Protected : Forward Vision Traffic Sign Track 5 Type Confidence Authenticated";
BA_ "SignalLongName" SG_ 239 FCODPB13P_FVTSTk6IDAuth "Front Camera Object Detection and Processing Burst 13 Protected : Forward Vision Traffic Sign Track 6 ID Authenticated";
BA_ "SignalType" SG_ 239 FCODPB13P_FVTSTk6CnfdStsAuth "ENM";
BA_ "SignalLongName" SG_ 239 FCODPB13P_FVTSTk6CnfdStsAuth "Front Camera Object Detection and Processing Burst 13 Protected : Forward Vision Traffic Sign Track 6 Confidence Status Authenticated";
BA_ "SignalLongName" SG_ 239 FCODPB13P_FVTSTk6LatPsAuth "Front Camera Object Detection and Processing Burst 13 Protected : Forward Vision Traffic Sign Track 6 Lateral Position Authenticated";
BA_ "SignalLongName" SG_ 239 FCODPB13P_FVTSTk6LngPsAuth "Front Camera Object Detection and Processing Burst 13 Protected : Forward Vision Traffic Sign Track 6 Longitudinal Position Authenticated";
BA_ "SignalType" SG_ 239 FCODPB13P_FVTSTk6SupTypAuth "ENM";
BA_ "SignalLongName" SG_ 239 FCODPB13P_FVTSTk6SupTypAuth "Front Camera Object Detection and Processing Burst 13 Protected : Forward Vision Traffic Sign Track 6 Supplemental Type Authenticated";
BA_ "SignalType" SG_ 239 FCODPB13P_FVTSTk6MeasStsAuth "ENM";
BA_ "SignalLongName" SG_ 239 FCODPB13P_FVTSTk6MeasStsAuth "Front Camera Object Detection and Processing Burst 13 Protected : Forward Vision Traffic Sign Track 6 Measurement Status Authenticated";
BA_ "SignalType" SG_ 239 FCODPB13P_FVTSTk6TypCnfdAuth "ENM";
BA_ "SignalLongName" SG_ 239 FCODPB13P_FVTSTk6TypCnfdAuth "Front Camera Object Detection and Processing Burst 13 Protected : Forward Vision Traffic Sign Track 6 Type Confidence Authenticated";
BA_ "SignalType" SG_ 239 FCODPB13P_FVTSTk6TypAuth "ENM";
BA_ "SignalLongName" SG_ 239 FCODPB13P_FVTSTk6TypAuth "Front Camera Object Detection and Processing Burst 13 Protected : Forward Vision Traffic Sign Track 6 Type Authenticated";
BA_ "SignalLongName" SG_ 239 FCODPB13P_FVTSTk6VertPsAuth "Front Camera Object Detection and Processing Burst 13 Protected : Forward Vision Traffic Sign Track 6 Vertical Position Authenticated";
BA_ "SignalLongName" SG_ 239 FCODPB13P_FVTSTk7IDAuth "Front Camera Object Detection and Processing Burst 13 Protected : Forward Vision Traffic Sign Track 7 ID Authenticated";
BA_ "SignalType" SG_ 239 FCODPB13P_FVTSTk7CnfdStsAuth "ENM";
BA_ "SignalLongName" SG_ 239 FCODPB13P_FVTSTk7CnfdStsAuth "Front Camera Object Detection and Processing Burst 13 Protected : Forward Vision Traffic Sign Track 7 Confidence Status Authenticated";
BA_ "SignalLongName" SG_ 239 FCODPB13P_FVTSTk7LatPsAuth "Front Camera Object Detection and Processing Burst 13 Protected : Forward Vision Traffic Sign Track 7 Lateral Position Authenticated";
BA_ "SignalLongName" SG_ 239 FCODPB13P_FVTSTk7LngPsAuth "Front Camera Object Detection and Processing Burst 13 Protected : Forward Vision Traffic Sign Track 7 Longitudinal Position Authenticated";
BA_ "SignalType" SG_ 239 FCODPB13P_FVTSTk7SupTypAuth "ENM";
BA_ "SignalLongName" SG_ 239 FCODPB13P_FVTSTk7SupTypAuth "Front Camera Object Detection and Processing Burst 13 Protected : Forward Vision Traffic Sign Track 7 Supplemental Type Authenticated";
BA_ "SignalType" SG_ 239 FCODPB13P_FVTSTk7MeasStsAuth "ENM";
BA_ "SignalLongName" SG_ 239 FCODPB13P_FVTSTk7MeasStsAuth "Front Camera Object Detection and Processing Burst 13 Protected : Forward Vision Traffic Sign Track 7 Measurement Status Authenticated";
BA_ "SignalType" SG_ 239 FCODPB13P_FVTSTk7TypAuth "ENM";
BA_ "SignalLongName" SG_ 239 FCODPB13P_FVTSTk7TypAuth "Front Camera Object Detection and Processing Burst 13 Protected : Forward Vision Traffic Sign Track 7 Type Authenticated";
BA_ "SignalLongName" SG_ 239 FCODPB13P_FVTSTk7VertPsAuth "Front Camera Object Detection and Processing Burst 13 Protected : Forward Vision Traffic Sign Track 7 Vertical Position Authenticated";
BA_ "SignalType" SG_ 239 FCODPB13P_FVTSTk7TypCnfdAuth "ENM";
BA_ "SignalLongName" SG_ 239 FCODPB13P_FVTSTk7TypCnfdAuth "Front Camera Object Detection and Processing Burst 13 Protected : Forward Vision Traffic Sign Track 7 Type Confidence Authenticated";
BA_ "SignalLongName" SG_ 239 FCODPB13P_Filler "Front Camera Object Detection and Processing Burst 13 Protected : Filler";
BA_ "SignalLongName" SG_ 216 FCODPB14P_CnstrObj10IDAuth "Front Camera Object Detection and Processing Burst 14 Protected : Construction Object 10 ID Authenticated";
BA_ "SignalType" SG_ 216 FCODPB14P_CnstrObj10CnfdStsAuth "ENM";
BA_ "SignalLongName" SG_ 216 FCODPB14P_CnstrObj10CnfdStsAuth "Front Camera Object Detection and Processing Burst 14 Protected : Construction Object 10 Confidence Status Authenticated";
BA_ "SignalLongName" SG_ 216 FCODPB14P_BrstID "Front Camera Object Detection and Processing Burst 14 Protected : Burst ID";
BA_ "SignalLongName" SG_ 216 FCODPB14P_CnstrObj10LatDistAuth "Front Camera Object Detection and Processing Burst 14 Protected : Construction Object 10 Lateral Distance Authenticated";
BA_ "SignalLongName" SG_ 216 FCODPB14P_CnstrObj11IDAuth "Front Camera Object Detection and Processing Burst 14 Protected : Construction Object 11 ID Authenticated";
BA_ "SignalType" SG_ 216 FCODPB14P_CnstrObj11CnfdStsAuth "ENM";
BA_ "SignalLongName" SG_ 216 FCODPB14P_CnstrObj11CnfdStsAuth "Front Camera Object Detection and Processing Burst 14 Protected : Construction Object 11 Confidence Status Authenticated";
BA_ "SignalType" SG_ 216 FCODPB14P_CnstrObj10TypAuth "ENM";
BA_ "SignalLongName" SG_ 216 FCODPB14P_CnstrObj10TypAuth "Front Camera Object Detection and Processing Burst 14 Protected : Construction Object 10 Type Authenticated";
BA_ "SignalLongName" SG_ 216 FCODPB14P_CnstrObj11LatDistAuth "Front Camera Object Detection and Processing Burst 14 Protected : Construction Object 11 Lateral Distance Authenticated";
BA_ "SignalType" SG_ 216 FCODPB14P_CnstrObj12CnfdStsAuth "ENM";
BA_ "SignalLongName" SG_ 216 FCODPB14P_CnstrObj12CnfdStsAuth "Front Camera Object Detection and Processing Burst 14 Protected : Construction Object 12 Confidence Status Authenticated";
BA_ "SignalType" SG_ 216 FCODPB14P_CnstrObj11TypAuth "ENM";
BA_ "SignalLongName" SG_ 216 FCODPB14P_CnstrObj11TypAuth "Front Camera Object Detection and Processing Burst 14 Protected : Construction Object 11 Type Authenticated";
BA_ "SignalLongName" SG_ 216 FCODPB14P_CnstrObj12LatDistAuth "Front Camera Object Detection and Processing Burst 14 Protected : Construction Object 12 Lateral Distance Authenticated";
BA_ "SignalLongName" SG_ 216 FCODPB14P_CnstrObj12IDAuth "Front Camera Object Detection and Processing Burst 14 Protected : Construction Object 12 ID Authenticated";
BA_ "SignalType" SG_ 216 FCODPB14P_CnstrObj12TypAuth "ENM";
BA_ "SignalLongName" SG_ 216 FCODPB14P_CnstrObj12TypAuth "Front Camera Object Detection and Processing Burst 14 Protected : Construction Object 12 Type Authenticated";
BA_ "SignalLongName" SG_ 216 FCODPB14P_CnstrObj13LatDistAuth "Front Camera Object Detection and Processing Burst 14 Protected : Construction Object 13 Lateral Distance Authenticated";
BA_ "SignalLongName" SG_ 216 FCODPB14P_CnstrObj13IDAuth "Front Camera Object Detection and Processing Burst 14 Protected : Construction Object 13 ID Authenticated";
BA_ "SignalType" SG_ 216 FCODPB14P_CnstrObj13CnfdStsAuth "ENM";
BA_ "SignalLongName" SG_ 216 FCODPB14P_CnstrObj13CnfdStsAuth "Front Camera Object Detection and Processing Burst 14 Protected : Construction Object 13 Confidence Status Authenticated";
BA_ "SignalLongName" SG_ 216 FCODPB14P_CnstrObj14IDAuth "Front Camera Object Detection and Processing Burst 14 Protected : Construction Object 14 ID Authenticated";
BA_ "SignalType" SG_ 216 FCODPB14P_CnstrObj14CnfdStsAuth "ENM";
BA_ "SignalLongName" SG_ 216 FCODPB14P_CnstrObj14CnfdStsAuth "Front Camera Object Detection and Processing Burst 14 Protected : Construction Object 14 Confidence Status Authenticated";
BA_ "SignalType" SG_ 216 FCODPB14P_CnstrObj13TypAuth "ENM";
BA_ "SignalLongName" SG_ 216 FCODPB14P_CnstrObj13TypAuth "Front Camera Object Detection and Processing Burst 14 Protected : Construction Object 13 Type Authenticated";
BA_ "SignalLongName" SG_ 216 FCODPB14P_CnstrObj14LatDistAuth "Front Camera Object Detection and Processing Burst 14 Protected : Construction Object 14 Lateral Distance Authenticated";
BA_ "SignalLongName" SG_ 216 FCODPB14P_CnstrObj15IDAuth "Front Camera Object Detection and Processing Burst 14 Protected : Construction Object 15 ID Authenticated";
BA_ "SignalType" SG_ 216 FCODPB14P_CnstrObj15CnfdStsAuth "ENM";
BA_ "SignalLongName" SG_ 216 FCODPB14P_CnstrObj15CnfdStsAuth "Front Camera Object Detection and Processing Burst 14 Protected : Construction Object 15 Confidence Status Authenticated";
BA_ "SignalType" SG_ 216 FCODPB14P_CnstrObj14TypAuth "ENM";
BA_ "SignalLongName" SG_ 216 FCODPB14P_CnstrObj14TypAuth "Front Camera Object Detection and Processing Burst 14 Protected : Construction Object 14 Type Authenticated";
BA_ "SignalLongName" SG_ 216 FCODPB14P_CnstrObj15LatDistAuth "Front Camera Object Detection and Processing Burst 14 Protected : Construction Object 15 Lateral Distance Authenticated";
BA_ "SignalType" SG_ 216 FCODPB14P_CnstrObj1CnfdStsAuth "ENM";
BA_ "SignalLongName" SG_ 216 FCODPB14P_CnstrObj1CnfdStsAuth "Front Camera Object Detection and Processing Burst 14 Protected : Construction Object 1 Confidence Status Authenticated";
BA_ "SignalType" SG_ 216 FCODPB14P_CnstrObj15TypAuth "ENM";
BA_ "SignalLongName" SG_ 216 FCODPB14P_CnstrObj15TypAuth "Front Camera Object Detection and Processing Burst 14 Protected : Construction Object 15 Type Authenticated";
BA_ "SignalLongName" SG_ 216 FCODPB14P_CnstrObj1LatDistAuth "Front Camera Object Detection and Processing Burst 14 Protected : Construction Object 1 Lateral Distance Authenticated";
BA_ "SignalLongName" SG_ 216 FCODPB14P_CnstrObj1IDAuth "Front Camera Object Detection and Processing Burst 14 Protected : Construction Object 1 ID Authenticated";
BA_ "SignalType" SG_ 216 FCODPB14P_CnstrObj1TypAuth "ENM";
BA_ "SignalLongName" SG_ 216 FCODPB14P_CnstrObj1TypAuth "Front Camera Object Detection and Processing Burst 14 Protected : Construction Object 1 Type Authenticated";
BA_ "SignalLongName" SG_ 216 FCODPB14P_CnstrObj2LatDistAuth "Front Camera Object Detection and Processing Burst 14 Protected : Construction Object 2 Lateral Distance Authenticated";
BA_ "SignalLongName" SG_ 216 FCODPB14P_CnstrObj2IDAuth "Front Camera Object Detection and Processing Burst 14 Protected : Construction Object 2 ID Authenticated";
BA_ "SignalType" SG_ 216 FCODPB14P_CnstrObj2CnfdStsAuth "ENM";
BA_ "SignalLongName" SG_ 216 FCODPB14P_CnstrObj2CnfdStsAuth "Front Camera Object Detection and Processing Burst 14 Protected : Construction Object 2 Confidence Status Authenticated";
BA_ "SignalLongName" SG_ 216 FCODPB14P_CnstrObj3IDAuth "Front Camera Object Detection and Processing Burst 14 Protected : Construction Object 3 ID Authenticated";
BA_ "SignalType" SG_ 216 FCODPB14P_CnstrObj3CnfdStsAuth "ENM";
BA_ "SignalLongName" SG_ 216 FCODPB14P_CnstrObj3CnfdStsAuth "Front Camera Object Detection and Processing Burst 14 Protected : Construction Object 3 Confidence Status Authenticated";
BA_ "SignalType" SG_ 216 FCODPB14P_CnstrObj2TypAuth "ENM";
BA_ "SignalLongName" SG_ 216 FCODPB14P_CnstrObj2TypAuth "Front Camera Object Detection and Processing Burst 14 Protected : Construction Object 2 Type Authenticated";
BA_ "SignalLongName" SG_ 216 FCODPB14P_CnstrObj3LatDistAuth "Front Camera Object Detection and Processing Burst 14 Protected : Construction Object 3 Lateral Distance Authenticated";
BA_ "SignalLongName" SG_ 216 FCODPB14P_CnstrObj4IDAuth "Front Camera Object Detection and Processing Burst 14 Protected : Construction Object 4 ID Authenticated";
BA_ "SignalType" SG_ 216 FCODPB14P_CnstrObj4CnfdStsAuth "ENM";
BA_ "SignalLongName" SG_ 216 FCODPB14P_CnstrObj4CnfdStsAuth "Front Camera Object Detection and Processing Burst 14 Protected : Construction Object 4 Confidence Status Authenticated";
BA_ "SignalType" SG_ 216 FCODPB14P_CnstrObj3TypAuth "ENM";
BA_ "SignalLongName" SG_ 216 FCODPB14P_CnstrObj3TypAuth "Front Camera Object Detection and Processing Burst 14 Protected : Construction Object 3 Type Authenticated";
BA_ "SignalLongName" SG_ 216 FCODPB14P_CnstrObj4LatDistAuth "Front Camera Object Detection and Processing Burst 14 Protected : Construction Object 4 Lateral Distance Authenticated";
BA_ "SignalType" SG_ 216 FCODPB14P_CnstrObj5CnfdStsAuth "ENM";
BA_ "SignalLongName" SG_ 216 FCODPB14P_CnstrObj5CnfdStsAuth "Front Camera Object Detection and Processing Burst 14 Protected : Construction Object 5 Confidence Status Authenticated";
BA_ "SignalType" SG_ 216 FCODPB14P_CnstrObj4TypAuth "ENM";
BA_ "SignalLongName" SG_ 216 FCODPB14P_CnstrObj4TypAuth "Front Camera Object Detection and Processing Burst 14 Protected : Construction Object 4 Type Authenticated";
BA_ "SignalLongName" SG_ 216 FCODPB14P_CnstrObj5LatDistAuth "Front Camera Object Detection and Processing Burst 14 Protected : Construction Object 5 Lateral Distance Authenticated";
BA_ "SignalLongName" SG_ 216 FCODPB14P_CnstrObj5IDAuth "Front Camera Object Detection and Processing Burst 14 Protected : Construction Object 5 ID Authenticated";
BA_ "SignalType" SG_ 216 FCODPB14P_CnstrObj5TypAuth "ENM";
BA_ "SignalLongName" SG_ 216 FCODPB14P_CnstrObj5TypAuth "Front Camera Object Detection and Processing Burst 14 Protected : Construction Object 5 Type Authenticated";
BA_ "SignalLongName" SG_ 216 FCODPB14P_CnstrObj6LatDistAuth "Front Camera Object Detection and Processing Burst 14 Protected : Construction Object 6 Lateral Distance Authenticated";
BA_ "SignalLongName" SG_ 216 FCODPB14P_CnstrObj6IDAuth "Front Camera Object Detection and Processing Burst 14 Protected : Construction Object 6 ID Authenticated";
BA_ "SignalType" SG_ 216 FCODPB14P_CnstrObj6CnfdStsAuth "ENM";
BA_ "SignalLongName" SG_ 216 FCODPB14P_CnstrObj6CnfdStsAuth "Front Camera Object Detection and Processing Burst 14 Protected : Construction Object 6 Confidence Status Authenticated";
BA_ "SignalLongName" SG_ 216 FCODPB14P_CnstrObj7IDAuth "Front Camera Object Detection and Processing Burst 14 Protected : Construction Object 7 ID Authenticated";
BA_ "SignalType" SG_ 216 FCODPB14P_CnstrObj7CnfdStsAuth "ENM";
BA_ "SignalLongName" SG_ 216 FCODPB14P_CnstrObj7CnfdStsAuth "Front Camera Object Detection and Processing Burst 14 Protected : Construction Object 7 Confidence Status Authenticated";
BA_ "SignalType" SG_ 216 FCODPB14P_CnstrObj6TypAuth "ENM";
BA_ "SignalLongName" SG_ 216 FCODPB14P_CnstrObj6TypAuth "Front Camera Object Detection and Processing Burst 14 Protected : Construction Object 6 Type Authenticated";
BA_ "SignalLongName" SG_ 216 FCODPB14P_CnstrObj7LatDistAuth "Front Camera Object Detection and Processing Burst 14 Protected : Construction Object 7 Lateral Distance Authenticated";
BA_ "SignalLongName" SG_ 216 FCODPB14P_CnstrObj8IDAuth "Front Camera Object Detection and Processing Burst 14 Protected : Construction Object 8 ID Authenticated";
BA_ "SignalType" SG_ 216 FCODPB14P_CnstrObj8CnfdStsAuth "ENM";
BA_ "SignalLongName" SG_ 216 FCODPB14P_CnstrObj8CnfdStsAuth "Front Camera Object Detection and Processing Burst 14 Protected : Construction Object 8 Confidence Status Authenticated";
BA_ "SignalType" SG_ 216 FCODPB14P_CnstrObj7TypAuth "ENM";
BA_ "SignalLongName" SG_ 216 FCODPB14P_CnstrObj7TypAuth "Front Camera Object Detection and Processing Burst 14 Protected : Construction Object 7 Type Authenticated";
BA_ "SignalLongName" SG_ 216 FCODPB14P_CnstrObj8LatDistAuth "Front Camera Object Detection and Processing Burst 14 Protected : Construction Object 8 Lateral Distance Authenticated";
BA_ "SignalType" SG_ 216 FCODPB14P_CnstrObj9CnfdStsAuth "ENM";
BA_ "SignalLongName" SG_ 216 FCODPB14P_CnstrObj9CnfdStsAuth "Front Camera Object Detection and Processing Burst 14 Protected : Construction Object 9 Confidence Status Authenticated";
BA_ "SignalType" SG_ 216 FCODPB14P_CnstrObj8TypAuth "ENM";
BA_ "SignalLongName" SG_ 216 FCODPB14P_CnstrObj8TypAuth "Front Camera Object Detection and Processing Burst 14 Protected : Construction Object 8 Type Authenticated";
BA_ "SignalLongName" SG_ 216 FCODPB14P_CnstrObj9LatDistAuth "Front Camera Object Detection and Processing Burst 14 Protected : Construction Object 9 Lateral Distance Authenticated";
BA_ "SignalLongName" SG_ 216 FCODPB14P_CnstrObj9IDAuth "Front Camera Object Detection and Processing Burst 14 Protected : Construction Object 9 ID Authenticated";
BA_ "SignalType" SG_ 216 FCODPB14P_CnstrObj9TypAuth "ENM";
BA_ "SignalLongName" SG_ 216 FCODPB14P_CnstrObj9TypAuth "Front Camera Object Detection and Processing Burst 14 Protected : Construction Object 9 Type Authenticated";
BA_ "SignalLongName" SG_ 216 FCODPB14P_FVTSTk8IDAuth "Front Camera Object Detection and Processing Burst 14 Protected : Forward Vision Traffic Sign Track 8 ID Authenticated";
BA_ "SignalType" SG_ 216 FCODPB14P_FVTSTk8CnfdStsAuth "ENM";
BA_ "SignalLongName" SG_ 216 FCODPB14P_FVTSTk8CnfdStsAuth "Front Camera Object Detection and Processing Burst 14 Protected : Forward Vision Traffic Sign Track 8 Confidence Status Authenticated";
BA_ "SignalLongName" SG_ 216 FCODPB14P_FVTSTk8LatPsAuth "Front Camera Object Detection and Processing Burst 14 Protected : Forward Vision Traffic Sign Track 8 Lateral Position Authenticated";
BA_ "SignalLongName" SG_ 216 FCODPB14P_FVTSTk8LngPsAuth "Front Camera Object Detection and Processing Burst 14 Protected : Forward Vision Traffic Sign Track 8 Longitudinal Position Authenticated";
BA_ "SignalType" SG_ 216 FCODPB14P_FVTSTk8SupTypAuth "ENM";
BA_ "SignalLongName" SG_ 216 FCODPB14P_FVTSTk8SupTypAuth "Front Camera Object Detection and Processing Burst 14 Protected : Forward Vision Traffic Sign Track 8 Supplemental Type Authenticated";
BA_ "SignalType" SG_ 216 FCODPB14P_FVTSTk8MeasStsAuth "ENM";
BA_ "SignalLongName" SG_ 216 FCODPB14P_FVTSTk8MeasStsAuth "Front Camera Object Detection and Processing Burst 14 Protected : Forward Vision Traffic Sign Track 8 Measurement Status Authenticated";
BA_ "SignalType" SG_ 216 FCODPB14P_FVTSTk8TypAuth "ENM";
BA_ "SignalLongName" SG_ 216 FCODPB14P_FVTSTk8TypAuth "Front Camera Object Detection and Processing Burst 14 Protected : Forward Vision Traffic Sign Track 8 Type Authenticated";
BA_ "SignalLongName" SG_ 216 FCODPB14P_FVTSTk8VertPsAuth "Front Camera Object Detection and Processing Burst 14 Protected : Forward Vision Traffic Sign Track 8 Vertical Position Authenticated";
BA_ "SignalType" SG_ 216 FCODPB14P_FVTSTk8TypCnfdAuth "ENM";
BA_ "SignalLongName" SG_ 216 FCODPB14P_FVTSTk8TypCnfdAuth "Front Camera Object Detection and Processing Burst 14 Protected : Forward Vision Traffic Sign Track 8 Type Confidence Authenticated";
BA_ "SignalLongName" SG_ 216 FCODPB14P_FVTSTk9IDAuth "Front Camera Object Detection and Processing Burst 14 Protected : Forward Vision Traffic Sign Track 9 ID Authenticated";
BA_ "SignalType" SG_ 216 FCODPB14P_FVTSTk9CnfdStsAuth "ENM";
BA_ "SignalLongName" SG_ 216 FCODPB14P_FVTSTk9CnfdStsAuth "Front Camera Object Detection and Processing Burst 14 Protected : Forward Vision Traffic Sign Track 9 Confidence Status Authenticated";
BA_ "SignalLongName" SG_ 216 FCODPB14P_FVTSTk9LatPsAuth "Front Camera Object Detection and Processing Burst 14 Protected : Forward Vision Traffic Sign Track 9 Lateral Position Authenticated";
BA_ "SignalLongName" SG_ 216 FCODPB14P_FVTSTk9LngPsAuth "Front Camera Object Detection and Processing Burst 14 Protected : Forward Vision Traffic Sign Track 9 Longitudinal Position Authenticated";
BA_ "SignalType" SG_ 216 FCODPB14P_FVTSTk9SupTypAuth "ENM";
BA_ "SignalLongName" SG_ 216 FCODPB14P_FVTSTk9SupTypAuth "Front Camera Object Detection and Processing Burst 14 Protected : Forward Vision Traffic Sign Track 9 Supplemental Type Authenticated";
BA_ "SignalType" SG_ 216 FCODPB14P_FVTSTk9MeasStsAuth "ENM";
BA_ "SignalLongName" SG_ 216 FCODPB14P_FVTSTk9MeasStsAuth "Front Camera Object Detection and Processing Burst 14 Protected : Forward Vision Traffic Sign Track 9 Measurement Status Authenticated";
BA_ "SignalType" SG_ 216 FCODPB14P_FVTSTk9TypAuth "ENM";
BA_ "SignalLongName" SG_ 216 FCODPB14P_FVTSTk9TypAuth "Front Camera Object Detection and Processing Burst 14 Protected : Forward Vision Traffic Sign Track 9 Type Authenticated";
BA_ "SignalLongName" SG_ 216 FCODPB14P_FVTSTk9VertPsAuth "Front Camera Object Detection and Processing Burst 14 Protected : Forward Vision Traffic Sign Track 9 Vertical Position Authenticated";
BA_ "SignalType" SG_ 216 FCODPB14P_FVTSTk9TypCnfdAuth "ENM";
BA_ "SignalLongName" SG_ 216 FCODPB14P_FVTSTk9TypCnfdAuth "Front Camera Object Detection and Processing Burst 14 Protected : Forward Vision Traffic Sign Track 9 Type Confidence Authenticated";
BA_ "SignalLongName" SG_ 216 FCODPB14P_Filler "Front Camera Object Detection and Processing Burst 14 Protected : Filler";
VAL_ 1434 DTCI_HDLM_CnfrmdDTC 0 "FALSE" 1 "TRUE" ;
VAL_ 1434 DTCI_HDLM_DTCFaultType 0 "Not Supported" 1 "Type A" 2 "Type B" 3 "Type C" ;
VAL_ 1434 DTCI_HDLM_TstNCmpltdOpCyc 0 "FALSE" 1 "TRUE" ;
VAL_ 1434 DTCI_HDLM_TstNCmpltdLstClr 0 "FALSE" 1 "TRUE" ;
VAL_ 1434 DTCI_HDLM_TstFldOpCyc 0 "FALSE" 1 "TRUE" ;
VAL_ 1434 DTCI_HDLM_TstFldLstClr 0 "FALSE" 1 "TRUE" ;
VAL_ 1434 DTCI_HDLM_TstFld 0 "FALSE" 1 "TRUE" ;
VAL_ 1434 DTCI_HDLM_PndngDTC 0 "FALSE" 1 "TRUE" ;
VAL_ 1434 DTCI_HDLM_DTCTriggered 0 "FALSE" 1 "TRUE" ;
VAL_ 1434 DTCI_HDLM_WrnIndTrggrd 0 "FALSE" 1 "TRUE" ;
VAL_ 1434 DTCI_HDLM_WrnIndRqd 0 "FALSE" 1 "TRUE" ;
VAL_ 1435 DTCI_LRR_CnfrmdDTC 0 "FALSE" 1 "TRUE" ;
VAL_ 1435 DTCI_LRR_DTCFaultType 0 "Not Supported" 1 "Type A" 2 "Type B" 3 "Type C" ;
VAL_ 1435 DTCI_LRR_TstNCmpltdOpCyc 0 "FALSE" 1 "TRUE" ;
VAL_ 1435 DTCI_LRR_TstNCmpltdLstClr 0 "FALSE" 1 "TRUE" ;
VAL_ 1435 DTCI_LRR_TstFldOpCyc 0 "FALSE" 1 "TRUE" ;
VAL_ 1435 DTCI_LRR_TstFldLstClr 0 "FALSE" 1 "TRUE" ;
VAL_ 1435 DTCI_LRR_TstFld 0 "FALSE" 1 "TRUE" ;
VAL_ 1435 DTCI_LRR_PndngDTC 0 "FALSE" 1 "TRUE" ;
VAL_ 1435 DTCI_LRR_DTCTriggered 0 "FALSE" 1 "TRUE" ;
VAL_ 1435 DTCI_LRR_WrnIndTrggrd 0 "FALSE" 1 "TRUE" ;
VAL_ 1435 DTCI_LRR_WrnIndRqd 0 "FALSE" 1 "TRUE" ;
VAL_ 1436 DTCI_SRR_LF_CnfrmdDTC 0 "FALSE" 1 "TRUE" ;
VAL_ 1436 DTCI_SRR_LF_DTCFaultType 0 "Not Supported" 1 "Type A" 2 "Type B" 3 "Type C" ;
VAL_ 1436 DTCI_SRR_LF_TstNCmpltdOpCyc 0 "FALSE" 1 "TRUE" ;
VAL_ 1436 DTCI_SRR_LF_TstNCmpltdLstClr 0 "FALSE" 1 "TRUE" ;
VAL_ 1436 DTCI_SRR_LF_TstFldOpCyc 0 "FALSE" 1 "TRUE" ;
VAL_ 1436 DTCI_SRR_LF_TstFldLstClr 0 "FALSE" 1 "TRUE" ;
VAL_ 1436 DTCI_SRR_LF_TstFld 0 "FALSE" 1 "TRUE" ;
VAL_ 1436 DTCI_SRR_LF_PndngDTC 0 "FALSE" 1 "TRUE" ;
VAL_ 1436 DTCI_SRR_LF_DTCTriggered 0 "FALSE" 1 "TRUE" ;
VAL_ 1436 DTCI_SRR_LF_WrnIndTrggrd 0 "FALSE" 1 "TRUE" ;
VAL_ 1436 DTCI_SRR_LF_WrnIndRqd 0 "FALSE" 1 "TRUE" ;
VAL_ 1437 DTCI_SRR_LR_CR_CnfrmdDTC 0 "FALSE" 1 "TRUE" ;
VAL_ 1437 DTCI_SRR_LR_CR_DTCFaultType 0 "Not Supported" 1 "Type A" 2 "Type B" 3 "Type C" ;
VAL_ 1437 DTCI_SRR_LR_CR_TstNCmpltdOpCyc 0 "FALSE" 1 "TRUE" ;
VAL_ 1437 DTCI_SRR_LR_CR_TstNCmpltdLstClr 0 "FALSE" 1 "TRUE" ;
VAL_ 1437 DTCI_SRR_LR_CR_TstFldOpCyc 0 "FALSE" 1 "TRUE" ;
VAL_ 1437 DTCI_SRR_LR_CR_TstFldLstClr 0 "FALSE" 1 "TRUE" ;
VAL_ 1437 DTCI_SRR_LR_CR_TstFld 0 "FALSE" 1 "TRUE" ;
VAL_ 1437 DTCI_SRR_LR_CR_PndngDTC 0 "FALSE" 1 "TRUE" ;
VAL_ 1437 DTCI_SRR_LR_CR_DTCTriggered 0 "FALSE" 1 "TRUE" ;
VAL_ 1437 DTCI_SRR_LR_CR_WrnIndTrggrd 0 "FALSE" 1 "TRUE" ;
VAL_ 1437 DTCI_SRR_LR_CR_WrnIndRqd 0 "FALSE" 1 "TRUE" ;
VAL_ 1438 DTCI_SRR_RF_CnfrmdDTC 0 "FALSE" 1 "TRUE" ;
VAL_ 1438 DTCI_SRR_RF_DTCFaultType 0 "Not Supported" 1 "Type A" 2 "Type B" 3 "Type C" ;
VAL_ 1438 DTCI_SRR_RF_TstNCmpltdOpCyc 0 "FALSE" 1 "TRUE" ;
VAL_ 1438 DTCI_SRR_RF_TstNCmpltdLstClr 0 "FALSE" 1 "TRUE" ;
VAL_ 1438 DTCI_SRR_RF_TstFldOpCyc 0 "FALSE" 1 "TRUE" ;
VAL_ 1438 DTCI_SRR_RF_TstFldLstClr 0 "FALSE" 1 "TRUE" ;
VAL_ 1438 DTCI_SRR_RF_TstFld 0 "FALSE" 1 "TRUE" ;
VAL_ 1438 DTCI_SRR_RF_PndngDTC 0 "FALSE" 1 "TRUE" ;
VAL_ 1438 DTCI_SRR_RF_DTCTriggered 0 "FALSE" 1 "TRUE" ;
VAL_ 1438 DTCI_SRR_RF_WrnIndTrggrd 0 "FALSE" 1 "TRUE" ;
VAL_ 1438 DTCI_SRR_RF_WrnIndRqd 0 "FALSE" 1 "TRUE" ;
VAL_ 1439 DTCI_SRR_RR_CnfrmdDTC 0 "FALSE" 1 "TRUE" ;
VAL_ 1439 DTCI_SRR_RR_DTCFaultType 0 "Not Supported" 1 "Type A" 2 "Type B" 3 "Type C" ;
VAL_ 1439 DTCI_SRR_RR_TstNCmpltdOpCyc 0 "FALSE" 1 "TRUE" ;
VAL_ 1439 DTCI_SRR_RR_TstNCmpltdLstClr 0 "FALSE" 1 "TRUE" ;
VAL_ 1439 DTCI_SRR_RR_TstFldOpCyc 0 "FALSE" 1 "TRUE" ;
VAL_ 1439 DTCI_SRR_RR_TstFldLstClr 0 "FALSE" 1 "TRUE" ;
VAL_ 1439 DTCI_SRR_RR_TstFld 0 "FALSE" 1 "TRUE" ;
VAL_ 1439 DTCI_SRR_RR_PndngDTC 0 "FALSE" 1 "TRUE" ;
VAL_ 1439 DTCI_SRR_RR_DTCTriggered 0 "FALSE" 1 "TRUE" ;
VAL_ 1439 DTCI_SRR_RR_WrnIndTrggrd 0 "FALSE" 1 "TRUE" ;
VAL_ 1439 DTCI_SRR_RR_WrnIndRqd 0 "FALSE" 1 "TRUE" ;
VAL_ 1440 DTCI_SRR_SLR_CnfrmdDTC 0 "FALSE" 1 "TRUE" ;
VAL_ 1440 DTCI_SRR_SLR_DTCFaultType 0 "Not Supported" 1 "Type A" 2 "Type B" 3 "Type C" ;
VAL_ 1440 DTCI_SRR_SLR_TstNCmpltdOpCyc 0 "FALSE" 1 "TRUE" ;
VAL_ 1440 DTCI_SRR_SLR_TstNCmpltdLstClr 0 "FALSE" 1 "TRUE" ;
VAL_ 1440 DTCI_SRR_SLR_TstFldOpCyc 0 "FALSE" 1 "TRUE" ;
VAL_ 1440 DTCI_SRR_SLR_TstFldLstClr 0 "FALSE" 1 "TRUE" ;
VAL_ 1440 DTCI_SRR_SLR_TstFld 0 "FALSE" 1 "TRUE" ;
VAL_ 1440 DTCI_SRR_SLR_PndngDTC 0 "FALSE" 1 "TRUE" ;
VAL_ 1440 DTCI_SRR_SLR_DTCTriggered 0 "FALSE" 1 "TRUE" ;
VAL_ 1440 DTCI_SRR_SLR_WrnIndTrggrd 0 "FALSE" 1 "TRUE" ;
VAL_ 1440 DTCI_SRR_SLR_WrnIndRqd 0 "FALSE" 1 "TRUE" ;
VAL_ 1441 DTCI_SRR_SRR_CnfrmdDTC 0 "FALSE" 1 "TRUE" ;
VAL_ 1441 DTCI_SRR_SRR_DTCFaultType 0 "Not Supported" 1 "Type A" 2 "Type B" 3 "Type C" ;
VAL_ 1441 DTCI_SRR_SRR_TstNCmpltdOpCyc 0 "FALSE" 1 "TRUE" ;
VAL_ 1441 DTCI_SRR_SRR_TstNCmpltdLstClr 0 "FALSE" 1 "TRUE" ;
VAL_ 1441 DTCI_SRR_SRR_TstFldOpCyc 0 "FALSE" 1 "TRUE" ;
VAL_ 1441 DTCI_SRR_SRR_TstFldLstClr 0 "FALSE" 1 "TRUE" ;
VAL_ 1441 DTCI_SRR_SRR_TstFld 0 "FALSE" 1 "TRUE" ;
VAL_ 1441 DTCI_SRR_SRR_PndngDTC 0 "FALSE" 1 "TRUE" ;
VAL_ 1441 DTCI_SRR_SRR_DTCTriggered 0 "FALSE" 1 "TRUE" ;
VAL_ 1441 DTCI_SRR_SRR_WrnIndTrggrd 0 "FALSE" 1 "TRUE" ;
VAL_ 1441 DTCI_SRR_SRR_WrnIndRqd 0 "FALSE" 1 "TRUE" ;
VAL_ 1465 DTCI_UPM_CnfrmdDTC 0 "FALSE" 1 "TRUE" ;
VAL_ 1465 DTCI_UPM_DTCFaultType 0 "Not Supported" 1 "Type A" 2 "Type B" 3 "Type C" ;
VAL_ 1465 DTCI_UPM_TstNCmpltdOpCyc 0 "FALSE" 1 "TRUE" ;
VAL_ 1465 DTCI_UPM_TstNCmpltdLstClr 0 "FALSE" 1 "TRUE" ;
VAL_ 1465 DTCI_UPM_TstFldOpCyc 0 "FALSE" 1 "TRUE" ;
VAL_ 1465 DTCI_UPM_TstFldLstClr 0 "FALSE" 1 "TRUE" ;
VAL_ 1465 DTCI_UPM_TstFld 0 "FALSE" 1 "TRUE" ;
VAL_ 1465 DTCI_UPM_PndngDTC 0 "FALSE" 1 "TRUE" ;
VAL_ 1465 DTCI_UPM_DTCTriggered 0 "FALSE" 1 "TRUE" ;
VAL_ 1465 DTCI_UPM_WrnIndTrggrd 0 "FALSE" 1 "TRUE" ;
VAL_ 1465 DTCI_UPM_WrnIndRqd 0 "FALSE" 1 "TRUE" ;
VAL_ 928 EASSI_StrtStpSt 0 "Engine Off" 1 "Engine Running" 2 "Engine Starting" 3 "Engine Stopping" ;
VAL_ 1407 ACCAutoStSpStat 0 "No_Set_Speed_Change" 1 "Proposed_Speed_Limit_Change" 2 "Accepted_Speed_Limit_Change" 3 "Declined_Speed_Limit_Change" ;
VAL_ 705 EPBSP_ElecPrkBrkApplStsAuth 0 "Unknown" 1 "Applied" 2 "Released" 3 "Dynamic Apply" 4 "In-Progress" ;
VAL_ 528 FIMRIMABP_FIMCISAutBrkRqTypAuth 0 "None" 1 "Brake to Commanded Decel" 2 "Hold" ;
VAL_ 528 FIMRIMABP_BrkgReqAuth 0 "FALSE" 1 "TRUE" ;
VAL_ 528 RIMATRP_TrqRqstActAuth 0 "FALSE" 1 "TRUE" ;
VAL_ 528 FIMRIMABP_ReqActvAuth 0 "FALSE" 1 "TRUE" ;
VAL_ 528 FIMRIMABP_RIMAutoBrkgReqTypAuth 0 "None" 1 "Hold" ;
VAL_ 2147745797 EOCM_CAN8_ClscCANHrtBtActv 0 "FALSE" 1 "TRUE" ;
VAL_ 2147745798 EOCM_HCP1_CAN8_ClscCANHrtBtActv 0 "FALSE" 1 "TRUE" ;
VAL_ 2147745808 EOCM_HCP2_CAN8_ClscCANHrtBtActv 0 "FALSE" 1 "TRUE" ;
VAL_ 2147745809 FCM_LC_CAN8_ClscCANHrtBtActv 0 "FALSE" 1 "TRUE" ;
VAL_ 238 FCODPB11P_FVVOTk10PoI4PsVisAuth 0 "Unknown" 1 "Visible" 2 "Projected" ;
VAL_ 238 FCODPB11P_FVVOTk1PoI4PsVisAuth 0 "Unknown" 1 "Visible" 2 "Projected" ;
VAL_ 238 FCODPB11P_FVVOTk2PoI4PsVisAuth 0 "Unknown" 1 "Visible" 2 "Projected" ;
VAL_ 238 FCODPB11P_FVVOTk3PoI4PsVisAuth 0 "Unknown" 1 "Visible" 2 "Projected" ;
VAL_ 238 FCODPB11P_FVVOTk4PoI4PsVisAuth 0 "Unknown" 1 "Visible" 2 "Projected" ;
VAL_ 238 FCODPB11P_FVVOTk5PoI4PsVisAuth 0 "Unknown" 1 "Visible" 2 "Projected" ;
VAL_ 238 FCODPB11P_FVVOTk6PoI4PsVisAuth 0 "Unknown" 1 "Visible" 2 "Projected" ;
VAL_ 238 FCODPB11P_FVVOTk7PoI4PsVisAuth 0 "Unknown" 1 "Visible" 2 "Projected" ;
VAL_ 238 FCODPB11P_FVVOTk8PoI4PsVisAuth 0 "Unknown" 1 "Visible" 2 "Projected" ;
VAL_ 238 FCODPB11P_FVVOTk9PoI4PsVisAuth 0 "Unknown" 1 "Visible" 2 "Projected" ;
VAL_ 238 FCODPB11P_LnTrPtEndTypAuth 0 "Unknown" 1 "Merge End" 2 "Split End" ;
VAL_ 238 FCODPB11P_LnTrPtStrtTypAuth 0 "Unknown" 1 "Merge Start" 2 "Split Start" ;
VAL_ 238 FCODPB11P_FrwdVsnModeCmdStsAuth 0 "Not Reporting Object Data" 1 "Reporting Object Data" ;
VAL_ 238 FrwdVsnLnBdryTk11DatIntegCkd 0 "Unknown" 1 "Pass" 2 "Fail" ;
VAL_ 238 FCODPB11P_ShldrDtnRtofVehAuth 0 "Shoulder Not Detected" 1 "Shoulder Detected" 2 "Reserved" 3 "Not Valid" ;
VAL_ 238 FCODPB11P_ShldrDtnLtofVehAuth 0 "Shoulder Not Detected" 1 "Shoulder Detected" 2 "Reserved" 3 "Not Valid" ;
VAL_ 217 FCODPB12P_FVTS1PsdbyHstVehAuth 0 "FALSE" 1 "TRUE" ;
VAL_ 217 FCODPB12P_FVTS1PhysTypAuth 0 "Static" 1 "Variable" 2 "Temporary" ;
VAL_ 217 FCODPB12P_FVTS1MeasVldAuth 0 "FALSE" 1 "TRUE" ;
VAL_ 217 FCODPB12P_FVTS1FiltTypAuth 0 "Not Filtered" 1 "Irrelevant To Host Driver" 2 "On Vehicle/Truck" 3 "Embedded" ;
VAL_ 217 FCODPB12P_FVTS1ZnDtdAuth 0 "FALSE" 1 "TRUE" ;
VAL_ 217 FCODPB12P_FVTS2ZnDtdAuth 0 "FALSE" 1 "TRUE" ;
VAL_ 217 FCODPB12P_FVTS2PsdbyHstVehAuth 0 "FALSE" 1 "TRUE" ;
VAL_ 217 FCODPB12P_FVTS2PhysTypAuth 0 "Static" 1 "Variable" 2 "Temporary" ;
VAL_ 217 FCODPB12P_FVTS2MeasVldAuth 0 "FALSE" 1 "TRUE" ;
VAL_ 217 FCODPB12P_FVTS2FiltTypAuth 0 "Not Filtered" 1 "Irrelevant To Host Driver" 2 "On Vehicle/Truck" 3 "Embedded" ;
VAL_ 217 FCODPB12P_FVTS3ZnDtdAuth 0 "FALSE" 1 "TRUE" ;
VAL_ 217 FCODPB12P_FVTS3PsdbyHstVehAuth 0 "FALSE" 1 "TRUE" ;
VAL_ 217 FCODPB12P_FVTS3PhysTypAuth 0 "Static" 1 "Variable" 2 "Temporary" ;
VAL_ 217 FCODPB12P_FVTS3MeasVldAuth 0 "FALSE" 1 "TRUE" ;
VAL_ 217 FCODPB12P_FVTS3FiltTypAuth 0 "Not Filtered" 1 "Irrelevant To Host Driver" 2 "On Vehicle/Truck" 3 "Embedded" ;
VAL_ 217 FCODPB12P_FVTS4FiltTypAuth 0 "Not Filtered" 1 "Irrelevant To Host Driver" 2 "On Vehicle/Truck" 3 "Embedded" ;
VAL_ 217 FCODPB12P_FVTS4ZnDtdAuth 0 "FALSE" 1 "TRUE" ;
VAL_ 217 FCODPB12P_FVTS4PsdbyHstVehAuth 0 "FALSE" 1 "TRUE" ;
VAL_ 217 FCODPB12P_FVTS4PhysTypAuth 0 "Static" 1 "Variable" 2 "Temporary" ;
VAL_ 217 FCODPB12P_FVTS4MeasVldAuth 0 "FALSE" 1 "TRUE" ;
VAL_ 217 FCODPB12P_FVTS5FiltTypAuth 0 "Not Filtered" 1 "Irrelevant To Host Driver" 2 "On Vehicle/Truck" 3 "Embedded" ;
VAL_ 217 FCODPB12P_FVTS5ZnDtdAuth 0 "FALSE" 1 "TRUE" ;
VAL_ 217 FCODPB12P_FVTS5PsdbyHstVehAuth 0 "FALSE" 1 "TRUE" ;
VAL_ 217 FCODPB12P_FVTS5PhysTypAuth 0 "Static" 1 "Variable" 2 "Temporary" ;
VAL_ 217 FCODPB12P_FVTS5MeasVldAuth 0 "FALSE" 1 "TRUE" ;
VAL_ 217 FCODPB12P_FVTS6MeasVldAuth 0 "FALSE" 1 "TRUE" ;
VAL_ 217 FCODPB12P_FVTS6FiltTypAuth 0 "Not Filtered" 1 "Irrelevant To Host Driver" 2 "On Vehicle/Truck" 3 "Embedded" ;
VAL_ 217 FCODPB12P_RdBnkCrv1CnfdStsAuth 0 "Highly Speculative" 1 "Speculative" 2 "Confident" 3 "Highly Confident" ;
VAL_ 217 FCODPB12P_FVTS6ZnDtdAuth 0 "FALSE" 1 "TRUE" ;
VAL_ 217 FCODPB12P_FVTS6PsdbyHstVehAuth 0 "FALSE" 1 "TRUE" ;
VAL_ 217 FCODPB12P_FVTS6PhysTypAuth 0 "Static" 1 "Variable" 2 "Temporary" ;
VAL_ 217 FCODPB12P_RdBnkCrv2CnfdStsAuth 0 "Highly Speculative" 1 "Speculative" 2 "Confident" 3 "Highly Confident" ;
VAL_ 217 FCODPB12P_RdBnkCrv3CnfdStsAuth 0 "Highly Speculative" 1 "Speculative" 2 "Confident" 3 "Highly Confident" ;
VAL_ 239 FCODPB13P_FVTS10PsdbyHstVehAuth 0 "FALSE" 1 "TRUE" ;
VAL_ 239 FCODPB13P_FVTS10PhysTypAuth 0 "Static" 1 "Variable" 2 "Temporary" ;
VAL_ 239 FCODPB13P_FVTS10MeasVldAuth 0 "FALSE" 1 "TRUE" ;
VAL_ 239 FCODPB13P_FVTS10FiltTypAuth 0 "Not Filtered" 1 "Irrelevant To Host Driver" 2 "On Vehicle/Truck" 3 "Embedded" ;
VAL_ 239 FCODPB13P_FVTS10ZnDtdAuth 0 "FALSE" 1 "TRUE" ;
VAL_ 239 FCODPB13P_FVTS7ZnDtdAuth 0 "FALSE" 1 "TRUE" ;
VAL_ 239 FCODPB13P_FVTS7PsdbyHstVehAuth 0 "FALSE" 1 "TRUE" ;
VAL_ 239 FCODPB13P_FVTS7PhysTypAuth 0 "Static" 1 "Variable" 2 "Temporary" ;
VAL_ 239 FCODPB13P_FVTS7MeasVldAuth 0 "FALSE" 1 "TRUE" ;
VAL_ 239 FCODPB13P_FVTS7FiltTypAuth 0 "Not Filtered" 1 "Irrelevant To Host Driver" 2 "On Vehicle/Truck" 3 "Embedded" ;
VAL_ 239 FCODPB13P_FVTS8ZnDtdAuth 0 "FALSE" 1 "TRUE" ;
VAL_ 239 FCODPB13P_FVTS8PsdbyHstVehAuth 0 "FALSE" 1 "TRUE" ;
VAL_ 239 FCODPB13P_FVTS8PhysTypAuth 0 "Static" 1 "Variable" 2 "Temporary" ;
VAL_ 239 FCODPB13P_FVTS8MeasVldAuth 0 "FALSE" 1 "TRUE" ;
VAL_ 239 FCODPB13P_FVTS8FiltTypAuth 0 "Not Filtered" 1 "Irrelevant To Host Driver" 2 "On Vehicle/Truck" 3 "Embedded" ;
VAL_ 239 FCODPB13P_FVTS9FiltTypAuth 0 "Not Filtered" 1 "Irrelevant To Host Driver" 2 "On Vehicle/Truck" 3 "Embedded" ;
VAL_ 239 FCODPB13P_FVTSTk10CnfdStsAuth 0 "Highly Speculative" 1 "Speculative" 2 "Confident" 3 "Highly Confident" ;
VAL_ 239 FCODPB13P_FVTS9ZnDtdAuth 0 "FALSE" 1 "TRUE" ;
VAL_ 239 FCODPB13P_FVTS9PsdbyHstVehAuth 0 "FALSE" 1 "TRUE" ;
VAL_ 239 FCODPB13P_FVTS9PhysTypAuth 0 "Static" 1 "Variable" 2 "Temporary" ;
VAL_ 239 FCODPB13P_FVTS9MeasVldAuth 0 "FALSE" 1 "TRUE" ;
VAL_ 239 FCODPB13P_FVTSTk10SupTypAuth 0 "None" 1 "Rain" 2 "Snow" 3 "Trailer" 4 "Time" 5 "Arrow Left" 6 "Arrow Right" 7 "Bend Arrow Left" 8 "Bend Arrow Right" 9 "Truck" 10 "Distance Arrow" 11 "Weight" 12 "Distance In" 13 "Tractor" 14 "Snow Rain" 15 "School" 16 "Rain Cloud" 17 "Fog" 18 "Hazardous" 19 "Material" 20 "Night" 21 "Supp Sign Generic" 22 "Rappel" 23 "Tractor Passable" 24 "Wet Conditions" 25 "Motorcycle" 26 "Bus" 27 "Camper" 28 "Car" 29 "Tank" 30 "Hazard Spot" 31 "Traffic Jam" 32 "Train" 33 "Tram/Street Car" 34 "Noise Prevention" 35 "Residents Only" 36 "Invalid Supp" 37 "School When Flashing" 38 "End of Speed Limit" 39 "Where Workers Present" ;
VAL_ 239 FCODPB13P_FVTSTk10MeasStsAuth 0 "No Object" 1 "New Object" 2 "Latent Track Not Detected this Cycle" 3 "Measured this Cycle" ;
VAL_ 239 FCODPB13P_FVTSTk10TypAuth 0 "No Sign Detected" 1 "End of Speed Limit" 2 "End of All Restrictions" 3 "Begin of Motorway" 4 "End of Motorway" 5 "Begin of Expressway" 6 "End of Expressway" 7 "Begin of Play Street Zone" 8 "End of Play Street Zone" 9 "Begin of Passing Restriction" 10 "End of Passing Restriction" 11 "No Entry" 12 "Begin of City Limits" 13 "End of City Limits" 14 "Yield" 15 "Crosswalk" 16 "Round About" 17 "Stop Sign" 18 "Yield to Oncoming Traffic" 19 "Pedestrian Zone" 20 "No Stopping Sign" 21 "No Parking Sign" 22 "Begin of No Parking Zone" 23 "End of No Parking Zone" 24 "Invalid Sign" 25 "Unknown Sign" 26 "Speed Limit 5" 27 "Speed Limit 10" 28 "Speed Limit 15" 29 "Speed Limit 20" 30 "Speed Limit 25" 31 "Speed Limit 30" 32 "Speed Limit 35" 33 "Speed Limit 40" 34 "Speed Limit 45" 35 "Speed Limit 50" 36 "Speed Limit 55" 37 "Speed Limit 60" 38 "Speed Limit 65" 39 "Speed Limit 70" 40 "Speed Limit 75" 41 "Speed Limit 80" 42 "Speed Limit 85" 43 "Speed Limit 90" 44 "Speed Limit 95" 45 "Speed Limit 100" 46 "Speed Limit 105" 47 "Speed Limit 110" 48 "Speed Limit 115" 49 "Speed Limit 120" 50 "Speed Limit 125" 51 "Speed Limit 130" 52 "Speed Limit 135" 53 "Speed Limit 140" 54 "Speed Limit 145" 55 "Speed Limit 150" 56 "Attention Sign Construction" 57 "Attention Sign Crosswalk" 58 "Attention Sign Round About" 59 "Attention Sign Children" 60 "Attention Sign Animals Crossing" 61 "Attention Sign General" 62 "Attention Sign Cross-way" 63 "Attention Sign Sharp Turn Left" 64 "Attention Sign Sharp Turn Right" 65 "Attention Sign Winding Road" 66 "Attention Sign Up-Grade" 67 "Attention Sign Down-Grade" 68 "Attention Sign Narrow Road Left" 69 "Attention Sign Narrow Road Right" 70 "Attention Sign Narrow Road Left & Right" 71 "Attention Sign Slippery Raod" 72 "Restricted Access for All Vehicles" 73 "Restricted Access for Cars" 74 "Restricted Access for Cars & Motorcycles" 75 "Restricted Access for Campers" ;
VAL_ 239 FCODPB13P_FVTSTk10TypCnfdAuth 0 "Highly Speculative" 1 "Speculative" 2 "Confident" 3 "Highly Confident" ;
VAL_ 239 FCODPB13P_FVTSTk1CnfdStsAuth 0 "Highly Speculative" 1 "Speculative" 2 "Confident" 3 "Highly Confident" ;
VAL_ 239 FCODPB13P_FVTSTk1MeasStsAuth 0 "No Object" 1 "New Object" 2 "Latent Track Not Detected this Cycle" 3 "Measured this Cycle" ;
VAL_ 239 FCODPB13P_FVTSTk1TypAuth 0 "No Sign Detected" 1 "End of Speed Limit" 2 "End of All Restrictions" 3 "Begin of Motorway" 4 "End of Motorway" 5 "Begin of Expressway" 6 "End of Expressway" 7 "Begin of Play Street Zone" 8 "End of Play Street Zone" 9 "Begin of Passing Restriction" 10 "End of Passing Restriction" 11 "No Entry" 12 "Begin of City Limits" 13 "End of City Limits" 14 "Yield" 15 "Crosswalk" 16 "Round About" 17 "Stop Sign" 18 "Yield to Oncoming Traffic" 19 "Pedestrian Zone" 20 "No Stopping Sign" 21 "No Parking Sign" 22 "Begin of No Parking Zone" 23 "End of No Parking Zone" 24 "Invalid Sign" 25 "Unknown Sign" 26 "Speed Limit 5" 27 "Speed Limit 10" 28 "Speed Limit 15" 29 "Speed Limit 20" 30 "Speed Limit 25" 31 "Speed Limit 30" 32 "Speed Limit 35" 33 "Speed Limit 40" 34 "Speed Limit 45" 35 "Speed Limit 50" 36 "Speed Limit 55" 37 "Speed Limit 60" 38 "Speed Limit 65" 39 "Speed Limit 70" 40 "Speed Limit 75" 41 "Speed Limit 80" 42 "Speed Limit 85" 43 "Speed Limit 90" 44 "Speed Limit 95" 45 "Speed Limit 100" 46 "Speed Limit 105" 47 "Speed Limit 110" 48 "Speed Limit 115" 49 "Speed Limit 120" 50 "Speed Limit 125" 51 "Speed Limit 130" 52 "Speed Limit 135" 53 "Speed Limit 140" 54 "Speed Limit 145" 55 "Speed Limit 150" 56 "Attention Sign Construction" 57 "Attention Sign Crosswalk" 58 "Attention Sign Round About" 59 "Attention Sign Children" 60 "Attention Sign Animals Crossing" 61 "Attention Sign General" 62 "Attention Sign Cross-way" 63 "Attention Sign Sharp Turn Left" 64 "Attention Sign Sharp Turn Right" 65 "Attention Sign Winding Road" 66 "Attention Sign Up-Grade" 67 "Attention Sign Down-Grade" 68 "Attention Sign Narrow Road Left" 69 "Attention Sign Narrow Road Right" 70 "Attention Sign Narrow Road Left & Right" 71 "Attention Sign Slippery Raod" 72 "Restricted Access for All Vehicles" 73 "Restricted Access for Cars" 74 "Restricted Access for Cars & Motorcycles" 75 "Restricted Access for Campers" ;
VAL_ 239 FCODPB13P_FVTSTk1SupTypAuth 0 "None" 1 "Rain" 2 "Snow" 3 "Trailer" 4 "Time" 5 "Arrow Left" 6 "Arrow Right" 7 "Bend Arrow Left" 8 "Bend Arrow Right" 9 "Truck" 10 "Distance Arrow" 11 "Weight" 12 "Distance In" 13 "Tractor" 14 "Snow Rain" 15 "School" 16 "Rain Cloud" 17 "Fog" 18 "Hazardous" 19 "Material" 20 "Night" 21 "Supp Sign Generic" 22 "Rappel" 23 "Tractor Passable" 24 "Wet Conditions" 25 "Motorcycle" 26 "Bus" 27 "Camper" 28 "Car" 29 "Tank" 30 "Hazard Spot" 31 "Traffic Jam" 32 "Train" 33 "Tram/Street Car" 34 "Noise Prevention" 35 "Residents Only" 36 "Invalid Supp" 37 "School When Flashing" 38 "End of Speed Limit" 39 "Where Workers Present" ;
VAL_ 239 FCODPB13P_FVTSTk1TypCnfdAuth 0 "Highly Speculative" 1 "Speculative" 2 "Confident" 3 "Highly Confident" ;
VAL_ 239 FCODPB13P_FVTSTk2CnfdStsAuth 0 "Highly Speculative" 1 "Speculative" 2 "Confident" 3 "Highly Confident" ;
VAL_ 239 FCODPB13P_FVTSTk2SupTypAuth 0 "None" 1 "Rain" 2 "Snow" 3 "Trailer" 4 "Time" 5 "Arrow Left" 6 "Arrow Right" 7 "Bend Arrow Left" 8 "Bend Arrow Right" 9 "Truck" 10 "Distance Arrow" 11 "Weight" 12 "Distance In" 13 "Tractor" 14 "Snow Rain" 15 "School" 16 "Rain Cloud" 17 "Fog" 18 "Hazardous" 19 "Material" 20 "Night" 21 "Supp Sign Generic" 22 "Rappel" 23 "Tractor Passable" 24 "Wet Conditions" 25 "Motorcycle" 26 "Bus" 27 "Camper" 28 "Car" 29 "Tank" 30 "Hazard Spot" 31 "Traffic Jam" 32 "Train" 33 "Tram/Street Car" 34 "Noise Prevention" 35 "Residents Only" 36 "Invalid Supp" 37 "School When Flashing" 38 "End of Speed Limit" 39 "Where Workers Present" ;
VAL_ 239 FCODPB13P_FVTSTk2MeasStsAuth 0 "No Object" 1 "New Object" 2 "Latent Track Not Detected this Cycle" 3 "Measured this Cycle" ;
VAL_ 239 FCODPB13P_FVTSTk2TypAuth 0 "No Sign Detected" 1 "End of Speed Limit" 2 "End of All Restrictions" 3 "Begin of Motorway" 4 "End of Motorway" 5 "Begin of Expressway" 6 "End of Expressway" 7 "Begin of Play Street Zone" 8 "End of Play Street Zone" 9 "Begin of Passing Restriction" 10 "End of Passing Restriction" 11 "No Entry" 12 "Begin of City Limits" 13 "End of City Limits" 14 "Yield" 15 "Crosswalk" 16 "Round About" 17 "Stop Sign" 18 "Yield to Oncoming Traffic" 19 "Pedestrian Zone" 20 "No Stopping Sign" 21 "No Parking Sign" 22 "Begin of No Parking Zone" 23 "End of No Parking Zone" 24 "Invalid Sign" 25 "Unknown Sign" 26 "Speed Limit 5" 27 "Speed Limit 10" 28 "Speed Limit 15" 29 "Speed Limit 20" 30 "Speed Limit 25" 31 "Speed Limit 30" 32 "Speed Limit 35" 33 "Speed Limit 40" 34 "Speed Limit 45" 35 "Speed Limit 50" 36 "Speed Limit 55" 37 "Speed Limit 60" 38 "Speed Limit 65" 39 "Speed Limit 70" 40 "Speed Limit 75" 41 "Speed Limit 80" 42 "Speed Limit 85" 43 "Speed Limit 90" 44 "Speed Limit 95" 45 "Speed Limit 100" 46 "Speed Limit 105" 47 "Speed Limit 110" 48 "Speed Limit 115" 49 "Speed Limit 120" 50 "Speed Limit 125" 51 "Speed Limit 130" 52 "Speed Limit 135" 53 "Speed Limit 140" 54 "Speed Limit 145" 55 "Speed Limit 150" 56 "Attention Sign Construction" 57 "Attention Sign Crosswalk" 58 "Attention Sign Round About" 59 "Attention Sign Children" 60 "Attention Sign Animals Crossing" 61 "Attention Sign General" 62 "Attention Sign Cross-way" 63 "Attention Sign Sharp Turn Left" 64 "Attention Sign Sharp Turn Right" 65 "Attention Sign Winding Road" 66 "Attention Sign Up-Grade" 67 "Attention Sign Down-Grade" 68 "Attention Sign Narrow Road Left" 69 "Attention Sign Narrow Road Right" 70 "Attention Sign Narrow Road Left & Right" 71 "Attention Sign Slippery Raod" 72 "Restricted Access for All Vehicles" 73 "Restricted Access for Cars" 74 "Restricted Access for Cars & Motorcycles" 75 "Restricted Access for Campers" ;
VAL_ 239 FCODPB13P_FVTSTk2TypCnfdAuth 0 "Highly Speculative" 1 "Speculative" 2 "Confident" 3 "Highly Confident" ;
VAL_ 239 FCODPB13P_FVTSTk3CnfdStsAuth 0 "Highly Speculative" 1 "Speculative" 2 "Confident" 3 "Highly Confident" ;
VAL_ 239 FCODPB13P_FVTSTk3SupTypAuth 0 "None" 1 "Rain" 2 "Snow" 3 "Trailer" 4 "Time" 5 "Arrow Left" 6 "Arrow Right" 7 "Bend Arrow Left" 8 "Bend Arrow Right" 9 "Truck" 10 "Distance Arrow" 11 "Weight" 12 "Distance In" 13 "Tractor" 14 "Snow Rain" 15 "School" 16 "Rain Cloud" 17 "Fog" 18 "Hazardous" 19 "Material" 20 "Night" 21 "Supp Sign Generic" 22 "Rappel" 23 "Tractor Passable" 24 "Wet Conditions" 25 "Motorcycle" 26 "Bus" 27 "Camper" 28 "Car" 29 "Tank" 30 "Hazard Spot" 31 "Traffic Jam" 32 "Train" 33 "Tram/Street Car" 34 "Noise Prevention" 35 "Residents Only" 36 "Invalid Supp" 37 "School When Flashing" 38 "End of Speed Limit" 39 "Where Workers Present" ;
VAL_ 239 FCODPB13P_FVTSTk3MeasStsAuth 0 "No Object" 1 "New Object" 2 "Latent Track Not Detected this Cycle" 3 "Measured this Cycle" ;
VAL_ 239 FCODPB13P_FVTSTk3TypAuth 0 "No Sign Detected" 1 "End of Speed Limit" 2 "End of All Restrictions" 3 "Begin of Motorway" 4 "End of Motorway" 5 "Begin of Expressway" 6 "End of Expressway" 7 "Begin of Play Street Zone" 8 "End of Play Street Zone" 9 "Begin of Passing Restriction" 10 "End of Passing Restriction" 11 "No Entry" 12 "Begin of City Limits" 13 "End of City Limits" 14 "Yield" 15 "Crosswalk" 16 "Round About" 17 "Stop Sign" 18 "Yield to Oncoming Traffic" 19 "Pedestrian Zone" 20 "No Stopping Sign" 21 "No Parking Sign" 22 "Begin of No Parking Zone" 23 "End of No Parking Zone" 24 "Invalid Sign" 25 "Unknown Sign" 26 "Speed Limit 5" 27 "Speed Limit 10" 28 "Speed Limit 15" 29 "Speed Limit 20" 30 "Speed Limit 25" 31 "Speed Limit 30" 32 "Speed Limit 35" 33 "Speed Limit 40" 34 "Speed Limit 45" 35 "Speed Limit 50" 36 "Speed Limit 55" 37 "Speed Limit 60" 38 "Speed Limit 65" 39 "Speed Limit 70" 40 "Speed Limit 75" 41 "Speed Limit 80" 42 "Speed Limit 85" 43 "Speed Limit 90" 44 "Speed Limit 95" 45 "Speed Limit 100" 46 "Speed Limit 105" 47 "Speed Limit 110" 48 "Speed Limit 115" 49 "Speed Limit 120" 50 "Speed Limit 125" 51 "Speed Limit 130" 52 "Speed Limit 135" 53 "Speed Limit 140" 54 "Speed Limit 145" 55 "Speed Limit 150" 56 "Attention Sign Construction" 57 "Attention Sign Crosswalk" 58 "Attention Sign Round About" 59 "Attention Sign Children" 60 "Attention Sign Animals Crossing" 61 "Attention Sign General" 62 "Attention Sign Cross-way" 63 "Attention Sign Sharp Turn Left" 64 "Attention Sign Sharp Turn Right" 65 "Attention Sign Winding Road" 66 "Attention Sign Up-Grade" 67 "Attention Sign Down-Grade" 68 "Attention Sign Narrow Road Left" 69 "Attention Sign Narrow Road Right" 70 "Attention Sign Narrow Road Left & Right" 71 "Attention Sign Slippery Raod" 72 "Restricted Access for All Vehicles" 73 "Restricted Access for Cars" 74 "Restricted Access for Cars & Motorcycles" 75 "Restricted Access for Campers" ;
VAL_ 239 FCODPB13P_FVTSTk3TypCnfdAuth 0 "Highly Speculative" 1 "Speculative" 2 "Confident" 3 "Highly Confident" ;
VAL_ 239 FCODPB13P_FVTSTk4CnfdStsAuth 0 "Highly Speculative" 1 "Speculative" 2 "Confident" 3 "Highly Confident" ;
VAL_ 239 FCODPB13P_FVTSTk4MeasStsAuth 0 "No Object" 1 "New Object" 2 "Latent Track Not Detected this Cycle" 3 "Measured this Cycle" ;
VAL_ 239 FCODPB13P_FVTSTk4TypAuth 0 "No Sign Detected" 1 "End of Speed Limit" 2 "End of All Restrictions" 3 "Begin of Motorway" 4 "End of Motorway" 5 "Begin of Expressway" 6 "End of Expressway" 7 "Begin of Play Street Zone" 8 "End of Play Street Zone" 9 "Begin of Passing Restriction" 10 "End of Passing Restriction" 11 "No Entry" 12 "Begin of City Limits" 13 "End of City Limits" 14 "Yield" 15 "Crosswalk" 16 "Round About" 17 "Stop Sign" 18 "Yield to Oncoming Traffic" 19 "Pedestrian Zone" 20 "No Stopping Sign" 21 "No Parking Sign" 22 "Begin of No Parking Zone" 23 "End of No Parking Zone" 24 "Invalid Sign" 25 "Unknown Sign" 26 "Speed Limit 5" 27 "Speed Limit 10" 28 "Speed Limit 15" 29 "Speed Limit 20" 30 "Speed Limit 25" 31 "Speed Limit 30" 32 "Speed Limit 35" 33 "Speed Limit 40" 34 "Speed Limit 45" 35 "Speed Limit 50" 36 "Speed Limit 55" 37 "Speed Limit 60" 38 "Speed Limit 65" 39 "Speed Limit 70" 40 "Speed Limit 75" 41 "Speed Limit 80" 42 "Speed Limit 85" 43 "Speed Limit 90" 44 "Speed Limit 95" 45 "Speed Limit 100" 46 "Speed Limit 105" 47 "Speed Limit 110" 48 "Speed Limit 115" 49 "Speed Limit 120" 50 "Speed Limit 125" 51 "Speed Limit 130" 52 "Speed Limit 135" 53 "Speed Limit 140" 54 "Speed Limit 145" 55 "Speed Limit 150" 56 "Attention Sign Construction" 57 "Attention Sign Crosswalk" 58 "Attention Sign Round About" 59 "Attention Sign Children" 60 "Attention Sign Animals Crossing" 61 "Attention Sign General" 62 "Attention Sign Cross-way" 63 "Attention Sign Sharp Turn Left" 64 "Attention Sign Sharp Turn Right" 65 "Attention Sign Winding Road" 66 "Attention Sign Up-Grade" 67 "Attention Sign Down-Grade" 68 "Attention Sign Narrow Road Left" 69 "Attention Sign Narrow Road Right" 70 "Attention Sign Narrow Road Left & Right" 71 "Attention Sign Slippery Raod" 72 "Restricted Access for All Vehicles" 73 "Restricted Access for Cars" 74 "Restricted Access for Cars & Motorcycles" 75 "Restricted Access for Campers" ;
VAL_ 239 FCODPB13P_FVTSTk4SupTypAuth 0 "None" 1 "Rain" 2 "Snow" 3 "Trailer" 4 "Time" 5 "Arrow Left" 6 "Arrow Right" 7 "Bend Arrow Left" 8 "Bend Arrow Right" 9 "Truck" 10 "Distance Arrow" 11 "Weight" 12 "Distance In" 13 "Tractor" 14 "Snow Rain" 15 "School" 16 "Rain Cloud" 17 "Fog" 18 "Hazardous" 19 "Material" 20 "Night" 21 "Supp Sign Generic" 22 "Rappel" 23 "Tractor Passable" 24 "Wet Conditions" 25 "Motorcycle" 26 "Bus" 27 "Camper" 28 "Car" 29 "Tank" 30 "Hazard Spot" 31 "Traffic Jam" 32 "Train" 33 "Tram/Street Car" 34 "Noise Prevention" 35 "Residents Only" 36 "Invalid Supp" 37 "School When Flashing" 38 "End of Speed Limit" 39 "Where Workers Present" ;
VAL_ 239 FCODPB13P_FVTSTk4TypCnfdAuth 0 "Highly Speculative" 1 "Speculative" 2 "Confident" 3 "Highly Confident" ;
VAL_ 239 FCODPB13P_FVTSTk5CnfdStsAuth 0 "Highly Speculative" 1 "Speculative" 2 "Confident" 3 "Highly Confident" ;
VAL_ 239 FCODPB13P_FVTSTk5SupTypAuth 0 "None" 1 "Rain" 2 "Snow" 3 "Trailer" 4 "Time" 5 "Arrow Left" 6 "Arrow Right" 7 "Bend Arrow Left" 8 "Bend Arrow Right" 9 "Truck" 10 "Distance Arrow" 11 "Weight" 12 "Distance In" 13 "Tractor" 14 "Snow Rain" 15 "School" 16 "Rain Cloud" 17 "Fog" 18 "Hazardous" 19 "Material" 20 "Night" 21 "Supp Sign Generic" 22 "Rappel" 23 "Tractor Passable" 24 "Wet Conditions" 25 "Motorcycle" 26 "Bus" 27 "Camper" 28 "Car" 29 "Tank" 30 "Hazard Spot" 31 "Traffic Jam" 32 "Train" 33 "Tram/Street Car" 34 "Noise Prevention" 35 "Residents Only" 36 "Invalid Supp" 37 "School When Flashing" 38 "End of Speed Limit" 39 "Where Workers Present" ;
VAL_ 239 FCODPB13P_FVTSTk5MeasStsAuth 0 "No Object" 1 "New Object" 2 "Latent Track Not Detected this Cycle" 3 "Measured this Cycle" ;
VAL_ 239 FCODPB13P_FVTSTk5TypAuth 0 "No Sign Detected" 1 "End of Speed Limit" 2 "End of All Restrictions" 3 "Begin of Motorway" 4 "End of Motorway" 5 "Begin of Expressway" 6 "End of Expressway" 7 "Begin of Play Street Zone" 8 "End of Play Street Zone" 9 "Begin of Passing Restriction" 10 "End of Passing Restriction" 11 "No Entry" 12 "Begin of City Limits" 13 "End of City Limits" 14 "Yield" 15 "Crosswalk" 16 "Round About" 17 "Stop Sign" 18 "Yield to Oncoming Traffic" 19 "Pedestrian Zone" 20 "No Stopping Sign" 21 "No Parking Sign" 22 "Begin of No Parking Zone" 23 "End of No Parking Zone" 24 "Invalid Sign" 25 "Unknown Sign" 26 "Speed Limit 5" 27 "Speed Limit 10" 28 "Speed Limit 15" 29 "Speed Limit 20" 30 "Speed Limit 25" 31 "Speed Limit 30" 32 "Speed Limit 35" 33 "Speed Limit 40" 34 "Speed Limit 45" 35 "Speed Limit 50" 36 "Speed Limit 55" 37 "Speed Limit 60" 38 "Speed Limit 65" 39 "Speed Limit 70" 40 "Speed Limit 75" 41 "Speed Limit 80" 42 "Speed Limit 85" 43 "Speed Limit 90" 44 "Speed Limit 95" 45 "Speed Limit 100" 46 "Speed Limit 105" 47 "Speed Limit 110" 48 "Speed Limit 115" 49 "Speed Limit 120" 50 "Speed Limit 125" 51 "Speed Limit 130" 52 "Speed Limit 135" 53 "Speed Limit 140" 54 "Speed Limit 145" 55 "Speed Limit 150" 56 "Attention Sign Construction" 57 "Attention Sign Crosswalk" 58 "Attention Sign Round About" 59 "Attention Sign Children" 60 "Attention Sign Animals Crossing" 61 "Attention Sign General" 62 "Attention Sign Cross-way" 63 "Attention Sign Sharp Turn Left" 64 "Attention Sign Sharp Turn Right" 65 "Attention Sign Winding Road" 66 "Attention Sign Up-Grade" 67 "Attention Sign Down-Grade" 68 "Attention Sign Narrow Road Left" 69 "Attention Sign Narrow Road Right" 70 "Attention Sign Narrow Road Left & Right" 71 "Attention Sign Slippery Raod" 72 "Restricted Access for All Vehicles" 73 "Restricted Access for Cars" 74 "Restricted Access for Cars & Motorcycles" 75 "Restricted Access for Campers" ;
VAL_ 239 FCODPB13P_FVTSTk5TypCnfdAuth 0 "Highly Speculative" 1 "Speculative" 2 "Confident" 3 "Highly Confident" ;
VAL_ 239 FCODPB13P_FVTSTk6CnfdStsAuth 0 "Highly Speculative" 1 "Speculative" 2 "Confident" 3 "Highly Confident" ;
VAL_ 239 FCODPB13P_FVTSTk6SupTypAuth 0 "None" 1 "Rain" 2 "Snow" 3 "Trailer" 4 "Time" 5 "Arrow Left" 6 "Arrow Right" 7 "Bend Arrow Left" 8 "Bend Arrow Right" 9 "Truck" 10 "Distance Arrow" 11 "Weight" 12 "Distance In" 13 "Tractor" 14 "Snow Rain" 15 "School" 16 "Rain Cloud" 17 "Fog" 18 "Hazardous" 19 "Material" 20 "Night" 21 "Supp Sign Generic" 22 "Rappel" 23 "Tractor Passable" 24 "Wet Conditions" 25 "Motorcycle" 26 "Bus" 27 "Camper" 28 "Car" 29 "Tank" 30 "Hazard Spot" 31 "Traffic Jam" 32 "Train" 33 "Tram/Street Car" 34 "Noise Prevention" 35 "Residents Only" 36 "Invalid Supp" 37 "School When Flashing" 38 "End of Speed Limit" 39 "Where Workers Present" ;
VAL_ 239 FCODPB13P_FVTSTk6MeasStsAuth 0 "No Object" 1 "New Object" 2 "Latent Track Not Detected this Cycle" 3 "Measured this Cycle" ;
VAL_ 239 FCODPB13P_FVTSTk6TypCnfdAuth 0 "Highly Speculative" 1 "Speculative" 2 "Confident" 3 "Highly Confident" ;
VAL_ 239 FCODPB13P_FVTSTk6TypAuth 0 "No Sign Detected" 1 "End of Speed Limit" 2 "End of All Restrictions" 3 "Begin of Motorway" 4 "End of Motorway" 5 "Begin of Expressway" 6 "End of Expressway" 7 "Begin of Play Street Zone" 8 "End of Play Street Zone" 9 "Begin of Passing Restriction" 10 "End of Passing Restriction" 11 "No Entry" 12 "Begin of City Limits" 13 "End of City Limits" 14 "Yield" 15 "Crosswalk" 16 "Round About" 17 "Stop Sign" 18 "Yield to Oncoming Traffic" 19 "Pedestrian Zone" 20 "No Stopping Sign" 21 "No Parking Sign" 22 "Begin of No Parking Zone" 23 "End of No Parking Zone" 24 "Invalid Sign" 25 "Unknown Sign" 26 "Speed Limit 5" 27 "Speed Limit 10" 28 "Speed Limit 15" 29 "Speed Limit 20" 30 "Speed Limit 25" 31 "Speed Limit 30" 32 "Speed Limit 35" 33 "Speed Limit 40" 34 "Speed Limit 45" 35 "Speed Limit 50" 36 "Speed Limit 55" 37 "Speed Limit 60" 38 "Speed Limit 65" 39 "Speed Limit 70" 40 "Speed Limit 75" 41 "Speed Limit 80" 42 "Speed Limit 85" 43 "Speed Limit 90" 44 "Speed Limit 95" 45 "Speed Limit 100" 46 "Speed Limit 105" 47 "Speed Limit 110" 48 "Speed Limit 115" 49 "Speed Limit 120" 50 "Speed Limit 125" 51 "Speed Limit 130" 52 "Speed Limit 135" 53 "Speed Limit 140" 54 "Speed Limit 145" 55 "Speed Limit 150" 56 "Attention Sign Construction" 57 "Attention Sign Crosswalk" 58 "Attention Sign Round About" 59 "Attention Sign Children" 60 "Attention Sign Animals Crossing" 61 "Attention Sign General" 62 "Attention Sign Cross-way" 63 "Attention Sign Sharp Turn Left" 64 "Attention Sign Sharp Turn Right" 65 "Attention Sign Winding Road" 66 "Attention Sign Up-Grade" 67 "Attention Sign Down-Grade" 68 "Attention Sign Narrow Road Left" 69 "Attention Sign Narrow Road Right" 70 "Attention Sign Narrow Road Left & Right" 71 "Attention Sign Slippery Raod" 72 "Restricted Access for All Vehicles" 73 "Restricted Access for Cars" 74 "Restricted Access for Cars & Motorcycles" 75 "Restricted Access for Campers" ;
VAL_ 239 FCODPB13P_FVTSTk7CnfdStsAuth 0 "Highly Speculative" 1 "Speculative" 2 "Confident" 3 "Highly Confident" ;
VAL_ 239 FCODPB13P_FVTSTk7SupTypAuth 0 "None" 1 "Rain" 2 "Snow" 3 "Trailer" 4 "Time" 5 "Arrow Left" 6 "Arrow Right" 7 "Bend Arrow Left" 8 "Bend Arrow Right" 9 "Truck" 10 "Distance Arrow" 11 "Weight" 12 "Distance In" 13 "Tractor" 14 "Snow Rain" 15 "School" 16 "Rain Cloud" 17 "Fog" 18 "Hazardous" 19 "Material" 20 "Night" 21 "Supp Sign Generic" 22 "Rappel" 23 "Tractor Passable" 24 "Wet Conditions" 25 "Motorcycle" 26 "Bus" 27 "Camper" 28 "Car" 29 "Tank" 30 "Hazard Spot" 31 "Traffic Jam" 32 "Train" 33 "Tram/Street Car" 34 "Noise Prevention" 35 "Residents Only" 36 "Invalid Supp" 37 "School When Flashing" 38 "End of Speed Limit" 39 "Where Workers Present" ;
VAL_ 239 FCODPB13P_FVTSTk7MeasStsAuth 0 "No Object" 1 "New Object" 2 "Latent Track Not Detected this Cycle" 3 "Measured this Cycle" ;
VAL_ 239 FCODPB13P_FVTSTk7TypAuth 0 "No Sign Detected" 1 "End of Speed Limit" 2 "End of All Restrictions" 3 "Begin of Motorway" 4 "End of Motorway" 5 "Begin of Expressway" 6 "End of Expressway" 7 "Begin of Play Street Zone" 8 "End of Play Street Zone" 9 "Begin of Passing Restriction" 10 "End of Passing Restriction" 11 "No Entry" 12 "Begin of City Limits" 13 "End of City Limits" 14 "Yield" 15 "Crosswalk" 16 "Round About" 17 "Stop Sign" 18 "Yield to Oncoming Traffic" 19 "Pedestrian Zone" 20 "No Stopping Sign" 21 "No Parking Sign" 22 "Begin of No Parking Zone" 23 "End of No Parking Zone" 24 "Invalid Sign" 25 "Unknown Sign" 26 "Speed Limit 5" 27 "Speed Limit 10" 28 "Speed Limit 15" 29 "Speed Limit 20" 30 "Speed Limit 25" 31 "Speed Limit 30" 32 "Speed Limit 35" 33 "Speed Limit 40" 34 "Speed Limit 45" 35 "Speed Limit 50" 36 "Speed Limit 55" 37 "Speed Limit 60" 38 "Speed Limit 65" 39 "Speed Limit 70" 40 "Speed Limit 75" 41 "Speed Limit 80" 42 "Speed Limit 85" 43 "Speed Limit 90" 44 "Speed Limit 95" 45 "Speed Limit 100" 46 "Speed Limit 105" 47 "Speed Limit 110" 48 "Speed Limit 115" 49 "Speed Limit 120" 50 "Speed Limit 125" 51 "Speed Limit 130" 52 "Speed Limit 135" 53 "Speed Limit 140" 54 "Speed Limit 145" 55 "Speed Limit 150" 56 "Attention Sign Construction" 57 "Attention Sign Crosswalk" 58 "Attention Sign Round About" 59 "Attention Sign Children" 60 "Attention Sign Animals Crossing" 61 "Attention Sign General" 62 "Attention Sign Cross-way" 63 "Attention Sign Sharp Turn Left" 64 "Attention Sign Sharp Turn Right" 65 "Attention Sign Winding Road" 66 "Attention Sign Up-Grade" 67 "Attention Sign Down-Grade" 68 "Attention Sign Narrow Road Left" 69 "Attention Sign Narrow Road Right" 70 "Attention Sign Narrow Road Left & Right" 71 "Attention Sign Slippery Raod" 72 "Restricted Access for All Vehicles" 73 "Restricted Access for Cars" 74 "Restricted Access for Cars & Motorcycles" 75 "Restricted Access for Campers" ;
VAL_ 239 FCODPB13P_FVTSTk7TypCnfdAuth 0 "Highly Speculative" 1 "Speculative" 2 "Confident" 3 "Highly Confident" ;
VAL_ 216 FCODPB14P_CnstrObj10CnfdStsAuth 0 "Highly Speculative" 1 "Speculative" 2 "Confident" 3 "Highly Confident" ;
VAL_ 216 FCODPB14P_CnstrObj11CnfdStsAuth 0 "Highly Speculative" 1 "Speculative" 2 "Confident" 3 "Highly Confident" ;
VAL_ 216 FCODPB14P_CnstrObj10TypAuth 0 "Unknown" 1 "Barrels" 2 "Cones" 3 "Marker Object" ;
VAL_ 216 FCODPB14P_CnstrObj12CnfdStsAuth 0 "Highly Speculative" 1 "Speculative" 2 "Confident" 3 "Highly Confident" ;
VAL_ 216 FCODPB14P_CnstrObj11TypAuth 0 "Unknown" 1 "Barrels" 2 "Cones" 3 "Marker Object" ;
VAL_ 216 FCODPB14P_CnstrObj12TypAuth 0 "Unknown" 1 "Barrels" 2 "Cones" 3 "Marker Object" ;
VAL_ 216 FCODPB14P_CnstrObj13CnfdStsAuth 0 "Highly Speculative" 1 "Speculative" 2 "Confident" 3 "Highly Confident" ;
VAL_ 216 FCODPB14P_CnstrObj14CnfdStsAuth 0 "Highly Speculative" 1 "Speculative" 2 "Confident" 3 "Highly Confident" ;
VAL_ 216 FCODPB14P_CnstrObj13TypAuth 0 "Unknown" 1 "Barrels" 2 "Cones" 3 "Marker Object" ;
VAL_ 216 FCODPB14P_CnstrObj15CnfdStsAuth 0 "Highly Speculative" 1 "Speculative" 2 "Confident" 3 "Highly Confident" ;
VAL_ 216 FCODPB14P_CnstrObj14TypAuth 0 "Unknown" 1 "Barrels" 2 "Cones" 3 "Marker Object" ;
VAL_ 216 FCODPB14P_CnstrObj1CnfdStsAuth 0 "Highly Speculative" 1 "Speculative" 2 "Confident" 3 "Highly Confident" ;
VAL_ 216 FCODPB14P_CnstrObj15TypAuth 0 "Unknown" 1 "Barrels" 2 "Cones" 3 "Marker Object" ;
VAL_ 216 FCODPB14P_CnstrObj1TypAuth 0 "Unknown" 1 "Barrels" 2 "Cones" 3 "Marker Object" ;
VAL_ 216 FCODPB14P_CnstrObj2CnfdStsAuth 0 "Highly Speculative" 1 "Speculative" 2 "Confident" 3 "Highly Confident" ;
VAL_ 216 FCODPB14P_CnstrObj3CnfdStsAuth 0 "Highly Speculative" 1 "Speculative" 2 "Confident" 3 "Highly Confident" ;
VAL_ 216 FCODPB14P_CnstrObj2TypAuth 0 "Unknown" 1 "Barrels" 2 "Cones" 3 "Marker Object" ;
VAL_ 216 FCODPB14P_CnstrObj4CnfdStsAuth 0 "Highly Speculative" 1 "Speculative" 2 "Confident" 3 "Highly Confident" ;
VAL_ 216 FCODPB14P_CnstrObj3TypAuth 0 "Unknown" 1 "Barrels" 2 "Cones" 3 "Marker Object" ;
VAL_ 216 FCODPB14P_CnstrObj5CnfdStsAuth 0 "Highly Speculative" 1 "Speculative" 2 "Confident" 3 "Highly Confident" ;
VAL_ 216 FCODPB14P_CnstrObj4TypAuth 0 "Unknown" 1 "Barrels" 2 "Cones" 3 "Marker Object" ;
VAL_ 216 FCODPB14P_CnstrObj5TypAuth 0 "Unknown" 1 "Barrels" 2 "Cones" 3 "Marker Object" ;
VAL_ 216 FCODPB14P_CnstrObj6CnfdStsAuth 0 "Highly Speculative" 1 "Speculative" 2 "Confident" 3 "Highly Confident" ;
VAL_ 216 FCODPB14P_CnstrObj7CnfdStsAuth 0 "Highly Speculative" 1 "Speculative" 2 "Confident" 3 "Highly Confident" ;
VAL_ 216 FCODPB14P_CnstrObj6TypAuth 0 "Unknown" 1 "Barrels" 2 "Cones" 3 "Marker Object" ;
VAL_ 216 FCODPB14P_CnstrObj8CnfdStsAuth 0 "Highly Speculative" 1 "Speculative" 2 "Confident" 3 "Highly Confident" ;
VAL_ 216 FCODPB14P_CnstrObj7TypAuth 0 "Unknown" 1 "Barrels" 2 "Cones" 3 "Marker Object" ;
VAL_ 216 FCODPB14P_CnstrObj9CnfdStsAuth 0 "Highly Speculative" 1 "Speculative" 2 "Confident" 3 "Highly Confident" ;
VAL_ 216 FCODPB14P_CnstrObj8TypAuth 0 "Unknown" 1 "Barrels" 2 "Cones" 3 "Marker Object" ;
VAL_ 216 FCODPB14P_CnstrObj9TypAuth 0 "Unknown" 1 "Barrels" 2 "Cones" 3 "Marker Object" ;
VAL_ 216 FCODPB14P_FVTSTk8CnfdStsAuth 0 "Highly Speculative" 1 "Speculative" 2 "Confident" 3 "Highly Confident" ;
VAL_ 216 FCODPB14P_FVTSTk8SupTypAuth 0 "None" 1 "Rain" 2 "Snow" 3 "Trailer" 4 "Time" 5 "Arrow Left" 6 "Arrow Right" 7 "Bend Arrow Left" 8 "Bend Arrow Right" 9 "Truck" 10 "Distance Arrow" 11 "Weight" 12 "Distance In" 13 "Tractor" 14 "Snow Rain" 15 "School" 16 "Rain Cloud" 17 "Fog" 18 "Hazardous" 19 "Material" 20 "Night" 21 "Supp Sign Generic" 22 "Rappel" 23 "Tractor Passable" 24 "Wet Conditions" 25 "Motorcycle" 26 "Bus" 27 "Camper" 28 "Car" 29 "Tank" 30 "Hazard Spot" 31 "Traffic Jam" 32 "Train" 33 "Tram/Street Car" 34 "Noise Prevention" 35 "Residents Only" 36 "Invalid Supp" 37 "School When Flashing" 38 "End of Speed Limit" 39 "Where Workers Present" ;
VAL_ 216 FCODPB14P_FVTSTk8MeasStsAuth 0 "No Object" 1 "New Object" 2 "Latent Track Not Detected this Cycle" 3 "Measured this Cycle" ;
VAL_ 216 FCODPB14P_FVTSTk8TypAuth 0 "No Sign Detected" 1 "End of Speed Limit" 2 "End of All Restrictions" 3 "Begin of Motorway" 4 "End of Motorway" 5 "Begin of Expressway" 6 "End of Expressway" 7 "Begin of Play Street Zone" 8 "End of Play Street Zone" 9 "Begin of Passing Restriction" 10 "End of Passing Restriction" 11 "No Entry" 12 "Begin of City Limits" 13 "End of City Limits" 14 "Yield" 15 "Crosswalk" 16 "Round About" 17 "Stop Sign" 18 "Yield to Oncoming Traffic" 19 "Pedestrian Zone" 20 "No Stopping Sign" 21 "No Parking Sign" 22 "Begin of No Parking Zone" 23 "End of No Parking Zone" 24 "Invalid Sign" 25 "Unknown Sign" 26 "Speed Limit 5" 27 "Speed Limit 10" 28 "Speed Limit 15" 29 "Speed Limit 20" 30 "Speed Limit 25" 31 "Speed Limit 30" 32 "Speed Limit 35" 33 "Speed Limit 40" 34 "Speed Limit 45" 35 "Speed Limit 50" 36 "Speed Limit 55" 37 "Speed Limit 60" 38 "Speed Limit 65" 39 "Speed Limit 70" 40 "Speed Limit 75" 41 "Speed Limit 80" 42 "Speed Limit 85" 43 "Speed Limit 90" 44 "Speed Limit 95" 45 "Speed Limit 100" 46 "Speed Limit 105" 47 "Speed Limit 110" 48 "Speed Limit 115" 49 "Speed Limit 120" 50 "Speed Limit 125" 51 "Speed Limit 130" 52 "Speed Limit 135" 53 "Speed Limit 140" 54 "Speed Limit 145" 55 "Speed Limit 150" 56 "Attention Sign Construction" 57 "Attention Sign Crosswalk" 58 "Attention Sign Round About" 59 "Attention Sign Children" 60 "Attention Sign Animals Crossing" 61 "Attention Sign General" 62 "Attention Sign Cross-way" 63 "Attention Sign Sharp Turn Left" 64 "Attention Sign Sharp Turn Right" 65 "Attention Sign Winding Road" 66 "Attention Sign Up-Grade" 67 "Attention Sign Down-Grade" 68 "Attention Sign Narrow Road Left" 69 "Attention Sign Narrow Road Right" 70 "Attention Sign Narrow Road Left & Right" 71 "Attention Sign Slippery Raod" 72 "Restricted Access for All Vehicles" 73 "Restricted Access for Cars" 74 "Restricted Access for Cars & Motorcycles" 75 "Restricted Access for Campers" ;
VAL_ 216 FCODPB14P_FVTSTk8TypCnfdAuth 0 "Highly Speculative" 1 "Speculative" 2 "Confident" 3 "Highly Confident" ;
VAL_ 216 FCODPB14P_FVTSTk9CnfdStsAuth 0 "Highly Speculative" 1 "Speculative" 2 "Confident" 3 "Highly Confident" ;
VAL_ 216 FCODPB14P_FVTSTk9SupTypAuth 0 "None" 1 "Rain" 2 "Snow" 3 "Trailer" 4 "Time" 5 "Arrow Left" 6 "Arrow Right" 7 "Bend Arrow Left" 8 "Bend Arrow Right" 9 "Truck" 10 "Distance Arrow" 11 "Weight" 12 "Distance In" 13 "Tractor" 14 "Snow Rain" 15 "School" 16 "Rain Cloud" 17 "Fog" 18 "Hazardous" 19 "Material" 20 "Night" 21 "Supp Sign Generic" 22 "Rappel" 23 "Tractor Passable" 24 "Wet Conditions" 25 "Motorcycle" 26 "Bus" 27 "Camper" 28 "Car" 29 "Tank" 30 "Hazard Spot" 31 "Traffic Jam" 32 "Train" 33 "Tram/Street Car" 34 "Noise Prevention" 35 "Residents Only" 36 "Invalid Supp" 37 "School When Flashing" 38 "End of Speed Limit" 39 "Where Workers Present" ;
VAL_ 216 FCODPB14P_FVTSTk9MeasStsAuth 0 "No Object" 1 "New Object" 2 "Latent Track Not Detected this Cycle" 3 "Measured this Cycle" ;
VAL_ 216 FCODPB14P_FVTSTk9TypAuth 0 "No Sign Detected" 1 "End of Speed Limit" 2 "End of All Restrictions" 3 "Begin of Motorway" 4 "End of Motorway" 5 "Begin of Expressway" 6 "End of Expressway" 7 "Begin of Play Street Zone" 8 "End of Play Street Zone" 9 "Begin of Passing Restriction" 10 "End of Passing Restriction" 11 "No Entry" 12 "Begin of City Limits" 13 "End of City Limits" 14 "Yield" 15 "Crosswalk" 16 "Round About" 17 "Stop Sign" 18 "Yield to Oncoming Traffic" 19 "Pedestrian Zone" 20 "No Stopping Sign" 21 "No Parking Sign" 22 "Begin of No Parking Zone" 23 "End of No Parking Zone" 24 "Invalid Sign" 25 "Unknown Sign" 26 "Speed Limit 5" 27 "Speed Limit 10" 28 "Speed Limit 15" 29 "Speed Limit 20" 30 "Speed Limit 25" 31 "Speed Limit 30" 32 "Speed Limit 35" 33 "Speed Limit 40" 34 "Speed Limit 45" 35 "Speed Limit 50" 36 "Speed Limit 55" 37 "Speed Limit 60" 38 "Speed Limit 65" 39 "Speed Limit 70" 40 "Speed Limit 75" 41 "Speed Limit 80" 42 "Speed Limit 85" 43 "Speed Limit 90" 44 "Speed Limit 95" 45 "Speed Limit 100" 46 "Speed Limit 105" 47 "Speed Limit 110" 48 "Speed Limit 115" 49 "Speed Limit 120" 50 "Speed Limit 125" 51 "Speed Limit 130" 52 "Speed Limit 135" 53 "Speed Limit 140" 54 "Speed Limit 145" 55 "Speed Limit 150" 56 "Attention Sign Construction" 57 "Attention Sign Crosswalk" 58 "Attention Sign Round About" 59 "Attention Sign Children" 60 "Attention Sign Animals Crossing" 61 "Attention Sign General" 62 "Attention Sign Cross-way" 63 "Attention Sign Sharp Turn Left" 64 "Attention Sign Sharp Turn Right" 65 "Attention Sign Winding Road" 66 "Attention Sign Up-Grade" 67 "Attention Sign Down-Grade" 68 "Attention Sign Narrow Road Left" 69 "Attention Sign Narrow Road Right" 70 "Attention Sign Narrow Road Left & Right" 71 "Attention Sign Slippery Raod" 72 "Restricted Access for All Vehicles" 73 "Restricted Access for Cars" 74 "Restricted Access for Cars & Motorcycles" 75 "Restricted Access for Campers" ;
VAL_ 216 FCODPB14P_FVTSTk9TypCnfdAuth 0 "Highly Speculative" 1 "Speculative" 2 "Confident" 3 "Highly Confident" ;
